CM_ "AUTOGENERATED FILE, DO NOT EDIT";

CM_ "ibooster_chassis.dbc starts here";

VERSION ""

NS_ :

BS_:

BU_:

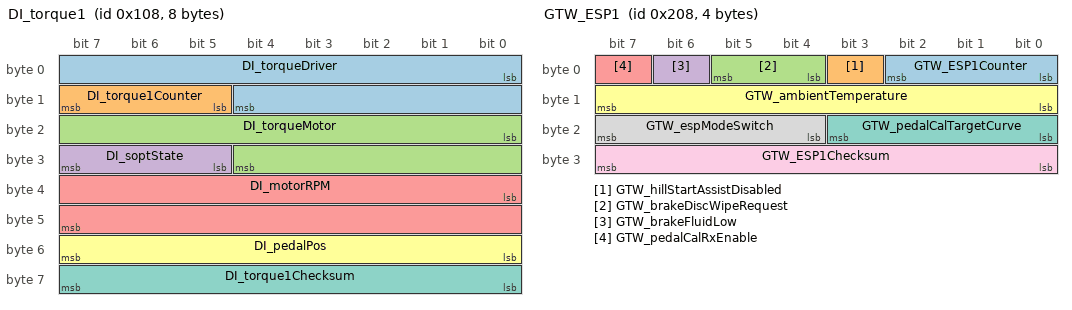
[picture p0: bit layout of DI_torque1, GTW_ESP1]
BO_ 264 DI_torque1: 8 GTW
 SG_ DI_torqueDriver : 0|13@1- (0.25,0) [-750|750] "Nm" DAS,ESP
 SG_ DI_torque1Counter : 13|3@1+ (1,0) [0|0] "" IBST,SDM,ESP,EPAS,EPAS2,EPAS3S,RCM,TAS2
 SG_ DI_torqueMotor : 16|13@1- (0.25,0) [-750|750] "Nm" APP,APS,ESP,TAS2
 SG_ DI_soptState : 29|3@1+ (1,0) [0|0] "" DBG
 SG_ DI_motorRPM : 32|16@1- (1,0) [-17000|17000] "RPM" IBST,SDM,RCM,ESP,EPAS,EPAS2,EPAS3S,EPB,EPBM,TAS2
 SG_ DI_pedalPos : 48|8@1+ (0.4,0) [0|100] "%" DAS,SDM,ESP,RCM,TAS2
 SG_ DI_torque1Checksum : 56|8@1+ (1,0) [0|0] "" IBST,SDM,ESP,EPAS,EPAS2,EPAS3S,RCM,TAS2

BO_ 516 EPB_status: 8 EPB
 SG_ EPB_state : 0|3@1+ (1,0) [0|0] "" IBST,DAS,ESP,PARK,GTW,EPBM,GTWU,RCM
 SG_ EPB_stateRequest : 3|3@1+ (1,0) [0|0] "" ESP,GTW
 SG_ EPB_brakeLight : 8|2@1+ (1,0) [0|0] "" GTW,BDY,BCCEN
 SG_ EPB_substateL : 10|3@1+ (1,0) [0|0] "" PARK,GTW,EPBM
 SG_ EPB_substateR : 13|3@1+ (1,0) [0|0] "" PARK,GTW,EPBM
 SG_ EPB_brakeHwTypeMismatch : 16|1@1+ (1,0) [0|1] "" GTW
 SG_ EPB_freeRollingModeStatus : 17|3@1+ (1,0) [0|0] "" GTW
 SG_ EPB_brakeApplied : 22|2@1+ (1,0) [0|0] "" GTW
 SG_ EPB_statePending : 24|3@1+ (1,0) [0|0] "" GTW
 SG_ EPB_calibrationStateLeft : 27|3@1+ (1,0) [0|0] "" GTW
 SG_ EPB_towModeEnabled : 32|1@1+ (1,0) [0|0] "" GTW,EPBM,GTWU
 SG_ EPB_requestUserConfirmation : 33|1@1+ (1,0) [0|0] "" GTW
 SG_ EPB_ignoreCan : 34|2@1+ (1,0) [0|3] "" GTW,EPBM,GTWU
 SG_ EPB_selfParkEnabled : 36|1@1+ (1,0) [0|3] "" GTW
 SG_ EPB_selfParkState : 37|3@1+ (1,0) [0|7] "" GTW
 SG_ EPB_mcuButtonAvailable : 40|1@1+ (1,0) [0|1] "" GTW
 SG_ EPB_telltale : 41|3@1+ (1,0) [0|0] "" GTW
 SG_ EPB_syncState : 44|3@1+ (1,0) [0|7] "" GTW
 SG_ EPB_calibrationStateRight : 47|3@1+ (1,0) [0|0] "" GTW
 SG_ EPB_statusCounter : 52|4@1+ (1,0) [0|15] "" IBST,ESP,GTW,RCM
 SG_ EPB_statusChecksum : 56|8@1+ (1,0) [0|255] "" IBST,ESP,GTW,RCM

BO_ 520 GTW_ESP1: 4 GTW
 SG_ GTW_ESP1Counter : 0|3@1+ (1,0) [0|1] "" IBST,ESP,TAS
 SG_ GTW_hillStartAssistDisabled : 3|1@1+ (1,0) [0|0] "" ESP
 SG_ GTW_brakeDiscWipeRequest : 4|2@1+ (1,0) [0|0] "" ESP
 SG_ GTW_brakeFluidLow : 6|1@1+ (1,0) [0|0] "" ESP
 SG_ GTW_pedalCalRxEnable : 7|1@1+ (1,0) [0|1] "" IBST
 SG_ GTW_ambientTemperature : 8|8@1+ (0.5,-40) [-40|60] "dgr. Celsius" BDY,BCCEN,ESP,TAS
 SG_ GTW_pedalCalTargetCurve : 16|4@1+ (1,0) [0|15] "" IBST
 SG_ GTW_espModeSwitch : 20|4@1+ (1,0) [0|15] "" ESP
 SG_ GTW_ESP1Checksum : 24|8@1+ (1,0) [0|0] "" IBST,ESP,TAS

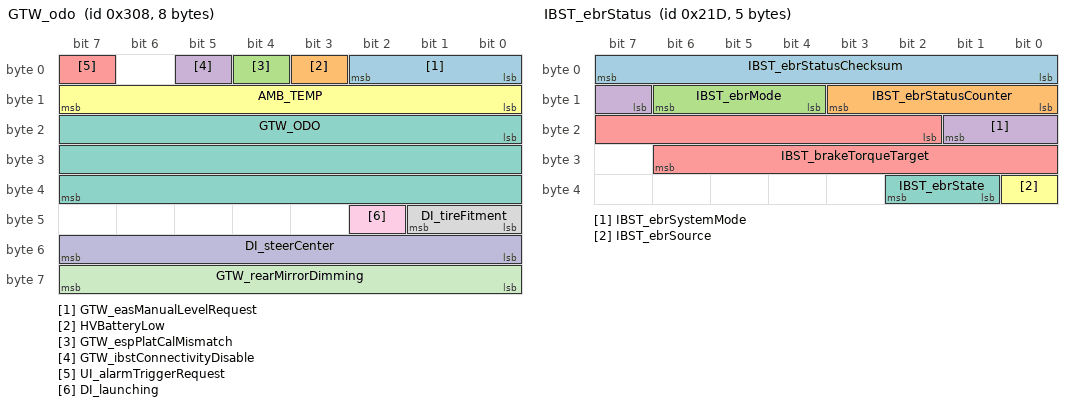
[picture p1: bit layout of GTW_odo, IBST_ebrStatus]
BO_ 776 GTW_odo: 8 GTW
 SG_ GTW_easManualLevelRequest : 0|3@1+ (1,0) [0|7] "" EAS
 SG_ HVBatteryLow : 3|1@1+ (1,0) [0|1] "" EAS,TAS
 SG_ GTW_espPlatCalMismatch : 4|1@1+ (1,0) [0|1] "" ESP
 SG_ GTW_ibstConnectivityDisable : 5|1@1+ (1,0) [0|1] "" IBST
 SG_ UI_alarmTriggerRequest : 7|1@0+ (1,0) [0|0] "" APP
 SG_ AMB_TEMP : 8|8@1+ (0.5,-40) [-40|87.5] "C" TPMS,PARK,EAS,EPB,EPBM,TAS,DAS,EPAS,EPAS2
 SG_ GTW_ODO : 16|24@1+ (0.1,0) [0|1677721.5] "km" ESP,RCM,EAS,RADAR,PARK,DAS
 SG_ DI_tireFitment : 40|2@1+ (1,0) [0|3] "" PARK,TAS2
 SG_ DI_launching : 42|1@1+ (1,0) [0|0] "" TAS2
 SG_ DI_steerCenter : 48|8@1- (0.2,0) [-25.6|25.4] "deg" TAS2
 SG_ GTW_rearMirrorDimming : 56|8@1+ (1,0) [0|255] "" APP

BO_ 840 GTW_status: 8 GTW
 SG_ GTW_driveRailReq : 0|1@0+ (1,0) [0|1] "" IBST,IC,EPB,EPBM,DAS,TAS
 SG_ GTW_brakePressed : 1|1@0+ (1,0) [0|0] "" EPB,EPBM
 SG_ GTW_driverPresent : 2|1@0+ (1,0) [0|0] "" DAS
 SG_ GTW_notEnough12VForDrive : 3|1@0+ (1,0) [0|0] "" EPB,EPBM
 SG_ GTW_icPowerOff : 4|1@0+ (1,0) [0|0] "" IC
 SG_ GTW_driverIsLeaving : 5|1@0+ (1,0) [0|0] "" EPB,EPBM
 SG_ GTW_accGoingDown : 6|1@0+ (1,0) [0|0] "" EPB,EPBM
 SG_ GTW_driveGoingDown : 7|1@0+ (1,0) [0|0] "" EPB,EPBM
 SG_ GTW_accRailReq : 8|1@0+ (1,0) [0|1] "" IBST,DAS,TAS,EPB,EPBM
 SG_ GTW_hvacRailReq : 9|1@0+ (1,0) [0|1] "" DAS
 SG_ GTW_preconditionCabinRequest : 10|1@0+ (1,0) [0|1] "" DAS
 SG_ GTW_hvacGoingDown : 11|1@1+ (1,0) [0|0] "" DAS
 SG_ GTW_ptBusAwake : 12|1@0+ (1,0) [0|0] "" EPB,EPBM
 SG_ GTW_mcuOff : 13|1@0+ (1,0) [0|0] "" APP
 SG_ GTW_hvacRailIsOn : 14|1@0+ (1,0) [0|0] "" APS
 SG_ GTW_gameModeAvailable : 15|1@0+ (1,0) [0|4] "" Vector__XXX
 SG_ GTW_vehiclePowerState : 16|1@0+ (1,0) [0|1] "" TAS
 SG_ GTW_driverIsLeavingAnySpeed : 17|1@0+ (1,0) [0|1] "" BCCEN
 SG_ DOOR_STATE_RearTrunk : 18|2@1+ (1,0) [0|3] "" EAS,TAS
 SG_ GTW_statusCounter : 51|4@0+ (1,0) [0|0] "" IC,TAS
 SG_ GTW_statusChecksum : 63|8@0+ (1,0) [0|0] "" IC,TAS

BO_ 1469 IBST_alertLog: 8 IBST
 SG_ IBST_alertID M : 0|15@1+ (1,0) [0|0] "" GTW
 SG_ IBST_alertType : 15|1@1+ (1,0) [0|0] "" GTW
 SG_ IBST_bmsInitTestFail m16384 : 16|1@1+ (1,0) [0|0] "" GTW
 SG_ IBST_bmcSingleTransTest m16385 : 16|1@1+ (1,0) [0|0] "" GTW
 SG_ IBST_tle5012SsccrcFail m16386 : 16|1@1+ (1,0) [0|0] "" GTW
 SG_ IBST_tle5012Config m16387 : 16|1@1+ (1,0) [0|0] "" GTW
 SG_ IBST_deadlMonTaskx1Ovr m16388 : 16|1@1+ (1,0) [0|0] "" GTW
 SG_ IBST_ecuWdFltCntTstFls m16389 : 16|1@1+ (1,0) [0|0] "" GTW
 SG_ IBST_ecuWdScheduleTout m16390 : 16|1@1+ (1,0) [0|0] "" GTW
 SG_ IBST_ecuWdStarttestFls m16391 : 16|1@1+ (1,0) [0|0] "" GTW
 SG_ IBST_ecuWdStatusContErr m16392 : 16|1@1+ (1,0) [0|0] "" GTW
 SG_ IBST_netOvrvolt m16393 : 16|1@1+ (1,0) [0|0] "" GTW
 SG_ IBST_micSpiTout m16394 : 16|1@1+ (1,0) [0|0] "" GTW
 SG_ IBST_micSpiTransferErr m16395 : 16|1@1+ (1,0) [0|0] "" GTW
 SG_ IBST_netUndvolt m16396 : 16|1@1+ (1,0) [0|0] "" GTW
 SG_ IBST_xpassToutErr m16397 : 16|1@1+ (1,0) [0|0] "" GTW
 SG_ IBST_rpsOffsEeReadEmpty m16398 : 16|1@1+ (1,0) [0|0] "" GTW
 SG_ IBST_rtpEnaHigh m16399 : 16|1@1+ (1,0) [0|0] "" GTW
 SG_ IBST_xpassEchoCountErr m16400 : 16|1@1+ (1,0) [0|0] "" GTW
 SG_ IBST_preDriveChckFail m16401 : 16|1@1+ (1,0) [0|0] "" GTW
 SG_ IBST_ucSafetyFlt m16402 : 16|1@1+ (1,0) [0|0] "" GTW
 SG_ IBST_unsupportedHw m16403 : 16|1@1+ (1,0) [0|0] "" GTW
 SG_ IBST_voltPreRegModeFld m16404 : 16|1@1+ (1,0) [0|0] "" GTW
 SG_ IBST_ubbSupplyLine m16405 : 16|1@1+ (1,0) [0|0] "" GTW
 SG_ IBST_stmAswSysTout m16406 : 16|1@1+ (1,0) [0|0] "" GTW
 SG_ IBST_stackOvrUndFlow m16407 : 16|1@1+ (1,0) [0|0] "" GTW
 SG_ IBST_smmOneReqsInit m16408 : 16|1@1+ (1,0) [0|0] "" GTW
 SG_ IBST_ptsSupply m16409 : 16|1@1+ (1,0) [0|0] "" GTW
 SG_ IBST_ptsSupplyUndvolt m16410 : 16|1@1+ (1,0) [0|0] "" GTW
 SG_ IBST_tempB6Plaus m16411 : 16|1@1+ (1,0) [0|0] "" GTW
 SG_ IBST_ecuWdErrCntContErr m16412 : 16|1@1+ (1,0) [0|0] "" GTW
 SG_ IBST_bmcShortedGateTest m16413 : 16|1@1+ (1,0) [0|0] "" GTW
 SG_ IBST_controllerDevTooBig m16414 : 16|1@1+ (1,0) [0|0] "" GTW
 SG_ IBST_ibDtrFail m16415 : 16|1@1+ (1,0) [0|0] "" GTW
 SG_ IBST_oc6InitTestFail m16416 : 16|1@1+ (1,0) [0|0] "" GTW
 SG_ IBST_oc6Monitor m16417 : 16|1@1+ (1,0) [0|0] "" GTW
 SG_ IBST_motorOscillationDet m16418 : 16|1@1+ (1,0) [0|0] "" GTW
 SG_ IBST_rpsOffsEeReadFail m16419 : 16|1@1+ (1,0) [0|0] "" GTW
 SG_ IBST_sysErrHook m16420 : 16|1@1+ (1,0) [0|0] "" GTW
 SG_ IBST_calIdlePosNotPlaus m16421 : 16|1@1+ (1,0) [0|0] "" GTW
 SG_ IBST_boostSupUndrvolt m16422 : 16|1@1+ (1,0) [0|0] "" GTW
 SG_ IBST_calRoutineAbort m16423 : 16|1@1+ (1,0) [0|0] "" GTW
 SG_ IBST_bmcGateUndervoltPro m16424 : 16|1@1+ (1,0) [0|0] "" GTW
 SG_ IBST_hswInitPhseUndrvolt m16425 : 16|1@1+ (1,0) [0|0] "" GTW
 SG_ IBST_ltmWarnLevelReached m16426 : 16|1@1+ (1,0) [0|0] "" GTW
 SG_ IBST_rpsVctrLengthRelErr m16427 : 16|1@1+ (1,0) [0|0] "" GTW
 SG_ IBST_b6TempDegradeLevel1 m16428 : 16|1@1+ (1,0) [0|0] "" GTW
 SG_ IBST_B6TempDegradeLevel2 m16429 : 16|1@1+ (1,0) [0|0] "" GTW
 SG_ IBST_spiAnglOrRawNotUp m16430 : 16|1@1+ (1,0) [0|0] "" GTW
 SG_ IBST_dcomIboosterNotInit m16431 : 16|1@1+ (1,0) [0|0] "" GTW
 SG_ IBST_unintendMotorReturn m16432 : 16|1@1+ (1,0) [0|0] "" GTW
 SG_ IBST_cdmOvrvoltLevel1 m16433 : 16|1@1+ (1,0) [0|0] "" GTW
 SG_ IBST_cdmUndrvoltLevel2 m16434 : 16|1@1+ (1,0) [0|0] "" GTW
 SG_ IBST_cdmUndrvoltLevel1 m16435 : 16|1@1+ (1,0) [0|0] "" GTW
 SG_ IBST_motTrvlRelReadFail m16436 : 16|1@1+ (1,0) [0|0] "" GTW
 SG_ IBST_tle5012UnexpReset m16437 : 16|1@1+ (1,0) [0|0] "" GTW
 SG_ IBST_bmsGateUndrvolt m16438 : 16|1@1+ (1,0) [0|0] "" GTW
 SG_ IBST_kl15HwPlausSw m16439 : 16|1@1+ (1,0) [0|0] "" GTW
 SG_ IBST_ibNotShutDownRight m16440 : 16|1@1+ (1,0) [0|0] "" GTW
 SG_ IBST_cdmHardUndrvolt m16441 : 16|1@1+ (1,0) [0|0] "" GTW
 SG_ IBST_cdmHardOvrvolt m16442 : 16|1@1+ (1,0) [0|0] "" GTW
 SG_ IBST_maxTrvlAdjstUpdFail m16443 : 16|1@1+ (1,0) [0|0] "" GTW
 SG_ IBST_ltmLimitReached m16444 : 16|1@1+ (1,0) [0|0] "" GTW
 SG_ IBST_dcomEcuDefect m16445 : 16|1@1+ (1,0) [0|0] "" GTW
 SG_ IBST_inputStroke1RngHigh m16446 : 16|1@1+ (1,0) [0|0] "" GTW
 SG_ IBST_inputStroke1RngLow m16447 : 16|1@1+ (1,0) [0|0] "" GTW
 SG_ IBST_inputStroke2RngHigh m16448 : 16|1@1+ (1,0) [0|0] "" GTW
 SG_ IBST_inputStroke2RngLow m16449 : 16|1@1+ (1,0) [0|0] "" GTW
 SG_ IBST_ibSupVoltDivDrift m16450 : 16|1@1+ (1,0) [0|0] "" GTW
 SG_ IBST_sOutRodToPressVal m16451 : 16|1@1+ (1,0) [0|0] "" GTW
 SG_ IBST_tle5012LifeCnt m16452 : 16|1@1+ (1,0) [0|0] "" GTW
 SG_ IBST_cdmExtendedUndrvolt m16453 : 16|1@1+ (1,0) [0|0] "" GTW
 SG_ IBST_cdmExtendedOvrvolt m16454 : 16|1@1+ (1,0) [0|0] "" GTW
 SG_ IBST_tempB6Ch1LineHigh m16455 : 16|1@1+ (1,0) [0|0] "" GTW
 SG_ IBST_tempB6Ch1LineLow m16456 : 16|1@1+ (1,0) [0|0] "" GTW
 SG_ IBST_tempB6Ch2LineHigh m16457 : 16|1@1+ (1,0) [0|0] "" GTW
 SG_ IBST_tempB6Ch2LineLow m16458 : 16|1@1+ (1,0) [0|0] "" GTW
 SG_ IBST_hevSwitchOffDcom m16459 : 16|1@1+ (1,0) [0|0] "" GTW
 SG_ IBST_tle5012VoltFail m16460 : 16|1@1+ (1,0) [0|0] "" GTW
 SG_ IBST_bcsFltCurrentHigh m16461 : 16|1@1+ (1,0) [0|0] "" GTW
 SG_ IBST_bcsFltCurrentLow m16462 : 16|1@1+ (1,0) [0|0] "" GTW
 SG_ IBST_ecuSupVoltDivDrift m16463 : 16|1@1+ (1,0) [0|0] "" GTW
 SG_ IBST_inputstroke1Grad m16464 : 16|1@1+ (1,0) [0|0] "" GTW
 SG_ IBST_pts1Err m16465 : 16|1@1+ (1,0) [0|0] "" GTW
 SG_ IBST_pts1LineGnd m16466 : 16|1@1+ (1,0) [0|0] "" GTW
 SG_ IBST_pts1LineHigh m16467 : 16|1@1+ (1,0) [0|0] "" GTW
 SG_ IBST_inputStroke2Grad m16468 : 16|1@1+ (1,0) [0|0] "" GTW
 SG_ IBST_pts2Err m16469 : 16|1@1+ (1,0) [0|0] "" GTW
 SG_ IBST_pts2LineGnd m16470 : 16|1@1+ (1,0) [0|0] "" GTW
 SG_ IBST_pts2LineHigh m16471 : 16|1@1+ (1,0) [0|0] "" GTW
 SG_ IBST_faildevInputStroke m16472 : 16|1@1+ (1,0) [0|0] "" GTW
 SG_ IBST_ptsOffsTooHigh m16473 : 16|1@1+ (1,0) [0|0] "" GTW
 SG_ IBST_pbistErr m16474 : 16|1@1+ (1,0) [0|0] "" GTW
 SG_ IBST_ramInitErr m16475 : 16|1@1+ (1,0) [0|0] "" GTW
 SG_ IBST_ramsinlgeFlt m16476 : 16|1@1+ (1,0) [0|0] "" GTW
 SG_ IBST_bertFlt m16477 : 16|1@1+ (1,0) [0|0] "" GTW
 SG_ IBST_CalDataNotPlaus m16478 : 16|1@1+ (1,0) [0|0] "" GTW
 SG_ IBST_canEHwError m16479 : 16|1@1+ (1,0) [0|0] "" GTW
 SG_ IBST_canETout m16480 : 16|1@1+ (1,0) [0|0] "" GTW
 SG_ IBST_cpuException m16481 : 16|1@1+ (1,0) [0|0] "" GTW
 SG_ IBST_ecuBandGap m16482 : 16|1@1+ (1,0) [0|0] "" GTW
 SG_ IBST_ecuBmsOnWhileWdTout m16483 : 16|1@1+ (1,0) [0|0] "" GTW
 SG_ IBST_ecuErrpinCntTstFls m16484 : 16|1@1+ (1,0) [0|0] "" GTW
 SG_ IBST_ecuHetException m16485 : 16|1@1+ (1,0) [0|0] "" GTW
 SG_ IBST_ecuHetTuAddErr m16486 : 16|1@1+ (1,0) [0|0] "" GTW
 SG_ IBST_ecuHetTuBusErr m16487 : 16|1@1+ (1,0) [0|0] "" GTW
 SG_ IBST_ecuHetTuBusyErr m16488 : 16|1@1+ (1,0) [0|0] "" GTW
 SG_ IBST_ecuHetTuException m16489 : 16|1@1+ (1,0) [0|0] "" GTW
 SG_ IBST_ecuTaskMissing m16490 : 16|1@1+ (1,0) [0|0] "" GTW
 SG_ IBST_hetRefError m16491 : 16|1@1+ (1,0) [0|0] "" GTW
 SG_ IBST_micInitSpiTstFld m16492 : 16|1@1+ (1,0) [0|0] "" GTW
 SG_ IBST_micInitSpiTransfErr m16493 : 16|1@1+ (1,0) [0|0] "" GTW
 SG_ IBST_micIntMonGenBitMon m16494 : 16|1@1+ (1,0) [0|0] "" GTW
 SG_ IBST_micIntVoltMonFld m16495 : 16|1@1+ (1,0) [0|0] "" GTW
 SG_ IBST_motPosTrvlReadEmpty m16496 : 16|1@1+ (1,0) [0|0] "" GTW
 SG_ IBST_motAngBoundReadEmpt m16497 : 16|1@1+ (1,0) [0|0] "" GTW
 SG_ IBST_motShaftShiftDetect m16498 : 16|1@1+ (1,0) [0|0] "" GTW
 SG_ IBST_osErrHook m16499 : 16|1@1+ (1,0) [0|0] "" GTW
 SG_ IBST_pdurEInitFail m16500 : 16|1@1+ (1,0) [0|0] "" GTW
 SG_ IBST_pdurEPduInstLost m16501 : 16|1@1+ (1,0) [0|0] "" GTW
 SG_ IBST_pts1OffsEeReadEmpty m16502 : 16|1@1+ (1,0) [0|0] "" GTW
 SG_ IBST_pts2OffsEeReadEmpty m16503 : 16|1@1+ (1,0) [0|0] "" GTW
 SG_ IBST_rpsOffsXEeReadFail m16504 : 16|1@1+ (1,0) [0|0] "" GTW
 SG_ IBST_rpsOffsYEeReadFail m16505 : 16|1@1+ (1,0) [0|0] "" GTW
 SG_ IBST_rpsSynchEeReadFail m16506 : 16|1@1+ (1,0) [0|0] "" GTW
 SG_ IBST_rpsAnglRecalcErr m16507 : 16|1@1+ (1,0) [0|0] "" GTW
 SG_ IBST_motTrvlRelWriteFail m16508 : 16|1@1+ (1,0) [0|0] "" GTW
 SG_ IBST_motTrvlRelReadEmpty m16509 : 16|1@1+ (1,0) [0|0] "" GTW
 SG_ IBST_ptsEeReadEmpty m16510 : 16|1@1+ (1,0) [0|0] "" GTW
 SG_ IBST_ecuAdcConversionErr m16511 : 16|1@1+ (1,0) [0|0] "" GTW
 SG_ IBST_ecuAdcSelftestErr m16512 : 16|1@1+ (1,0) [0|0] "" GTW
 SG_ IBST_ccmFlt m16513 : 16|1@1+ (1,0) [0|0] "" GTW
 SG_ IBST_ecuRomCheck m16514 : 16|1@1+ (1,0) [0|0] "" GTW
 SG_ IBST_esmNmiFlt m16515 : 16|1@1+ (1,0) [0|0] "" GTW
 SG_ IBST_esmSafetyFlt m16516 : 16|1@1+ (1,0) [0|0] "" GTW
 SG_ IBST_motPosTrvlReadFail m16517 : 16|1@1+ (1,0) [0|0] "" GTW
 SG_ IBST_motPosTrvlWriteFail m16518 : 16|1@1+ (1,0) [0|0] "" GTW
 SG_ IBST_motAnglBndReadErr m16519 : 16|1@1+ (1,0) [0|0] "" GTW
 SG_ IBST_motAnglBndWriteErr m16520 : 16|1@1+ (1,0) [0|0] "" GTW
 SG_ IBST_motAnglGradTooLarge m16521 : 16|1@1+ (1,0) [0|0] "" GTW
 SG_ IBST_pdmCustomerIdMis m16522 : 16|1@1+ (1,0) [0|0] "" GTW
 SG_ IBST_pdmDtFormatMis m16523 : 16|1@1+ (1,0) [0|0] "" GTW
 SG_ IBST_pdmOutOfMemory m16524 : 16|1@1+ (1,0) [0|0] "" GTW
 SG_ IBST_pdmFieldSizeMis m16525 : 16|1@1+ (1,0) [0|0] "" GTW
 SG_ IBST_pdmHwAcsErr m16526 : 16|1@1+ (1,0) [0|0] "" GTW
 SG_ IBST_pdmMaxWriteCycles m16526 : 17|1@1+ (1,0) [0|0] "" GTW
 SG_ IBST_pdmInternalHWErr m16527 : 16|1@1+ (1,0) [0|0] "" GTW
 SG_ IBST_ptsCalHysWritFail m16528 : 16|1@1+ (1,0) [0|0] "" GTW
 SG_ IBST_ptsCalValuesChkFail m16529 : 16|1@1+ (1,0) [0|0] "" GTW
 SG_ IBST_pts1CalEeReadFail m16530 : 16|1@1+ (1,0) [0|0] "" GTW
 SG_ IBST_pts1CalEeWriteFail m16531 : 16|1@1+ (1,0) [0|0] "" GTW
 SG_ IBST_rpsFailCompErr m16532 : 16|1@1+ (1,0) [0|0] "" GTW
 SG_ IBST_pts1OffsEeWriteFail m16533 : 16|1@1+ (1,0) [0|0] "" GTW
 SG_ IBST_pts2CalEeReadFail m16534 : 16|1@1+ (1,0) [0|0] "" GTW
 SG_ IBST_pts2CalEeWriteFail m16535 : 16|1@1+ (1,0) [0|0] "" GTW
 SG_ IBST_pts2OffsEeReadFail m16536 : 16|1@1+ (1,0) [0|0] "" GTW
 SG_ IBST_pts2OffsEeWriteFail m16537 : 16|1@1+ (1,0) [0|0] "" GTW
 SG_ IBST_rpsOffsXEeReadEmpty m16538 : 16|1@1+ (1,0) [0|0] "" GTW
 SG_ IBST_rpsOffsXEeWriteFail m16539 : 16|1@1+ (1,0) [0|0] "" GTW
 SG_ IBST_rpsOffsYEeReadEmpty m16540 : 16|1@1+ (1,0) [0|0] "" GTW
 SG_ IBST_rpsOffsYEeWriteFail m16541 : 16|1@1+ (1,0) [0|0] "" GTW
 SG_ IBST_rpsSynchEeReadEmpty m16542 : 16|1@1+ (1,0) [0|0] "" GTW
 SG_ IBST_rpsSynchEeWriteFail m16543 : 16|1@1+ (1,0) [0|0] "" GTW
 SG_ IBST_assertionFail m16544 : 16|1@1+ (1,0) [0|0] "" GTW
 SG_ IBST_comsclBrkPrsPduLen m16545 : 16|1@1+ (1,0) [0|0] "" GTW
 SG_ IBST_comsclBrkPrsPduTout m16546 : 16|1@1+ (1,0) [0|0] "" GTW
 SG_ IBST_comsclEspIb1CntErr m16547 : 16|1@1+ (1,0) [0|0] "" GTW
 SG_ IBST_comsclEspIb1CsErr m16548 : 16|1@1+ (1,0) [0|0] "" GTW
 SG_ IBST_comsclEspIb1DlcErr m16549 : 16|1@1+ (1,0) [0|0] "" GTW
 SG_ IBST_comsclEspIb1Tout m16550 : 16|1@1+ (1,0) [0|0] "" GTW
 SG_ IBST_comsclEspIb2CntErr m16551 : 16|1@1+ (1,0) [0|0] "" GTW
 SG_ IBST_comsclEspIb2CsErr m16552 : 16|1@1+ (1,0) [0|0] "" GTW
 SG_ IBST_comsclEspIb2DlcErr m16553 : 16|1@1+ (1,0) [0|0] "" GTW
 SG_ IBST_comsclEspIb2Tout m16554 : 16|1@1+ (1,0) [0|0] "" GTW
 SG_ IBST_comsclEspIb3CntErr m16555 : 16|1@1+ (1,0) [0|0] "" GTW
 SG_ IBST_comsclEspIb3CsErr m16556 : 16|1@1+ (1,0) [0|0] "" GTW
 SG_ IBST_comsclEspIb3DlcErr m16557 : 16|1@1+ (1,0) [0|0] "" GTW
 SG_ IBST_comsclEspIb3Tout m16558 : 16|1@1+ (1,0) [0|0] "" GTW
 SG_ IBST_comsclGtwEsp1CntErr m16559 : 16|1@1+ (1,0) [0|0] "" GTW
 SG_ IBST_comsclGtwEsp1CsErr m16560 : 16|1@1+ (1,0) [0|0] "" GTW
 SG_ IBST_comsclGtwEsp1Corrpt m16561 : 16|1@1+ (1,0) [0|0] "" GTW
 SG_ IBST_comsclGtwEsp1Tout m16562 : 16|1@1+ (1,0) [0|0] "" GTW
 SG_ IBST_dcomSmrtActuNotInit m16563 : 16|1@1+ (1,0) [0|0] "" GTW
 SG_ IBST_rpsLengthAbsolHigh m16564 : 16|1@1+ (1,0) [0|0] "" GTW
 SG_ IBST_rpsLengthAbsolLow m16565 : 16|1@1+ (1,0) [0|0] "" GTW
 SG_ IBST_shutDownEeReadFail m16566 : 16|1@1+ (1,0) [0|0] "" GTW
 SG_ IBST_shutDownEeWriteFail m16567 : 16|1@1+ (1,0) [0|0] "" GTW
 SG_ IBST_maxTrvlAdjstReadErr m16568 : 16|1@1+ (1,0) [0|0] "" GTW
 SG_ IBST_psOffsMcEeReadFail m16569 : 16|1@1+ (1,0) [0|0] "" GTW
 SG_ IBST_psOffsMcEeWriteFail m16570 : 16|1@1+ (1,0) [0|0] "" GTW
 SG_ IBST_ltmSelfProtDeact m16571 : 16|1@1+ (1,0) [0|0] "" GTW
 SG_ IBST_pts1OffsEeReadFail m16572 : 16|1@1+ (1,0) [0|0] "" GTW
 SG_ IBST_diffStrokeRange m16573 : 16|1@1+ (1,0) [0|0] "" GTW
 SG_ IBST_notProgVin m16574 : 16|1@1+ (1,0) [0|0] "" GTW
 SG_ IBST_plausVin m16575 : 16|1@1+ (1,0) [0|0] "" GTW
 SG_ IBST_dlCorCSumVin m16576 : 16|1@1+ (1,0) [0|0] "" GTW
 SG_ IBST_ToutVin m16577 : 16|1@1+ (1,0) [0|0] "" GTW
 SG_ IBST_ecuEnableB6Fail m16578 : 16|1@1+ (1,0) [0|0] "" GTW
 SG_ IBST_ecuIbEnContErr m16579 : 16|1@1+ (1,0) [0|0] "" GTW
 SG_ IBST_sclEspIb1pEstMax m16580 : 16|1@1+ (1,0) [0|0] "" GTW
 SG_ IBST_sclEspIb1VehSpd m16581 : 16|1@1+ (1,0) [0|0] "" GTW
 SG_ IBST_sclEspIb2pLimExt m16582 : 16|1@1+ (1,0) [0|0] "" GTW
 SG_ IBST_sclEspIb2qTarExt m16583 : 16|1@1+ (1,0) [0|0] "" GTW
 SG_ IBST_sclEspIb3pFBlend m16584 : 16|1@1+ (1,0) [0|0] "" GTW
 SG_ IBST_sclEspIb3pMc1 m16585 : 16|1@1+ (1,0) [0|0] "" GTW
 SG_ IBST_sclEspIb3pTarDriver m16586 : 16|1@1+ (1,0) [0|0] "" GTW
 SG_ IBST_netBusOffNet0 m16587 : 16|1@1+ (1,0) [0|0] "" GTW
 SG_ IBST_netErrPassivNet0 m16588 : 16|1@1+ (1,0) [0|0] "" GTW
 SG_ IBST_netBusOffNet1 m16589 : 16|1@1+ (1,0) [0|0] "" GTW
 SG_ IBST_netErrPassivNet1 m16590 : 16|1@1+ (1,0) [0|0] "" GTW
 SG_ IBST_maxStrokeReached m16591 : 16|1@1+ (1,0) [0|0] "" GTW
 SG_ IBST_sysSwClockMismatch m16592 : 16|1@1+ (1,0) [0|0] "" GTW
 SG_ IBST_comsclGtwOdoCorrpt m16593 : 16|1@1+ (1,0) [0|0] "" GTW
 SG_ IBST_comsclGtwStatCorrpt m16594 : 16|1@1+ (1,0) [0|0] "" GTW
 SG_ IBST_comsclEpbStatCorrpt m16595 : 16|1@1+ (1,0) [0|0] "" GTW
 SG_ IBST_comsclGtwOdoTout m16596 : 16|1@1+ (1,0) [0|0] "" GTW
 SG_ IBST_comsclGtwStatTout m16597 : 16|1@1+ (1,0) [0|0] "" GTW
 SG_ IBST_comsclEpbStatTout m16598 : 16|1@1+ (1,0) [0|0] "" GTW
 SG_ IBST_comSclEpbStatCsErr m16599 : 16|1@1+ (1,0) [0|0] "" GTW
 SG_ IBST_comSclEpbStatCntFlt m16600 : 16|1@1+ (1,0) [0|0] "" GTW
 SG_ IBST_comSclDiTrq1Tout m16601 : 16|1@1+ (1,0) [0|0] "" GTW
 SG_ IBST_comSclDiTrq1Corrpt m16602 : 16|1@1+ (1,0) [0|0] "" GTW
 SG_ IBST_comSclDiTrq1CsErr m16603 : 16|1@1+ (1,0) [0|0] "" GTW
 SG_ IBST_comSclDiTrq1CntFlt m16604 : 16|1@1+ (1,0) [0|0] "" GTW

BO_ 1645 IBST_bootID: 8 IBST
 SG_ IBST_bootIdData : 0|64@1+ (1,0) [0|0] "" Vector__XXX

BO_ 861 IBST_dtcMatrix: 8 IBST
 SG_ IBST_dtcIndex M : 0|8@1+ (1,0) [0|255] "" GTW
 SG_ IBST_d000_bmsInitTestFail m0 : 8|2@1+ (1,0) [0|0] "" GTW
 SG_ IBST_d001_bmcSingleTransTest m0 : 10|2@1+ (1,0) [0|0] "" GTW
 SG_ IBST_d002_tle5012SsccrcFail m0 : 12|2@1+ (1,0) [0|0] "" GTW
 SG_ IBST_d003_tle5012Config m0 : 14|2@1+ (1,0) [0|0] "" GTW
 SG_ IBST_d004_deadlMonTaskx1Ovr m0 : 16|2@1+ (1,0) [0|0] "" GTW
 SG_ IBST_d005_ecuWdFltCntTstFls m0 : 18|2@1+ (1,0) [0|0] "" GTW
 SG_ IBST_d006_ecuWdScheduleTout m0 : 20|2@1+ (1,0) [0|0] "" GTW
 SG_ IBST_d007_ecuWdStarttestFls m0 : 22|2@1+ (1,0) [0|0] "" GTW
 SG_ IBST_d008_ecuWdStatusContErr m0 : 24|2@1+ (1,0) [0|0] "" GTW
 SG_ IBST_d009_netOvrvolt m0 : 26|2@1+ (1,0) [0|0] "" GTW
 SG_ IBST_d010_micSpiTout m0 : 28|2@1+ (1,0) [0|0] "" GTW
 SG_ IBST_d011_micSpiTransferErr m0 : 30|2@1+ (1,0) [0|0] "" GTW
 SG_ IBST_d012_netUndvolt m0 : 32|2@1+ (1,0) [0|0] "" GTW
 SG_ IBST_d013_xpassToutErr m0 : 34|2@1+ (1,0) [0|0] "" GTW
 SG_ IBST_d014_rpsOffsEeReadEmpty m0 : 36|2@1+ (1,0) [0|0] "" GTW
 SG_ IBST_d015_rtpEnaHigh m0 : 38|2@1+ (1,0) [0|0] "" GTW
 SG_ IBST_d016_xpassEchoCountErr m0 : 40|2@1+ (1,0) [0|0] "" GTW
 SG_ IBST_d017_preDriveChckFail m0 : 42|2@1+ (1,0) [0|0] "" GTW
 SG_ IBST_d018_ucSafetyFlt m0 : 44|2@1+ (1,0) [0|0] "" GTW
 SG_ IBST_d019_unsupportedHw m0 : 46|2@1+ (1,0) [0|0] "" GTW
 SG_ IBST_d020_voltPreRegModeFld m0 : 48|2@1+ (1,0) [0|0] "" GTW
 SG_ IBST_d021_ubbSupplyLine m0 : 50|2@1+ (1,0) [0|0] "" GTW
 SG_ IBST_d022_stmAswSysTout m0 : 52|2@1+ (1,0) [0|0] "" GTW
 SG_ IBST_d023_stackOvrUndFlow m0 : 54|2@1+ (1,0) [0|0] "" GTW
 SG_ IBST_d024_smmOneReqsInit m0 : 56|2@1+ (1,0) [0|0] "" GTW
 SG_ IBST_d025_ptsSupply m0 : 58|2@1+ (1,0) [0|0] "" GTW
 SG_ IBST_d026_ptsSupplyUndvolt m0 : 60|2@1+ (1,0) [0|0] "" GTW
 SG_ IBST_d027_tempB6Plaus m0 : 62|2@1+ (1,0) [0|0] "" GTW
 SG_ IBST_d028_ecuWdErrCntContErr m1 : 8|2@1+ (1,0) [0|0] "" GTW
 SG_ IBST_d029_bmcShortedGateTest m1 : 10|2@1+ (1,0) [0|0] "" GTW
 SG_ IBST_d030_controllerDevTooBig m1 : 12|2@1+ (1,0) [0|0] "" GTW
 SG_ IBST_d031_ibDtrFail m1 : 14|2@1+ (1,0) [0|0] "" GTW
 SG_ IBST_d032_oc6InitTestFail m1 : 16|2@1+ (1,0) [0|0] "" GTW
 SG_ IBST_d033_oc6Monitor m1 : 18|2@1+ (1,0) [0|0] "" GTW
 SG_ IBST_d034_motorOscillationDet m1 : 20|2@1+ (1,0) [0|0] "" GTW
 SG_ IBST_d035_rpsOffsEeReadFail m1 : 22|2@1+ (1,0) [0|0] "" GTW
 SG_ IBST_d036_sysErrHook m1 : 24|2@1+ (1,0) [0|0] "" GTW
 SG_ IBST_d037_calIdlePosNotPlaus m1 : 26|2@1+ (1,0) [0|0] "" GTW
 SG_ IBST_d038_boostSupUndrvolt m1 : 28|2@1+ (1,0) [0|0] "" GTW
 SG_ IBST_d039_calRoutineAbort m1 : 30|2@1+ (1,0) [0|0] "" GTW
 SG_ IBST_d040_bmcGateUndervoltPro m1 : 32|2@1+ (1,0) [0|0] "" GTW
 SG_ IBST_d041_hswInitPhseUndrvolt m1 : 34|2@1+ (1,0) [0|0] "" GTW
 SG_ IBST_d042_ltmWarnLevelReached m1 : 36|2@1+ (1,0) [0|0] "" GTW
 SG_ IBST_d043_rpsVctrLengthRelErr m1 : 38|2@1+ (1,0) [0|0] "" GTW
 SG_ IBST_d044_b6TempDegradeLevel1 m1 : 40|2@1+ (1,0) [0|0] "" GTW
 SG_ IBST_d045_B6TempDegradeLevel2 m1 : 42|2@1+ (1,0) [0|0] "" GTW
 SG_ IBST_d046_spiAnglOrRawNotUp m1 : 44|2@1+ (1,0) [0|0] "" GTW
 SG_ IBST_d047_dcomIboosterNotInit m1 : 46|2@1+ (1,0) [0|0] "" GTW
 SG_ IBST_d048_unintendMotorReturn m1 : 48|2@1+ (1,0) [0|0] "" GTW
 SG_ IBST_d049_cdmOvrvoltLevel1 m1 : 50|2@1+ (1,0) [0|0] "" GTW
 SG_ IBST_d050_cdmUndrvoltLevel2 m1 : 52|2@1+ (1,0) [0|0] "" GTW
 SG_ IBST_d051_cdmUndrvoltLevel1 m1 : 54|2@1+ (1,0) [0|0] "" GTW
 SG_ IBST_d052_motTrvlRelReadFail m1 : 56|2@1+ (1,0) [0|0] "" GTW
 SG_ IBST_d053_tle5012UnexpReset m1 : 58|2@1+ (1,0) [0|0] "" GTW
 SG_ IBST_d054_bmsGateUndrvolt m1 : 60|2@1+ (1,0) [0|0] "" GTW
 SG_ IBST_d055_kl15HwPlausSw m1 : 62|2@1+ (1,0) [0|0] "" GTW
 SG_ IBST_d056_ibNotShutDownRight m2 : 8|2@1+ (1,0) [0|0] "" GTW
 SG_ IBST_d057_cdmHardUndrvolt m2 : 10|2@1+ (1,0) [0|0] "" GTW
 SG_ IBST_d058_cdmHardOvrvolt m2 : 12|2@1+ (1,0) [0|0] "" GTW
 SG_ IBST_d059_maxTrvlAdjstUpdFail m2 : 14|2@1+ (1,0) [0|0] "" GTW
 SG_ IBST_d060_ltmLimitReached m2 : 16|2@1+ (1,0) [0|0] "" GTW
 SG_ IBST_d061_dcomEcuDefect m2 : 18|2@1+ (1,0) [0|0] "" GTW
 SG_ IBST_d062_inputStroke1RngHigh m2 : 20|2@1+ (1,0) [0|0] "" GTW
 SG_ IBST_d063_inputStroke1RngLow m2 : 22|2@1+ (1,0) [0|0] "" GTW
 SG_ IBST_d064_inputStroke2RngHigh m2 : 24|2@1+ (1,0) [0|0] "" GTW
 SG_ IBST_d065_inputStroke2RngLow m2 : 26|2@1+ (1,0) [0|0] "" GTW
 SG_ IBST_d066_ibSupVoltDivDrift m2 : 28|2@1+ (1,0) [0|0] "" GTW
 SG_ IBST_d067_sOutRodToPressVal m2 : 30|2@1+ (1,0) [0|0] "" GTW
 SG_ IBST_d068_tle5012LifeCnt m2 : 32|2@1+ (1,0) [0|0] "" GTW
 SG_ IBST_d069_cdmExtendedUndrvolt m2 : 34|2@1+ (1,0) [0|0] "" GTW
 SG_ IBST_d070_cdmExtendedOvrvolt m2 : 36|2@1+ (1,0) [0|0] "" GTW
 SG_ IBST_d071_tempB6Ch1LineHigh m2 : 38|2@1+ (1,0) [0|0] "" GTW
 SG_ IBST_d072_tempB6Ch1LineLow m2 : 40|2@1+ (1,0) [0|0] "" GTW
 SG_ IBST_d073_tempB6Ch2LineHigh m2 : 42|2@1+ (1,0) [0|0] "" GTW
 SG_ IBST_d074_tempB6Ch2LineLow m2 : 44|2@1+ (1,0) [0|0] "" GTW
 SG_ IBST_d075_hevSwitchOffDcom m2 : 46|2@1+ (1,0) [0|0] "" GTW
 SG_ IBST_d076_tle5012VoltFail m2 : 48|2@1+ (1,0) [0|0] "" GTW
 SG_ IBST_d077_bcsFltCurrentHigh m2 : 50|2@1+ (1,0) [0|0] "" GTW
 SG_ IBST_d078_bcsFltCurrentLow m2 : 52|2@1+ (1,0) [0|0] "" GTW
 SG_ IBST_d079_ecuSupVoltDivDrift m2 : 54|2@1+ (1,0) [0|0] "" GTW
 SG_ IBST_d080_inputstroke1Grad m2 : 56|2@1+ (1,0) [0|0] "" GTW
 SG_ IBST_d081_pts1Err m2 : 58|2@1+ (1,0) [0|0] "" GTW
 SG_ IBST_d082_pts1LineGnd m2 : 60|2@1+ (1,0) [0|0] "" GTW
 SG_ IBST_d083_pts1LineHigh m2 : 62|2@1+ (1,0) [0|0] "" GTW
 SG_ IBST_d084_inputStroke2Grad m3 : 8|2@1+ (1,0) [0|0] "" GTW
 SG_ IBST_d085_pts2Err m3 : 10|2@1+ (1,0) [0|0] "" GTW
 SG_ IBST_d086_pts2LineGnd m3 : 12|2@1+ (1,0) [0|0] "" GTW
 SG_ IBST_d087_pts2LineHigh m3 : 14|2@1+ (1,0) [0|0] "" GTW
 SG_ IBST_d088_faildevInputStroke m3 : 16|2@1+ (1,0) [0|0] "" GTW
 SG_ IBST_d089_ptsOffsTooHigh m3 : 18|2@1+ (1,0) [0|0] "" GTW
 SG_ IBST_d090_pbistErr m3 : 20|2@1+ (1,0) [0|0] "" GTW
 SG_ IBST_d091_ramInitErr m3 : 22|2@1+ (1,0) [0|0] "" GTW
 SG_ IBST_d092_ramsinlgeFlt m3 : 24|2@1+ (1,0) [0|0] "" GTW
 SG_ IBST_d093_bertFlt m3 : 26|2@1+ (1,0) [0|0] "" GTW
 SG_ IBST_d094_CalDataNotPlaus m3 : 28|2@1+ (1,0) [0|0] "" GTW
 SG_ IBST_d095_canEHwError m3 : 30|2@1+ (1,0) [0|0] "" GTW
 SG_ IBST_d096_canETout m3 : 32|2@1+ (1,0) [0|0] "" GTW
 SG_ IBST_d097_cpuException m3 : 34|2@1+ (1,0) [0|0] "" GTW
 SG_ IBST_d098_ecuBandGap m3 : 36|2@1+ (1,0) [0|0] "" GTW
 SG_ IBST_d099_ecuBmsOnWhileWdTout m3 : 38|2@1+ (1,0) [0|0] "" GTW
 SG_ IBST_d100_ecuErrpinCntTstFls m3 : 40|2@1+ (1,0) [0|0] "" GTW
 SG_ IBST_d101_ecuHetException m3 : 42|2@1+ (1,0) [0|0] "" GTW
 SG_ IBST_d102_ecuHetTuAddErr m3 : 44|2@1+ (1,0) [0|0] "" GTW
 SG_ IBST_d103_ecuHetTuBusErr m3 : 46|2@1+ (1,0) [0|0] "" GTW
 SG_ IBST_d104_ecuHetTuBusyErr m3 : 48|2@1+ (1,0) [0|0] "" GTW
 SG_ IBST_d105_ecuHetTuException m3 : 50|2@1+ (1,0) [0|0] "" GTW
 SG_ IBST_d106_ecuTaskMissing m3 : 52|2@1+ (1,0) [0|0] "" GTW
 SG_ IBST_d107_hetRefError m3 : 54|2@1+ (1,0) [0|0] "" GTW
 SG_ IBST_d108_micInitSpiTstFld m3 : 56|2@1+ (1,0) [0|0] "" GTW
 SG_ IBST_d109_micInitSpiTransfErr m3 : 58|2@1+ (1,0) [0|0] "" GTW
 SG_ IBST_d110_micIntMonGenBitMon m3 : 60|2@1+ (1,0) [0|0] "" GTW
 SG_ IBST_d111_micIntVoltMonFld m3 : 62|2@1+ (1,0) [0|0] "" GTW
 SG_ IBST_d112_motPosTrvlReadEmpty m4 : 8|2@1+ (1,0) [0|0] "" GTW
 SG_ IBST_d113_motAngBoundReadEmpt m4 : 10|2@1+ (1,0) [0|0] "" GTW
 SG_ IBST_d114_motShaftShiftDetect m4 : 12|2@1+ (1,0) [0|0] "" GTW
 SG_ IBST_d115_osErrHook m4 : 14|2@1+ (1,0) [0|0] "" GTW
 SG_ IBST_d116_pdurEInitFail m4 : 16|2@1+ (1,0) [0|0] "" GTW
 SG_ IBST_d117_pdurEPduInstLost m4 : 18|2@1+ (1,0) [0|0] "" GTW
 SG_ IBST_d118_pts1OffsEeReadEmpty m4 : 20|2@1+ (1,0) [0|0] "" GTW
 SG_ IBST_d119_pts2OffsEeReadEmpty m4 : 22|2@1+ (1,0) [0|0] "" GTW
 SG_ IBST_d120_rpsOffsXEeReadFail m4 : 24|2@1+ (1,0) [0|0] "" GTW
 SG_ IBST_d121_rpsOffsYEeReadFail m4 : 26|2@1+ (1,0) [0|0] "" GTW
 SG_ IBST_d122_rpsSynchEeReadFail m4 : 28|2@1+ (1,0) [0|0] "" GTW
 SG_ IBST_d123_rpsAnglRecalcErr m4 : 30|2@1+ (1,0) [0|0] "" GTW
 SG_ IBST_d124_motTrvlRelWriteFail m4 : 32|2@1+ (1,0) [0|0] "" GTW
 SG_ IBST_d125_motTrvlRelReadEmpty m4 : 34|2@1+ (1,0) [0|0] "" GTW
 SG_ IBST_d126_ptsEeReadEmpty m4 : 36|2@1+ (1,0) [0|0] "" GTW
 SG_ IBST_d127_ecuAdcConversionErr m4 : 38|2@1+ (1,0) [0|0] "" GTW
 SG_ IBST_d128_ecuAdcSelftestErr m4 : 40|2@1+ (1,0) [0|0] "" GTW
 SG_ IBST_d129_ccmFlt m4 : 42|2@1+ (1,0) [0|0] "" GTW
 SG_ IBST_d130_ecuRomCheck m4 : 44|2@1+ (1,0) [0|0] "" GTW
 SG_ IBST_d131_esmNmiFlt m4 : 46|2@1+ (1,0) [0|0] "" GTW
 SG_ IBST_d132_esmSafetyFlt m4 : 48|2@1+ (1,0) [0|0] "" GTW
 SG_ IBST_d133_motPosTrvlReadFail m4 : 50|2@1+ (1,0) [0|0] "" GTW
 SG_ IBST_d134_motPosTrvlWriteFail m4 : 52|2@1+ (1,0) [0|0] "" GTW
 SG_ IBST_d135_motAnglBndReadErr m4 : 54|2@1+ (1,0) [0|0] "" GTW
 SG_ IBST_d136_motAnglBndWriteErr m4 : 56|2@1+ (1,0) [0|0] "" GTW
 SG_ IBST_d137_motAnglGradTooLarge m4 : 58|2@1+ (1,0) [0|0] "" GTW
 SG_ IBST_d138_pdmCustomerIdMis m4 : 60|2@1+ (1,0) [0|0] "" GTW
 SG_ IBST_d139_pdmDtFormatMis m4 : 62|2@1+ (1,0) [0|0] "" GTW
 SG_ IBST_d140_pdmOutOfMemory m5 : 8|2@1+ (1,0) [0|0] "" GTW
 SG_ IBST_d141_pdmFieldSizeMis m5 : 10|2@1+ (1,0) [0|0] "" GTW
 SG_ IBST_d142_pdmHwAcsErr m5 : 12|2@1+ (1,0) [0|0] "" GTW
 SG_ IBST_d143_pdmInternalHWErr m5 : 14|2@1+ (1,0) [0|0] "" GTW
 SG_ IBST_d144_ptsCalHysWritFail m5 : 16|2@1+ (1,0) [0|0] "" GTW
 SG_ IBST_d145_ptsCalValuesChkFail m5 : 18|2@1+ (1,0) [0|0] "" GTW
 SG_ IBST_d146_pts1CalEeReadFail m5 : 20|2@1+ (1,0) [0|0] "" GTW
 SG_ IBST_d147_pts1CalEeWriteFail m5 : 22|2@1+ (1,0) [0|0] "" GTW
 SG_ IBST_d148_rpsFailCompErr m5 : 24|2@1+ (1,0) [0|0] "" GTW
 SG_ IBST_d149_pts1OffsEeWriteFail m5 : 26|2@1+ (1,0) [0|0] "" GTW
 SG_ IBST_d150_pts2CalEeReadFail m5 : 28|2@1+ (1,0) [0|0] "" GTW
 SG_ IBST_d151_pts2CalEeWriteFail m5 : 30|2@1+ (1,0) [0|0] "" GTW
 SG_ IBST_d152_pts2OffsEeReadFail m5 : 32|2@1+ (1,0) [0|0] "" GTW
 SG_ IBST_d153_pts2OffsEeWriteFail m5 : 34|2@1+ (1,0) [0|0] "" GTW
 SG_ IBST_d154_rpsOffsXEeReadEmpty m5 : 36|2@1+ (1,0) [0|0] "" GTW
 SG_ IBST_d155_rpsOffsXEeWriteFail m5 : 38|2@1+ (1,0) [0|0] "" GTW
 SG_ IBST_d156_rpsOffsYEeReadEmpty m5 : 40|2@1+ (1,0) [0|0] "" GTW
 SG_ IBST_d157_rpsOffsYEeWriteFail m5 : 42|2@1+ (1,0) [0|0] "" GTW
 SG_ IBST_d158_rpsSynchEeReadEmpty m5 : 44|2@1+ (1,0) [0|0] "" GTW
 SG_ IBST_d159_rpsSynchEeWriteFail m5 : 46|2@1+ (1,0) [0|0] "" GTW
 SG_ IBST_d160_assertionFail m5 : 48|2@1+ (1,0) [0|0] "" GTW
 SG_ IBST_d161_comsclBrkPrsPduLen m5 : 50|2@1+ (1,0) [0|0] "" GTW
 SG_ IBST_d162_comsclBrkPrsPduTout m5 : 52|2@1+ (1,0) [0|0] "" GTW
 SG_ IBST_d163_comsclEspIb1CntErr m5 : 54|2@1+ (1,0) [0|0] "" GTW
 SG_ IBST_d164_comsclEspIb1CsErr m5 : 56|2@1+ (1,0) [0|0] "" GTW
 SG_ IBST_d165_comsclEspIb1DlcErr m5 : 58|2@1+ (1,0) [0|0] "" GTW
 SG_ IBST_d166_comsclEspIb1Tout m5 : 60|2@1+ (1,0) [0|0] "" GTW
 SG_ IBST_d167_comsclEspIb2CntErr m5 : 62|2@1+ (1,0) [0|0] "" GTW
 SG_ IBST_d168_comsclEspIb2CsErr m6 : 8|2@1+ (1,0) [0|0] "" GTW
 SG_ IBST_d169_comsclEspIb2DlcErr m6 : 10|2@1+ (1,0) [0|0] "" GTW
 SG_ IBST_d170_comsclEspIb2Tout m6 : 12|2@1+ (1,0) [0|0] "" GTW
 SG_ IBST_d171_comsclEspIb3CntErr m6 : 14|2@1+ (1,0) [0|0] "" GTW
 SG_ IBST_d172_comsclEspIb3CsErr m6 : 16|2@1+ (1,0) [0|0] "" GTW
 SG_ IBST_d173_comsclEspIb3DlcErr m6 : 18|2@1+ (1,0) [0|0] "" GTW
 SG_ IBST_d174_comsclEspIb3Tout m6 : 20|2@1+ (1,0) [0|0] "" GTW
 SG_ IBST_d175_comsclGtwEsp1CntErr m6 : 22|2@1+ (1,0) [0|0] "" GTW
 SG_ IBST_d176_comsclGtwEsp1CsErr m6 : 24|2@1+ (1,0) [0|0] "" GTW
 SG_ IBST_d177_comsclGtwEsp1Corrpt m6 : 26|2@1+ (1,0) [0|0] "" GTW
 SG_ IBST_d178_comsclGtwEsp1Tout m6 : 28|2@1+ (1,0) [0|0] "" GTW
 SG_ IBST_d179_dcomSmrtActuNotInit m6 : 30|2@1+ (1,0) [0|0] "" GTW
 SG_ IBST_d180_rpsLengthAbsolHigh m6 : 32|2@1+ (1,0) [0|0] "" GTW
 SG_ IBST_d181_rpsLengthAbsolLow m6 : 34|2@1+ (1,0) [0|0] "" GTW
 SG_ IBST_d182_shutDownEeReadFail m6 : 36|2@1+ (1,0) [0|0] "" GTW
 SG_ IBST_d183_shutDownEeWriteFail m6 : 38|2@1+ (1,0) [0|0] "" GTW
 SG_ IBST_d184_maxTrvlAdjstReadErr m6 : 40|2@1+ (1,0) [0|0] "" GTW
 SG_ IBST_d185_psOffsMcEeReadFail m6 : 42|2@1+ (1,0) [0|0] "" GTW
 SG_ IBST_d186_psOffsMcEeWriteFail m6 : 44|2@1+ (1,0) [0|0] "" GTW
 SG_ IBST_d187_ltmSelfProtDeact m6 : 46|2@1+ (1,0) [0|0] "" GTW
 SG_ IBST_d188_pts1OffsEeReadFail m6 : 48|2@1+ (1,0) [0|0] "" GTW
 SG_ IBST_d189_diffStrokeRange m6 : 50|2@1+ (1,0) [0|0] "" GTW
 SG_ IBST_d190_notProgVin m6 : 52|2@1+ (1,0) [0|0] "" GTW
 SG_ IBST_d191_plausVin m6 : 54|2@1+ (1,0) [0|0] "" GTW
 SG_ IBST_d192_dlCorCSumVin m6 : 56|2@1+ (1,0) [0|0] "" GTW
 SG_ IBST_d193_ToutVin m6 : 58|2@1+ (1,0) [0|0] "" GTW
 SG_ IBST_d194_ecuEnableB6Fail m6 : 60|2@1+ (1,0) [0|0] "" GTW
 SG_ IBST_d195_ecuIbEnContErr m6 : 62|2@1+ (1,0) [0|0] "" GTW
 SG_ IBST_d196_sclEspIb1pEstMax m7 : 8|2@1+ (1,0) [0|0] "" GTW
 SG_ IBST_d197_sclEspIb1VehSpd m7 : 10|2@1+ (1,0) [0|0] "" GTW
 SG_ IBST_d198_sclEspIb2pLimExt m7 : 12|2@1+ (1,0) [0|0] "" GTW
 SG_ IBST_d199_sclEspIb2qTarExt m7 : 14|2@1+ (1,0) [0|0] "" GTW
 SG_ IBST_d200_sclEspIb3pFBlend m7 : 16|2@1+ (1,0) [0|0] "" GTW
 SG_ IBST_d201_sclEspIb3pMc1 m7 : 18|2@1+ (1,0) [0|0] "" GTW
 SG_ IBST_d202_sclEspIb3pTarDriver m7 : 20|2@1+ (1,0) [0|0] "" GTW
 SG_ IBST_d203_netBusOffNet0 m7 : 22|2@1+ (1,0) [0|0] "" GTW
 SG_ IBST_d204_netErrPassivNet0 m7 : 24|2@1+ (1,0) [0|0] "" GTW
 SG_ IBST_d205_netBusOffNet1 m7 : 26|2@1+ (1,0) [0|0] "" GTW
 SG_ IBST_d206_netErrPassivNet1 m7 : 28|2@1+ (1,0) [0|0] "" GTW
 SG_ IBST_d207_maxStrokeReached m7 : 30|2@1+ (1,0) [0|0] "" GTW
 SG_ IBST_d208_sysSwClockMismatch m7 : 32|2@1+ (1,0) [0|0] "" GTW
 SG_ IBST_d209_comsclGtwOdoCorrpt m7 : 34|2@1+ (1,0) [0|0] "" GTW
 SG_ IBST_d210_comsclGtwStatCorrpt m7 : 36|2@1+ (1,0) [0|0] "" GTW
 SG_ IBST_d211_comsclEpbStatCorrpt m7 : 38|2@1+ (1,0) [0|0] "" GTW
 SG_ IBST_d212_comsclGtwOdoTout m7 : 40|2@1+ (1,0) [0|0] "" GTW
 SG_ IBST_d213_comsclGtwStatTout m7 : 42|2@1+ (1,0) [0|0] "" GTW
 SG_ IBST_d214_comsclEpbStatTout m7 : 44|2@1+ (1,0) [0|0] "" GTW
 SG_ IBST_d215_comSclEpbStatCsErr m7 : 46|2@1+ (1,0) [0|0] "" GTW
 SG_ IBST_d216_comSclEpbStatCntFlt m7 : 48|2@1+ (1,0) [0|0] "" GTW
 SG_ IBST_d217_comSclDiTrq1Tout m7 : 50|2@1+ (1,0) [0|0] "" GTW
 SG_ IBST_d218_comSclDiTrq1Corrpt m7 : 52|2@1+ (1,0) [0|0] "" GTW
 SG_ IBST_d219_comSclDiTrq1CsErr m7 : 54|2@1+ (1,0) [0|0] "" GTW
 SG_ IBST_d220_comSclDiTrq1CntFlt m7 : 56|2@1+ (1,0) [0|0] "" GTW

BO_ 541 IBST_ebrStatus: 5 IBST
 SG_ IBST_ebrStatusChecksum : 0|8@1+ (1,0) [0|255] "" GTW
 SG_ IBST_ebrStatusCounter : 8|4@1+ (1,0) [0|15] "" GTW
 SG_ IBST_ebrMode : 12|3@1+ (1,0) [0|7] "" GTW
 SG_ IBST_ebrSystemMode : 15|3@1+ (1,0) [0|7] "" GTW
 SG_ IBST_brakeTorqueTarget : 18|13@1+ (2,0) [0|16382] "Nm" GTW
 SG_ IBST_ebrSource : 32|1@1+ (1,0) [0|2] "" GTW
 SG_ IBST_ebrState : 33|2@1+ (1,0) [0|3] "" GTW

BO_ 813 IBST_info: 8 IBST
 SG_ IBST_infoIndex M : 0|8@1+ (1,0) [0|255] "" GTW,GTWU
 SG_ IBST_buildType m10 : 8|8@1+ (1,0) [0|255] "" GTW
 SG_ IBST_componentId m10 : 48|16@1+ (1,0) [0|65535] "" GTW
 SG_ IBST_pcbaId m11 : 16|8@1+ (1,0) [0|0] "" GTW,GTWU
 SG_ IBST_assemblyId m11 : 24|8@1+ (1,0) [0|0] "" GTW,GTWU
 SG_ IBST_usageId m11 : 32|16@1+ (1,0) [0|0] "" GTW,GTWU
 SG_ IBST_applicationCrc m13 : 32|32@1+ (1,0) [0|0] "" GTW,GTWU
 SG_ IBST_udsProtocolVersion m20 : 8|8@1+ (1,0) [0|0] "" GTW,GTWU
 SG_ IBST_bootloaderCrc m20 : 32|32@1+ (1,0) [0|0] "" GTW
 SG_ IBST_variantCrc m22 : 32|32@1+ (1,0) [0|0] "" GTW,GTWU

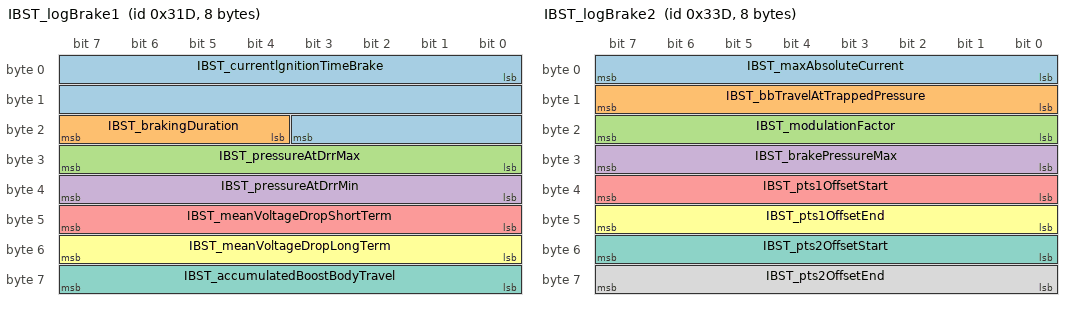
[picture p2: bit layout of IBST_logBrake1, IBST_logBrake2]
BO_ 797 IBST_logBrake1: 8 IBST
 SG_ IBST_currentlgnitionTimeBrake : 0|20@1+ (0.1,0) [0|86400] "sec" Vector__XXX
 SG_ IBST_brakingDuration : 20|4@1+ (1,0) [0|15] "" Vector__XXX
 SG_ IBST_pressureAtDrrMax : 24|8@1+ (1,0) [0|250] "bar" Vector__XXX
 SG_ IBST_pressureAtDrrMin : 32|8@1+ (1,0) [0|250] "bar" Vector__XXX
 SG_ IBST_meanVoltageDropShortTerm : 40|8@1+ (0.01,0) [0|1.5] "V" Vector__XXX
 SG_ IBST_meanVoltageDropLongTerm : 48|8@1+ (0.01,0) [0|1.5] "V" Vector__XXX
 SG_ IBST_accumulatedBoostBodyTravel : 56|8@1+ (10,0) [0|2550] "mm" Vector__XXX

BO_ 829 IBST_logBrake2: 8 IBST
 SG_ IBST_maxAbsoluteCurrent : 0|8@1+ (1,0) [0|255] "A" Vector__XXX
 SG_ IBST_bbTravelAtTrappedPressure : 8|8@1+ (0.1,0) [0|20] "mm" Vector__XXX
 SG_ IBST_modulationFactor : 16|8@1+ (0.1,0) [0|25.5] "1" Vector__XXX
 SG_ IBST_brakePressureMax : 24|8@1+ (1,0) [0|250] "bar" Vector__XXX
 SG_ IBST_pts1OffsetStart : 32|8@1+ (0.01,-0.5) [-0.5|1] "mm" Vector__XXX
 SG_ IBST_pts1OffsetEnd : 40|8@1+ (0.01,-0.5) [-0.5|1] "mm" Vector__XXX
 SG_ IBST_pts2OffsetStart : 48|8@1+ (0.01,-0.5) [-0.5|1] "mm" Vector__XXX
 SG_ IBST_pts2OffsetEnd : 56|8@1+ (0.01,-0.5) [-0.5|1] "mm" Vector__XXX

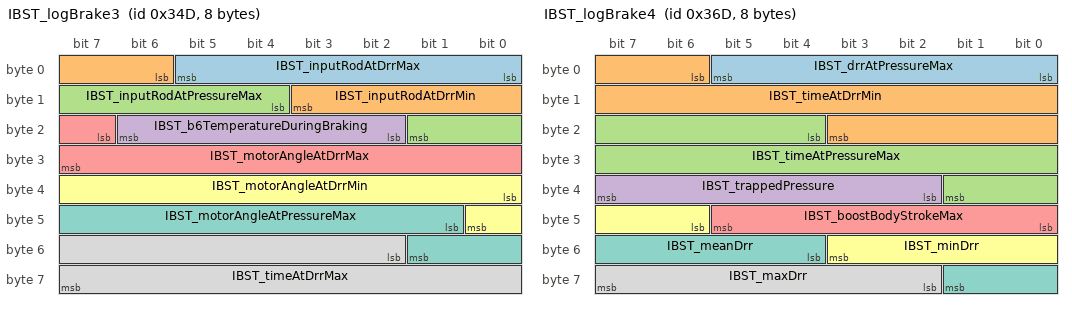
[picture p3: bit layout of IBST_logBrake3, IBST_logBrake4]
BO_ 845 IBST_logBrake3: 8 IBST
 SG_ IBST_inputRodAtDrrMax : 0|6@1+ (1,0) [0|50] "mm" Vector__XXX
 SG_ IBST_inputRodAtDrrMin : 6|6@1+ (1,0) [0|50] "mm" Vector__XXX
 SG_ IBST_inputRodAtPressureMax : 12|6@1+ (1,0) [0|50] "mm" Vector__XXX
 SG_ IBST_b6TemperatureDuringBraking : 18|5@1+ (10,-40) [-40|150] "C" Vector__XXX
 SG_ IBST_motorAngleAtDrrMax : 23|9@1+ (0.25,0) [0|127] "rad" Vector__XXX
 SG_ IBST_motorAngleAtDrrMin : 32|9@1+ (0.25,0) [0|127] "rad" Vector__XXX
 SG_ IBST_motorAngleAtPressureMax : 41|9@1+ (0.25,0) [0|127] "rad" Vector__XXX
 SG_ IBST_timeAtDrrMax : 50|14@1+ (0.2,0) [0|1800] "sec" Vector__XXX

BO_ 877 IBST_logBrake4: 8 IBST
 SG_ IBST_drrAtPressureMax : 0|6@1+ (0.1,-3) [-3|3] "mm" Vector__XXX
 SG_ IBST_timeAtDrrMin : 6|14@1+ (0.2,0) [0|1800] "sec" Vector__XXX
 SG_ IBST_timeAtPressureMax : 20|14@1+ (0.2,0) [0|1800] "sec" Vector__XXX
 SG_ IBST_trappedPressure : 34|6@1+ (0.5,0) [0|20] "bar" Vector__XXX
 SG_ IBST_boostBodyStrokeMax : 40|6@1+ (1,0) [0|50] "mm" Vector__XXX
 SG_ IBST_minDrr : 46|6@1+ (0.1,-3) [-3|3] "mm" Vector__XXX
 SG_ IBST_meanDrr : 52|6@1+ (0.1,-3) [-3|3] "mm" Vector__XXX
 SG_ IBST_maxDrr : 58|6@1+ (0.1,-3) [-3|3] "mm" Vector__XXX

BO_ 893 IBST_logBrake5: 8 IBST
 SG_ IBST_classifiedPhaseCurrent1 : 0|16@1+ (1,0) [0|65535] "" Vector__XXX
 SG_ IBST_classifiedPhaseCurrent2 : 16|13@1+ (1,0) [0|8191] "" Vector__XXX
 SG_ IBST_classifiedPhaseCurrent3 : 29|13@1+ (1,0) [0|8191] "" Vector__XXX
 SG_ IBST_minVoltage : 42|6@1+ (0.5,0) [0|20] "V" Vector__XXX
 SG_ IBST_maxVoltage : 48|6@1+ (0.5,0) [0|20] "V" Vector__XXX
 SG_ IBST_motorSpeedZeroCrossings : 54|10@1+ (1,0) [0|1000] "" Vector__XXX

(* BO_ 909 IBST_logBrake6: 8 IBST
 SG_ IBST_classifiedPhaseCurrent4 : 0|9@1+ (1,0) [0|511] "" Vector__XXX
 SG_ IBST_classifiedPhaseCurrent5 : 9|7@1+ (1,0) [0|127] "" Vector__XXX
 SG_ IBST_classifiedPhaseCurrent6 : 16|5@1+ (1,0) [0|31] "" Vector__XXX
 SG_ IBST_classifiedPhaseCurrent7 : 21|3@1+ (1,0) [0|7] "" Vector__XXX
 SG_ IBST_maxPressureGradientEndPress : 24|5@1+ (10,0) [0|200] "bar" Vector__XXX
 SG_ IBST_maxPressureGradient : 29|7@1+ (20,0) [0|2000] "bar/s" Vector__XXX
 SG_ IBST_meanVoltage : 36|6@1+ (0.5,0) [0|20] "V" Vector__XXX
 SG_ IBST_maxMotorSpeed : 42|5@1+ (20,0) [0|600] "rad/s" Vector__XXX
 SG_ IBST_maxInputRodTravel : 47|6@1+ (1,0) [0|50] "mm" Vector__XXX
 SG_ IBST_boostBodyTravelAtPMax : 53|9@1+ (0.1,0) [0|50] "mm" Vector__XXX *)

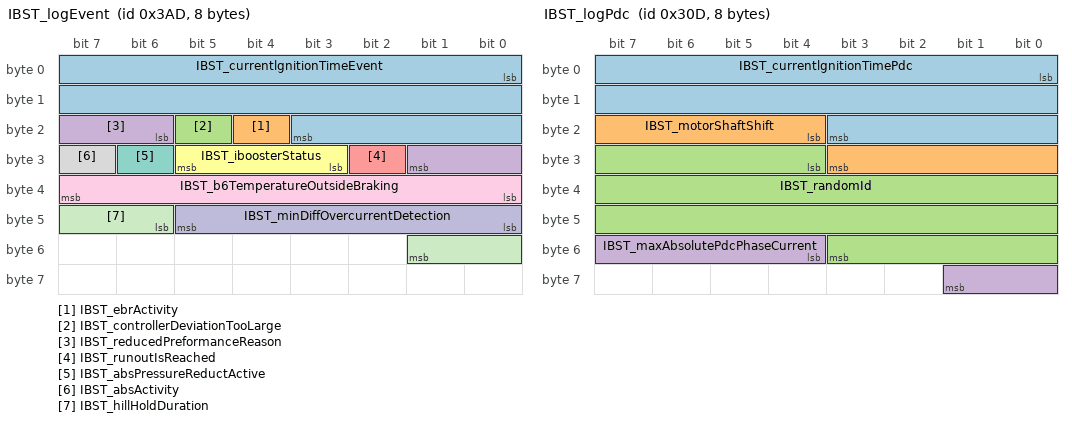
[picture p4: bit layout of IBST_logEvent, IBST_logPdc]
BO_ 941 IBST_logEvent: 8 IBST
 SG_ IBST_currentlgnitionTimeEvent : 0|20@1+ (0.1,0) [0|86400] "sec" Vector__XXX
 SG_ IBST_ebrActivity : 20|1@1+ (1,0) [0|1] "" Vector__XXX
 SG_ IBST_controllerDeviationTooLarge : 21|1@1+ (1,0) [0|1] "" Vector__XXX
 SG_ IBST_reducedPreformanceReason : 22|4@1+ (1,0) [0|15] "" Vector__XXX
 SG_ IBST_runoutIsReached : 26|1@1+ (1,0) [0|1] "" Vector__XXX
 SG_ IBST_iboosterStatus : 27|3@1+ (1,0) [0|7] "" Vector__XXX
 SG_ IBST_absPressureReductActive : 30|1@1+ (1,0) [0|1] "" Vector__XXX
 SG_ IBST_absActivity : 31|1@1+ (1,0) [0|1] "" Vector__XXX
 SG_ IBST_b6TemperatureOutsideBraking : 32|8@1+ (10,-40) [-40|150] "C" Vector__XXX
 SG_ IBST_minDiffOvercurrentDetection : 40|6@1+ (0.00390625,0) [0|0.203125] "V" Vector__XXX
 SG_ IBST_hillHoldDuration : 46|4@1+ (0.2,0) [0|2] "sec" Vector__XXX

BO_ 781 IBST_logPdc: 8 IBST
 SG_ IBST_currentlgnitionTimePdc : 0|20@1+ (0.1,0) [0|86400] "sec" Vector__XXX
 SG_ IBST_motorShaftShift : 20|8@1+ (10,-60) [-60|2490] "deg" Vector__XXX
 SG_ IBST_randomId : 28|24@1+ (1,0) [0|16777215] "" Vector__XXX
 SG_ IBST_maxAbsolutePdcPhaseCurrent : 52|6@1+ (1,0) [0|50] "A" Vector__XXX

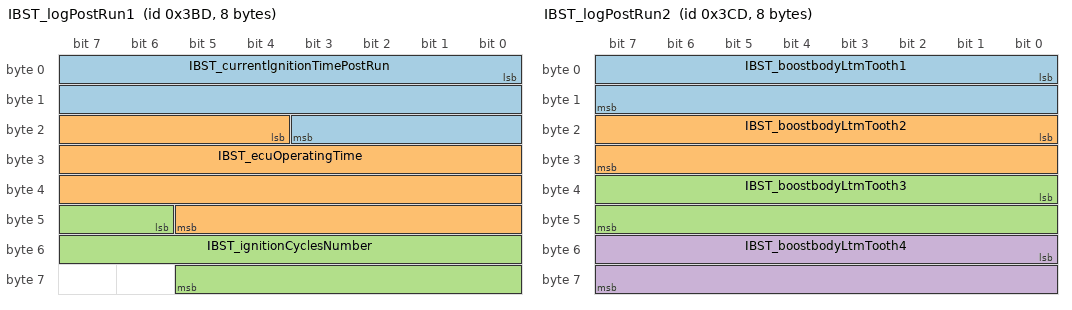
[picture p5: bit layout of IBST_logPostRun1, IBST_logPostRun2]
BO_ 957 IBST_logPostRun1: 8 IBST
 SG_ IBST_currentlgnitionTimePostRun : 0|20@1+ (0.1,0) [0|86400] "sec" Vector__XXX
 SG_ IBST_ecuOperatingTime : 20|26@1+ (1,0) [0|67108863] "sec" Vector__XXX
 SG_ IBST_ignitionCyclesNumber : 46|16@1+ (1,0) [0|65535] "" Vector__XXX

BO_ 973 IBST_logPostRun2: 8 IBST
 SG_ IBST_boostbodyLtmTooth1 : 0|16@1+ (0.0039,0) [0|255] "1" Vector__XXX
 SG_ IBST_boostbodyLtmTooth2 : 16|16@1+ (0.0039,0) [0|255] "1" Vector__XXX
 SG_ IBST_boostbodyLtmTooth3 : 32|16@1+ (0.0039,0) [0|255] "1" Vector__XXX
 SG_ IBST_boostbodyLtmTooth4 : 48|16@1+ (0.0039,0) [0|255] "1" Vector__XXX

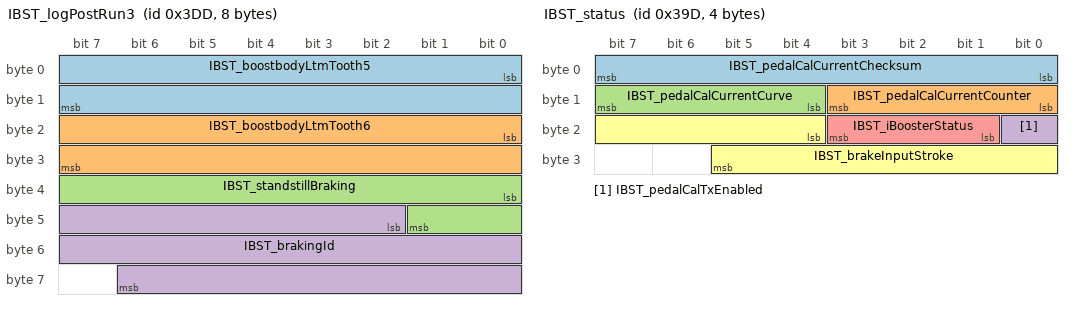
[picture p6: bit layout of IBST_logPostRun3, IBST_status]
BO_ 989 IBST_logPostRun3: 8 IBST
 SG_ IBST_boostbodyLtmTooth5 : 0|16@1+ (0.0039,0) [0|255] "1" Vector__XXX
 SG_ IBST_boostbodyLtmTooth6 : 16|16@1+ (0.0039,0) [0|255] "1" Vector__XXX
 SG_ IBST_standstillBraking : 32|10@1+ (1,0) [0|1000] "" Vector__XXX
 SG_ IBST_brakingId : 42|21@1+ (1,0) [0|2000000] "" Vector__XXX

BO_ 925 IBST_status: 4 IBST
 SG_ IBST_pedalCalCurrentChecksum : 0|8@1+ (1,0) [0|255] "" GTW
 SG_ IBST_pedalCalCurrentCounter : 8|4@1+ (1,0) [0|15] "" GTW
 SG_ IBST_pedalCalCurrentCurve : 12|4@1+ (1,0) [0|15] "1" GTW
 SG_ IBST_pedalCalTxEnabled : 16|1@1+ (1,0) [0|1] "1" GTW
 SG_ IBST_iBoosterStatus : 17|3@1+ (1,0) [0|0] "" GTW
 SG_ IBST_brakeInputStroke : 20|10@1+ (0.05,-0.5) [-0.5|50.55] "mm" GTW

BO_ 1629 IBST_udsResponse: 8 IBST
 SG_ IBST_udsResponseData : 7|64@0+ (1,0) [0|0] "" GTW,GTWU

BO_ 1613 UDS_ibstRequest: 8 GTW
 SG_ UDS_ibstRequestData : 7|64@0+ (1,0) [0|0] "" IBST

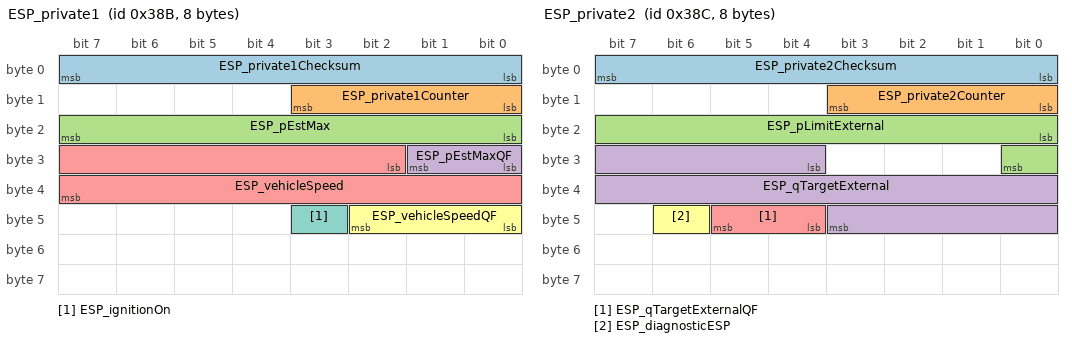
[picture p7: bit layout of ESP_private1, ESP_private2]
BO_ 907 ESP_private1: 8 ESP
 SG_ ESP_private1Checksum : 0|8@1+ (1,0) [0|255] "" IBST,EPAS
 SG_ ESP_private1Counter : 8|4@1+ (1,0) [0|15] "" IBST,EPAS
 SG_ ESP_pEstMax : 16|8@1+ (1,0) [0|250] "bar" IBST
 SG_ ESP_pEstMaxQF : 24|2@1+ (1,0) [0|2] "" IBST
 SG_ ESP_vehicleSpeed : 26|14@1+ (0.05625,0) [0|921.54375] "km/h" IBST,EPAS
 SG_ ESP_vehicleSpeedQF : 40|3@1+ (1,0) [0|6] "" IBST,EPAS
 SG_ ESP_ignitionOn : 43|1@1+ (1,0) [0|1] "" IBST

BO_ 908 ESP_private2: 8 ESP
 SG_ ESP_private2Checksum : 0|8@1+ (1,0) [0|255] "" IBST
 SG_ ESP_private2Counter : 8|4@1+ (1,0) [0|15] "" IBST
 SG_ ESP_pLimitExternal : 16|9@1+ (0.5,0) [0|250] "bar" IBST
 SG_ ESP_qTargetExternal : 28|16@1+ (0.0078125,-252) [-252|252] "ml/s" IBST
 SG_ ESP_qTargetExternalQF : 44|2@1+ (1,0) [0|3] "1" IBST
 SG_ ESP_diagnosticESP : 46|1@1+ (1,0) [0|1] "" IBST

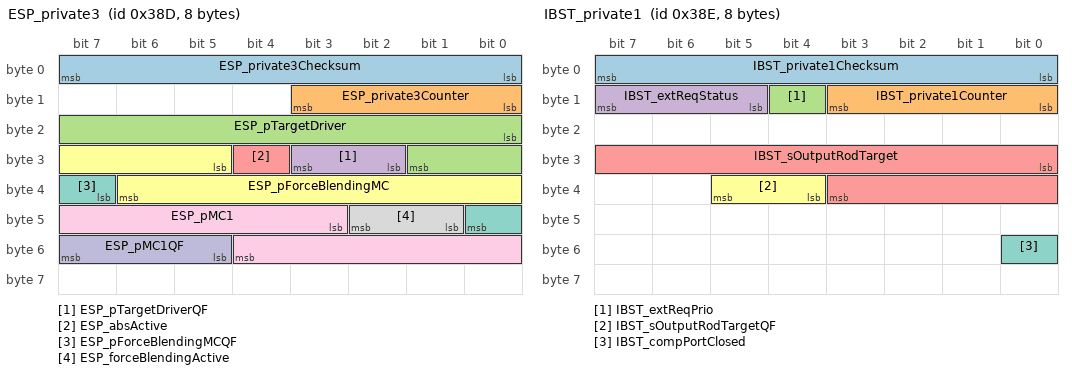
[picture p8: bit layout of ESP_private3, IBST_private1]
BO_ 909 ESP_private3: 8 ESP
 SG_ ESP_private3Checksum : 0|8@1+ (1,0) [0|255] "" IBST
 SG_ ESP_private3Counter : 8|4@1+ (1,0) [0|15] "" IBST
 SG_ ESP_pTargetDriver : 16|10@1+ (0.25,0) [0|250] "bar" IBST
 SG_ ESP_pTargetDriverQF : 26|2@1+ (1,0) [0|3] "" IBST
 SG_ ESP_absActive : 28|1@1+ (1,0) [0|1] "1" IBST
 SG_ ESP_pForceBlendingMC : 29|10@1+ (0.25,0) [0|250] "" IBST
 SG_ ESP_pForceBlendingMCQF : 39|2@1+ (1,0) [0|3] "" IBST
 SG_ ESP_forceBlendingActive : 41|2@1+ (1,0) [0|2] "" IBST
 SG_ ESP_pMC1 : 43|10@1+ (0.3,-30) [-30|276.6] "bar" IBST
 SG_ ESP_pMC1QF : 53|3@1+ (1,0) [0|4] "1" IBST

BO_ 910 IBST_private1: 8 IBST
 SG_ IBST_private1Checksum : 0|8@1+ (1,0) [0|255] "" ESP
 SG_ IBST_private1Counter : 8|4@1+ (1,0) [0|15] "" ESP
 SG_ IBST_extReqPrio : 12|1@1+ (1,0) [0|1] "" ESP
 SG_ IBST_extReqStatus : 13|3@1+ (1,0) [0|4] "" ESP
 SG_ IBST_sOutputRodTarget : 24|12@1+ (0.015625,-5) [-5|47] "mm" ESP
 SG_ IBST_sOutputRodTargetQF : 36|2@1+ (1,0) [0|3] "" ESP
 SG_ IBST_compPortClosed : 48|1@1+ (1,0) [0|1] "" ESP

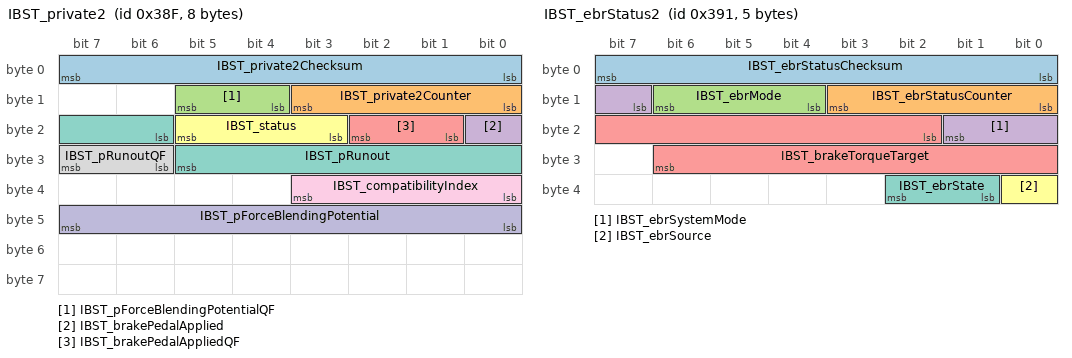
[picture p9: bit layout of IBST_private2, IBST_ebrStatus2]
BO_ 911 IBST_private2: 8 IBST
 SG_ IBST_private2Checksum : 0|8@1+ (1,0) [0|255] "" ESP
 SG_ IBST_private2Counter : 8|4@1+ (1,0) [0|15] "" ESP
 SG_ IBST_pForceBlendingPotentialQF : 12|2@1+ (1,0) [0|2] "" ESP
 SG_ IBST_brakePedalApplied : 16|1@1+ (1,0) [0|1] "1" ESP
 SG_ IBST_brakePedalAppliedQF : 17|2@1+ (1,0) [0|3] "" ESP
 SG_ IBST_status : 19|3@1+ (1,0) [0|7] "1" ESP
 SG_ IBST_pRunout : 22|8@1+ (1,0) [0|250] "bar" ESP
 SG_ IBST_pRunoutQF : 30|2@1+ (1,0) [0|3] "" ESP
 SG_ IBST_compatibilityIndex : 32|4@1+ (1,0) [0|15] "" ESP
 SG_ IBST_pForceBlendingPotential : 40|8@1+ (0.5,0) [0|125] "bar" ESP

BO_ 913 IBST_ebrStatus2: 5 IBST
 SG_ IBST_ebrStatusChecksum : 0|8@1+ (1,0) [0|255] "" Vector__XXX
 SG_ IBST_ebrStatusCounter : 8|4@1+ (1,0) [0|15] "" Vector__XXX
 SG_ IBST_ebrMode : 12|3@1+ (1,0) [0|7] "" Vector__XXX
 SG_ IBST_ebrSystemMode : 15|3@1+ (1,0) [0|7] "" Vector__XXX
 SG_ IBST_brakeTorqueTarget : 18|13@1+ (2,0) [0|16382] "Nm" Vector__XXX
 SG_ IBST_ebrSource : 32|1@1+ (1,0) [0|2] "" Vector__XXX
 SG_ IBST_ebrState : 33|2@1+ (1,0) [0|3] "" Vector__XXX

CM_ SG_ 264 DI_torqueDriver "Driver requested torque command. SNA is 0xF000";
CM_ SG_ 264 DI_torque1Counter "Message counter for DI_torque1 message: increments in each message.";
CM_ SG_ 264 DI_torqueMotor "Applied motor torque command. SNA is 0xF000";
CM_ SG_ 264 DI_motorRPM "Drive Inverter measured motor shaft speed. SNA is 0x8000";
CM_ SG_ 264 DI_pedalPos "Drive Inverter measured pedal position.";
CM_ SG_ 264 DI_torque1Checksum "Message checksum for DI_torque1 message: sum of all bytes in message + 0x07";
CM_ SG_ 516 EPB_state "EPB state machine mode - EPB_STATE_PARK or EPB_STATE_HANDBRAKE means parking brake is applied";
CM_ SG_ 516 EPB_stateRequest "EPB requested state machine mode";
CM_ SG_ 516 EPB_brakeLight "Illuminates brake light when dynamic brake is engaged";
CM_ SG_ 516 EPB_substateL "EPB substate left motor";
CM_ SG_ 516 EPB_substateR "EPB substate right motor";
CM_ SG_ 516 EPB_statePending "EPB pending state machine mode";
CM_ SG_ 516 EPB_telltale "Illuminates telltale on the instrument cluster";
CM_ SG_ 520 GTW_ESP1Counter "Message counter for esp message, increments in each message.";
CM_ SG_ 520 GTW_hillStartAssistDisabled "Signal to disable the hill start assist feature. Was implemented as an enable signal prior to BL6.";
CM_ SG_ 520 GTW_brakeDiscWipeRequest "Request to trigger the brake disc wipe function in the ESP.";
CM_ SG_ 520 GTW_brakeFluidLow "Low brake fluid warning. Bosch qualification time on this is 20 seconds.";
CM_ SG_ 520 GTW_pedalCalRxEnable "Indication whether switching of pedal calibration target curves is allowed.";
CM_ SG_ 520 GTW_ambientTemperature "Ambient temperature (unfiltered value)";
CM_ SG_ 520 GTW_pedalCalTargetCurve "Indicates the desired iBooster pedal feel curve.";
CM_ SG_ 520 GTW_espModeSwitch "Periodic signal that is implemented like a momentary switch to indicate the user selected ESP mode.";
CM_ SG_ 520 GTW_ESP1Checksum "Message checksum for GTW_ESP1 message: sum of all bytes in message + originating CAN ID (0x2 + 0x08 = 0x0A)";
CM_ SG_ 776 GTW_easManualLevelRequest "UI (MCU) customer level request; Jack mode is used to disable leveling.";
CM_ SG_ 776 HVBatteryLow "Indication to Conti that we don't want them to use energy by leveling in postrun.";
CM_ SG_ 776 GTW_espPlatCalMismatch "Indication to the ESP that the calibration version does not match.";
CM_ SG_ 776 GTW_ibstConnectivityDisable "Signal to disable the iBooster from transmitting the connectivity messages for logging.";
CM_ SG_ 776 AMB_TEMP "Ambience temperature";
CM_ SG_ 776 GTW_ODO "Odometer";
CM_ SG_ 840 GTW_icPowerOff "Indicates that the gateway may soon pull power away from the instrument cluster.  This allows the IC to do a controlled shutdown.";
CM_ SG_ 840 GTW_hvacRailIsOn "GTW reporting HVAC rail is ON when set 1.";
CM_ SG_ 861 IBST_d000_bmsInitTestFail "Bosch DTC value: 0x00001C00";
CM_ SG_ 861 IBST_d001_bmcSingleTransTest "Bosch DTC value: 0x00002100";
CM_ SG_ 861 IBST_d002_tle5012SsccrcFail "Bosch DTC value: 0x00002500";
CM_ SG_ 861 IBST_d003_tle5012Config "Bosch DTC value: 0x00003500";
CM_ SG_ 861 IBST_d004_deadlMonTaskx1Ovr "Bosch DTC value: 0x00004F00";
CM_ SG_ 861 IBST_d005_ecuWdFltCntTstFls "Bosch DTC value: 0x00006200";
CM_ SG_ 861 IBST_d006_ecuWdScheduleTout "Bosch DTC value: 0x00006700";
CM_ SG_ 861 IBST_d007_ecuWdStarttestFls "Bosch DTC value: 0x00006800";
CM_ SG_ 861 IBST_d008_ecuWdStatusContErr "Bosch DTC value: 0x00006A00";
CM_ SG_ 861 IBST_d009_netOvrvolt "Bosch DTC value: 0x00006C00";
CM_ SG_ 861 IBST_d010_micSpiTout "Bosch DTC value: 0x00007200";
CM_ SG_ 861 IBST_d011_micSpiTransferErr "Bosch DTC value: 0x00007D00";
CM_ SG_ 861 IBST_d012_netUndvolt "Bosch DTC value: 0x00008500";
CM_ SG_ 861 IBST_d013_xpassToutErr "Bosch DTC value: 0x00009000";
CM_ SG_ 861 IBST_d014_rpsOffsEeReadEmpty "Bosch DTC value: 0x00009400";
CM_ SG_ 861 IBST_d015_rtpEnaHigh "Bosch DTC value: 0x00009500";
CM_ SG_ 861 IBST_d016_xpassEchoCountErr "Bosch DTC value: 0x00009900";
CM_ SG_ 861 IBST_d017_preDriveChckFail "Bosch DTC value: 0x00009E00";
CM_ SG_ 861 IBST_d018_ucSafetyFlt "Bosch DTC value: 0x0000A500";
CM_ SG_ 861 IBST_d019_unsupportedHw "Bosch DTC value: 0x0000A700";
CM_ SG_ 861 IBST_d020_voltPreRegModeFld "Bosch DTC value: 0x0000AA00";
CM_ SG_ 861 IBST_d021_ubbSupplyLine "Bosch DTC value: 0x0000AB00";
CM_ SG_ 861 IBST_d022_stmAswSysTout "Bosch DTC value: 0x0000B900";
CM_ SG_ 861 IBST_d023_stackOvrUndFlow "Bosch DTC value: 0x0000BB00";
CM_ SG_ 861 IBST_d024_smmOneReqsInit "Bosch DTC value: 0x0000C100";
CM_ SG_ 861 IBST_d025_ptsSupply "Bosch DTC value: 0x0000CC00";
CM_ SG_ 861 IBST_d026_ptsSupplyUndvolt "Bosch DTC value: 0x0000CD00";
CM_ SG_ 861 IBST_d027_tempB6Plaus "Bosch DTC value: 0x0000D600";
CM_ SG_ 861 IBST_d028_ecuWdErrCntContErr "Bosch DTC value: 0x0000DD00";
CM_ SG_ 861 IBST_d029_bmcShortedGateTest "Bosch DTC value: 0x0000E100";
CM_ SG_ 861 IBST_d030_controllerDevTooBig "Bosch DTC value: 0x0000E200";
CM_ SG_ 861 IBST_d031_ibDtrFail "Bosch DTC value: 0x0000E300";
CM_ SG_ 861 IBST_d032_oc6InitTestFail "Bosch DTC value: 0x0000E800";
CM_ SG_ 861 IBST_d033_oc6Monitor "Bosch DTC value: 0x0000E900";
CM_ SG_ 861 IBST_d034_motorOscillationDet "Bosch DTC value: 0x0000EA00";
CM_ SG_ 861 IBST_d035_rpsOffsEeReadFail "Bosch DTC value: 0x00010000";
CM_ SG_ 861 IBST_d036_sysErrHook "Bosch DTC value: 0x00025F00";
CM_ SG_ 861 IBST_d037_calIdlePosNotPlaus "Bosch DTC value: 0x00026100";
CM_ SG_ 861 IBST_d038_boostSupUndrvolt "Bosch DTC value: 0x00026300";
CM_ SG_ 861 IBST_d039_calRoutineAbort "Bosch DTC value: 0x00026800";
CM_ SG_ 861 IBST_d040_bmcGateUndervoltPro "Bosch DTC value: 0x00026900";
CM_ SG_ 861 IBST_d041_hswInitPhseUndrvolt "Bosch DTC value: 0x00026C00";
CM_ SG_ 861 IBST_d042_ltmWarnLevelReached "Bosch DTC value: 0x00026D00";
CM_ SG_ 861 IBST_d043_rpsVctrLengthRelErr "Bosch DTC value: 0x00027200";
CM_ SG_ 861 IBST_d044_b6TempDegradeLevel1 "Bosch DTC value: 0x00028100";
CM_ SG_ 861 IBST_d045_B6TempDegradeLevel2 "Bosch DTC value: 0x00028200";
CM_ SG_ 861 IBST_d046_spiAnglOrRawNotUp "Bosch DTC value: 0x00028400";
CM_ SG_ 861 IBST_d047_dcomIboosterNotInit "Bosch DTC value: 0x00029F00";
CM_ SG_ 861 IBST_d048_unintendMotorReturn "Bosch DTC value: 0x0002A000";
CM_ SG_ 861 IBST_d049_cdmOvrvoltLevel1 "Bosch DTC value: 0x0002A400";
CM_ SG_ 861 IBST_d050_cdmUndrvoltLevel2 "Bosch DTC value: 0x0002A500";
CM_ SG_ 861 IBST_d051_cdmUndrvoltLevel1 "Bosch DTC value: 0x0002A600";
CM_ SG_ 861 IBST_d052_motTrvlRelReadFail "Bosch DTC value: 0x0002B200";
CM_ SG_ 861 IBST_d053_tle5012UnexpReset "Bosch DTC value: 0x0002F600";
CM_ SG_ 861 IBST_d054_bmsGateUndrvolt "Bosch DTC value: 0x0002F700";
CM_ SG_ 861 IBST_d055_kl15HwPlausSw "Bosch DTC value: 0x0002FE00";
CM_ SG_ 861 IBST_d056_ibNotShutDownRight "Bosch DTC value: 0x0002FF00";
CM_ SG_ 861 IBST_d057_cdmHardUndrvolt "Bosch DTC value: 0x00030A00";
CM_ SG_ 861 IBST_d058_cdmHardOvrvolt "Bosch DTC value: 0x00030B00";
CM_ SG_ 861 IBST_d059_maxTrvlAdjstUpdFail "Bosch DTC value: 0x00032C00";
CM_ SG_ 861 IBST_d060_ltmLimitReached "Bosch DTC value: 0x00032D00";
CM_ SG_ 861 IBST_d061_dcomEcuDefect "Bosch DTC value: 0x00032F00";
CM_ SG_ 861 IBST_d062_inputStroke1RngHigh "Bosch DTC value: 0x00034800";
CM_ SG_ 861 IBST_d063_inputStroke1RngLow "Bosch DTC value: 0x00034900";
CM_ SG_ 861 IBST_d064_inputStroke2RngHigh "Bosch DTC value: 0x00034A00";
CM_ SG_ 861 IBST_d065_inputStroke2RngLow "Bosch DTC value: 0x00034B00";
CM_ SG_ 861 IBST_d066_ibSupVoltDivDrift "Bosch DTC value: 0x00036600";
CM_ SG_ 861 IBST_d067_sOutRodToPressVal "Bosch DTC value: 0x00036700";
CM_ SG_ 861 IBST_d068_tle5012LifeCnt "Bosch DTC value: 0x00036800";
CM_ SG_ 861 IBST_d069_cdmExtendedUndrvolt "Bosch DTC value: 0x00037200";
CM_ SG_ 861 IBST_d070_cdmExtendedOvrvolt "Bosch DTC value: 0x00037300";
CM_ SG_ 861 IBST_d071_tempB6Ch1LineHigh "Bosch DTC value: 0x00037700";
CM_ SG_ 861 IBST_d072_tempB6Ch1LineLow "Bosch DTC value: 0x00037800";
CM_ SG_ 861 IBST_d073_tempB6Ch2LineHigh "Bosch DTC value: 0x00037900";
CM_ SG_ 861 IBST_d074_tempB6Ch2LineLow "Bosch DTC value: 0x00037A00";
CM_ SG_ 861 IBST_d075_hevSwitchOffDcom "Bosch DTC value: 0x00037B00";
CM_ SG_ 861 IBST_d076_tle5012VoltFail "Bosch DTC value: 0x00039A00";
CM_ SG_ 861 IBST_d077_bcsFltCurrentHigh "Bosch DTC value: 0x00039B00";
CM_ SG_ 861 IBST_d078_bcsFltCurrentLow "Bosch DTC value: 0x00039C00";
CM_ SG_ 861 IBST_d079_ecuSupVoltDivDrift "Bosch DTC value: 0x00056000";
CM_ SG_ 861 IBST_d080_inputstroke1Grad "Bosch DTC value: 0x00057B00";
CM_ SG_ 861 IBST_d081_pts1Err "Bosch DTC value: 0x00057B01";
CM_ SG_ 861 IBST_d082_pts1LineGnd "Bosch DTC value: 0x00057C00";
CM_ SG_ 861 IBST_d083_pts1LineHigh "Bosch DTC value: 0x00057D00";
CM_ SG_ 861 IBST_d084_inputStroke2Grad "Bosch DTC value: 0x0005DC00";
CM_ SG_ 861 IBST_d085_pts2Err "Bosch DTC value: 0x0005DC01";
CM_ SG_ 861 IBST_d086_pts2LineGnd "Bosch DTC value: 0x0005DD00";
CM_ SG_ 861 IBST_d087_pts2LineHigh "Bosch DTC value: 0x0005DE00";
CM_ SG_ 861 IBST_d088_faildevInputStroke "Bosch DTC value: 0x0005E000";
CM_ SG_ 861 IBST_d089_ptsOffsTooHigh "Bosch DTC value: 0x0005E001";
CM_ SG_ 861 IBST_d090_pbistErr "Bosch DTC value: 0x00060400";
CM_ SG_ 861 IBST_d091_ramInitErr "Bosch DTC value: 0x00060401";
CM_ SG_ 861 IBST_d092_ramsinlgeFlt "Bosch DTC value: 0x00060402";
CM_ SG_ 861 IBST_d093_bertFlt "Bosch DTC value: 0x00060700";
CM_ SG_ 861 IBST_d094_CalDataNotPlaus "Bosch DTC value: 0x00060701";
CM_ SG_ 861 IBST_d095_canEHwError "Bosch DTC value: 0x00060702";
CM_ SG_ 861 IBST_d096_canETout "Bosch DTC value: 0x00060703";
CM_ SG_ 861 IBST_d097_cpuException "Bosch DTC value: 0x00060704";
CM_ SG_ 861 IBST_d098_ecuBandGap "Bosch DTC value: 0x00060706";
CM_ SG_ 861 IBST_d099_ecuBmsOnWhileWdTout "Bosch DTC value: 0x00060707";
CM_ SG_ 861 IBST_d100_ecuErrpinCntTstFls "Bosch DTC value: 0x00060708";
CM_ SG_ 861 IBST_d101_ecuHetException "Bosch DTC value: 0x00060709";
CM_ SG_ 861 IBST_d102_ecuHetTuAddErr "Bosch DTC value: 0x0006070A";
CM_ SG_ 861 IBST_d103_ecuHetTuBusErr "Bosch DTC value: 0x0006070B";
CM_ SG_ 861 IBST_d104_ecuHetTuBusyErr "Bosch DTC value: 0x0006070C";
CM_ SG_ 861 IBST_d105_ecuHetTuException "Bosch DTC value: 0x0006070D";
CM_ SG_ 861 IBST_d106_ecuTaskMissing "Bosch DTC value: 0x0006070E";
CM_ SG_ 861 IBST_d107_hetRefError "Bosch DTC value: 0x0006070F";
CM_ SG_ 861 IBST_d108_micInitSpiTstFld "Bosch DTC value: 0x00060710";
CM_ SG_ 861 IBST_d109_micInitSpiTransfErr "Bosch DTC value: 0x00060711";
CM_ SG_ 861 IBST_d110_micIntMonGenBitMon "Bosch DTC value: 0x00060712";
CM_ SG_ 861 IBST_d111_micIntVoltMonFld "Bosch DTC value: 0x00060713";
CM_ SG_ 861 IBST_d112_motPosTrvlReadEmpty "Bosch DTC value: 0x00060714";
CM_ SG_ 861 IBST_d113_motAngBoundReadEmpt "Bosch DTC value: 0x00060715";
CM_ SG_ 861 IBST_d114_motShaftShiftDetect "Bosch DTC value: 0x00060716";
CM_ SG_ 861 IBST_d115_osErrHook "Bosch DTC value: 0x00060717";
CM_ SG_ 861 IBST_d116_pdurEInitFail "Bosch DTC value: 0x00060718";
CM_ SG_ 861 IBST_d117_pdurEPduInstLost "Bosch DTC value: 0x00060719";
CM_ SG_ 861 IBST_d118_pts1OffsEeReadEmpty "Bosch DTC value: 0x0006071A";
CM_ SG_ 861 IBST_d119_pts2OffsEeReadEmpty "Bosch DTC value: 0x0006071B";
CM_ SG_ 861 IBST_d120_rpsOffsXEeReadFail "Bosch DTC value: 0x0006071C";
CM_ SG_ 861 IBST_d121_rpsOffsYEeReadFail "Bosch DTC value: 0x0006071D";
CM_ SG_ 861 IBST_d122_rpsSynchEeReadFail "Bosch DTC value: 0x0006071E";
CM_ SG_ 861 IBST_d123_rpsAnglRecalcErr "Bosch DTC value: 0x0006071F";
CM_ SG_ 861 IBST_d124_motTrvlRelWriteFail "Bosch DTC value: 0x00060720";
CM_ SG_ 861 IBST_d125_motTrvlRelReadEmpty "Bosch DTC value: 0x00060721";
CM_ SG_ 861 IBST_d126_ptsEeReadEmpty "Bosch DTC value: 0x00060723";
CM_ SG_ 861 IBST_d127_ecuAdcConversionErr "Bosch DTC value: 0x00060B00";
CM_ SG_ 861 IBST_d128_ecuAdcSelftestErr "Bosch DTC value: 0x00060B01";
CM_ SG_ 861 IBST_d129_ccmFlt "Bosch DTC value: 0x00060C00";
CM_ SG_ 861 IBST_d130_ecuRomCheck "Bosch DTC value: 0x00060C01";
CM_ SG_ 861 IBST_d131_esmNmiFlt "Bosch DTC value: 0x00060C02";
CM_ SG_ 861 IBST_d132_esmSafetyFlt "Bosch DTC value: 0x00060C03";
CM_ SG_ 861 IBST_d133_motPosTrvlReadFail "Bosch DTC value: 0x00062F00";
CM_ SG_ 861 IBST_d134_motPosTrvlWriteFail "Bosch DTC value: 0x00062F01";
CM_ SG_ 861 IBST_d135_motAnglBndReadErr "Bosch DTC value: 0x00062F02";
CM_ SG_ 861 IBST_d136_motAnglBndWriteErr "Bosch DTC value: 0x00062F03";
CM_ SG_ 861 IBST_d137_motAnglGradTooLarge "Bosch DTC value: 0x00062F04";
CM_ SG_ 861 IBST_d138_pdmCustomerIdMis "Bosch DTC value: 0x00062F05";
CM_ SG_ 861 IBST_d139_pdmDtFormatMis "Bosch DTC value: 0x00062F06";
CM_ SG_ 861 IBST_d140_pdmOutOfMemory "Bosch DTC value: 0x00062F07";
CM_ SG_ 861 IBST_d141_pdmFieldSizeMis "Bosch DTC value: 0x00062F08";
CM_ SG_ 861 IBST_d142_pdmHwAcsErr "Bosch DTC value: 0x00062F09";
CM_ SG_ 861 IBST_d143_pdmInternalHWErr "Bosch DTC value: 0x00062F0A";
CM_ SG_ 861 IBST_d144_ptsCalHysWritFail "Bosch DTC value: 0x00062F0D";
CM_ SG_ 861 IBST_d145_ptsCalValuesChkFail "Bosch DTC value: 0x00062F0E";
CM_ SG_ 861 IBST_d146_pts1CalEeReadFail "Bosch DTC value: 0x00062F0F";
CM_ SG_ 861 IBST_d147_pts1CalEeWriteFail "Bosch DTC value: 0x00062F10";
CM_ SG_ 861 IBST_d148_rpsFailCompErr "Bosch DTC value: 0x00062F11";
CM_ SG_ 861 IBST_d149_pts1OffsEeWriteFail "Bosch DTC value: 0x00062F12";
CM_ SG_ 861 IBST_d150_pts2CalEeReadFail "Bosch DTC value: 0x00062F13";
CM_ SG_ 861 IBST_d151_pts2CalEeWriteFail "Bosch DTC value: 0x00062F14";
CM_ SG_ 861 IBST_d152_pts2OffsEeReadFail "Bosch DTC value: 0x00062F15";
CM_ SG_ 861 IBST_d153_pts2OffsEeWriteFail "Bosch DTC value: 0x00062F16";
CM_ SG_ 861 IBST_d154_rpsOffsXEeReadEmpty "Bosch DTC value: 0x00062F1D";
CM_ SG_ 861 IBST_d155_rpsOffsXEeWriteFail "Bosch DTC value: 0x00062F1E";
CM_ SG_ 861 IBST_d156_rpsOffsYEeReadEmpty "Bosch DTC value: 0x00062F1F";
CM_ SG_ 861 IBST_d157_rpsOffsYEeWriteFail "Bosch DTC value: 0x00062F20";
CM_ SG_ 861 IBST_d158_rpsSynchEeReadEmpty "Bosch DTC value: 0x00062F21";
CM_ SG_ 861 IBST_d159_rpsSynchEeWriteFail "Bosch DTC value: 0x00062F22";
CM_ SG_ 861 IBST_d160_assertionFail "Bosch DTC value: 0x00390000";
CM_ SG_ 861 IBST_d161_comsclBrkPrsPduLen "Bosch DTC value: 0x00390200";
CM_ SG_ 861 IBST_d162_comsclBrkPrsPduTout "Bosch DTC value: 0x00390300";
CM_ SG_ 861 IBST_d163_comsclEspIb1CntErr "Bosch DTC value: 0x00390400";
CM_ SG_ 861 IBST_d164_comsclEspIb1CsErr "Bosch DTC value: 0x00390500";
CM_ SG_ 861 IBST_d165_comsclEspIb1DlcErr "Bosch DTC value: 0x00390600";
CM_ SG_ 861 IBST_d166_comsclEspIb1Tout "Bosch DTC value: 0x00390700";
CM_ SG_ 861 IBST_d167_comsclEspIb2CntErr "Bosch DTC value: 0x00390800";
CM_ SG_ 861 IBST_d168_comsclEspIb2CsErr "Bosch DTC value: 0x00390900";
CM_ SG_ 861 IBST_d169_comsclEspIb2DlcErr "Bosch DTC value: 0x00390A00";
CM_ SG_ 861 IBST_d170_comsclEspIb2Tout "Bosch DTC value: 0x00390B00";
CM_ SG_ 861 IBST_d171_comsclEspIb3CntErr "Bosch DTC value: 0x00390C00";
CM_ SG_ 861 IBST_d172_comsclEspIb3CsErr "Bosch DTC value: 0x00390D00";
CM_ SG_ 861 IBST_d173_comsclEspIb3DlcErr "Bosch DTC value: 0x00390E00";
CM_ SG_ 861 IBST_d174_comsclEspIb3Tout "Bosch DTC value: 0x00390F00";
CM_ SG_ 861 IBST_d175_comsclGtwEsp1CntErr "Bosch DTC value: 0x00391000";
CM_ SG_ 861 IBST_d176_comsclGtwEsp1CsErr "Bosch DTC value: 0x00391100";
CM_ SG_ 861 IBST_d177_comsclGtwEsp1Corrpt "Bosch DTC value: 0x00391200";
CM_ SG_ 861 IBST_d178_comsclGtwEsp1Tout "Bosch DTC value: 0x00391300";
CM_ SG_ 861 IBST_d179_dcomSmrtActuNotInit "Bosch DTC value: 0x00391400";
CM_ SG_ 861 IBST_d180_rpsLengthAbsolHigh "Bosch DTC value: 0x00391500";
CM_ SG_ 861 IBST_d181_rpsLengthAbsolLow "Bosch DTC value: 0x00391600";
CM_ SG_ 861 IBST_d182_shutDownEeReadFail "Bosch DTC value: 0x00392600";
CM_ SG_ 861 IBST_d183_shutDownEeWriteFail "Bosch DTC value: 0x00392700";
CM_ SG_ 861 IBST_d184_maxTrvlAdjstReadErr "Bosch DTC value: 0x00392C00";
CM_ SG_ 861 IBST_d185_psOffsMcEeReadFail "Bosch DTC value: 0x00392F00";
CM_ SG_ 861 IBST_d186_psOffsMcEeWriteFail "Bosch DTC value: 0x00393000";
CM_ SG_ 861 IBST_d187_ltmSelfProtDeact "Bosch DTC value: 0x00399400";
CM_ SG_ 861 IBST_d188_pts1OffsEeReadFail "Bosch DTC value: 0x00399500";
CM_ SG_ 861 IBST_d189_diffStrokeRange "Bosch DTC value: 0x00520000";
CM_ SG_ 861 IBST_d190_notProgVin "Bosch DTC value: 0x00522051";
CM_ SG_ 861 IBST_d191_plausVin "Bosch DTC value: 0x00522062";
CM_ SG_ 861 IBST_d192_dlCorCSumVin "Bosch DTC value: 0x00522081";
CM_ SG_ 861 IBST_d193_ToutVin "Bosch DTC value: 0x00522087";
CM_ SG_ 861 IBST_d194_ecuEnableB6Fail "Bosch DTC value: 0x00A02D00";
CM_ SG_ 861 IBST_d195_ecuIbEnContErr "Bosch DTC value: 0x00A02D01";
CM_ SG_ 861 IBST_d196_sclEspIb1pEstMax "Bosch DTC value: 0x00C41600";
CM_ SG_ 861 IBST_d197_sclEspIb1VehSpd "Bosch DTC value: 0x00C41601";
CM_ SG_ 861 IBST_d198_sclEspIb2pLimExt "Bosch DTC value: 0x00C41602";
CM_ SG_ 861 IBST_d199_sclEspIb2qTarExt "Bosch DTC value: 0x00C41603";
CM_ SG_ 861 IBST_d200_sclEspIb3pFBlend "Bosch DTC value: 0x00C41604";
CM_ SG_ 861 IBST_d201_sclEspIb3pMc1 "Bosch DTC value: 0x00C41605";
CM_ SG_ 861 IBST_d202_sclEspIb3pTarDriver "Bosch DTC value: 0x00C41606";
CM_ SG_ 861 IBST_d203_netBusOffNet0 "Bosch DTC value: 0x00D0B800";
CM_ SG_ 861 IBST_d204_netErrPassivNet0 "Bosch DTC value: 0x00D0B801";
CM_ SG_ 861 IBST_d205_netBusOffNet1 "Bosch DTC value: 0x00D0B802";
CM_ SG_ 861 IBST_d206_netErrPassivNet1 "Bosch DTC value: 0x00D0B803";
CM_ SG_ 861 IBST_d207_maxStrokeReached "Bosch DTC value: 0x00522069";
CM_ SG_ 861 IBST_d208_sysSwClockMismatch "Bosch DTC value: 0x00060C04";
CM_ SG_ 861 IBST_d209_comsclGtwOdoCorrpt "Bosch DTC value: 0x00391201";
CM_ SG_ 861 IBST_d210_comsclGtwStatCorrpt "Bosch DTC value: 0x00391202";
CM_ SG_ 861 IBST_d211_comsclEpbStatCorrpt "Bosch DTC value: 0x00391203";
CM_ SG_ 861 IBST_d212_comsclGtwOdoTout "Bosch DTC value: 0x00391301";
CM_ SG_ 861 IBST_d213_comsclGtwStatTout "Bosch DTC value: 0x00391302";
CM_ SG_ 861 IBST_d214_comsclEpbStatTout "Bosch DTC value: 0x00391303";
CM_ SG_ 861 IBST_d215_comSclEpbStatCsErr "Bosch DTC value: 0x00391103";
CM_ SG_ 861 IBST_d216_comSclEpbStatCntFlt "Bosch DTC value: 0x00391003";
CM_ SG_ 861 IBST_d217_comSclDiTrq1Tout "Bosch DTC value: 0x00391304";
CM_ SG_ 861 IBST_d218_comSclDiTrq1Corrpt "Bosch DTC value: 0x00391204";
CM_ SG_ 861 IBST_d219_comSclDiTrq1CsErr "Bosch DTC value: 0x00391104";
CM_ SG_ 861 IBST_d220_comSclDiTrq1CntFlt "Bosch DTC value: 0x00391004";
CM_ SG_ 541 IBST_ebrStatusChecksum "Message checksum for IBST_extBrkReq message: sum of all bytes in message (Unused fields are set to 0) + originating CAN ID (0x2 + 0x1D = 0x1F).";
CM_ SG_ 541 IBST_ebrStatusCounter "Message counter: increments in each message.";
CM_ SG_ 541 IBST_ebrMode "State of IBST only to perform autonomous braking.";
CM_ SG_ 541 IBST_ebrSystemMode "State of system (ESP and IBST) to perform autonomous braking.";
CM_ SG_ 541 IBST_brakeTorqueTarget "Brake torque that the ESP targets in response to an external request.";
CM_ SG_ 541 IBST_ebrSource "Current source of external brake torque";
CM_ SG_ 541 IBST_ebrState "Current EBR activity";
CM_ SG_ 925 IBST_pedalCalCurrentCurve "Current Curve Number of Pedal Force Adjust (Curve 0 - 5)";
CM_ SG_ 925 IBST_iBoosterStatus "Indication of the iBooster functional status.";
CM_ SG_ 925 IBST_brakeInputStroke "iBooster brake input rod travel.";

BA_ "GatewayMessageSendType" BO_ 264 2;
BA_ "GenMsgCycleTime" BO_ 264 10;
BA_ "GenMsgCycleTime" BO_ 516 100;
BA_ "GenMsgSendType" BO_ 516 0;
BA_ "GenMsgCycleTime" BO_ 520 100;
BA_ "GenMsgSaltingFunction" BO_ 520 1;
BA_ "GenMsgCycleTime" BO_ 776 100;
BA_ "GenMsgCycleTimeFast" BO_ 776 100;
BA_ "GenMsgDelayTime" BO_ 776 20;
BA_ "GenMsgSendType" BO_ 776 0;
BA_ "GenMsgTimeOut" BO_ 776 500;
BA_ "GenMsgCycleTime" BO_ 840 100;
BA_ "GenMsgSaltingFunction" BO_ 840 1;
BA_ "AlertLogSubSystemId" BO_ 1469 198;
BA_ "GatewayHandlerEnum" BO_ 1469 2;
BA_ "GenMsgSendType" BO_ 1469 8;
BA_ "GenMsgCycleTime" BO_ 1645 500;
BA_ "GenMsgCycleTime" BO_ 861 1000;
BA_ "GenMsgCycleTime" BO_ 541 20;
BA_ "GenMsgSendType" BO_ 541 0;
BA_ "GenMsgCycleTime" BO_ 813 10000;
BA_ "GatewayHandlerEnum" BO_ 797 3;
BA_ "GenMsgSendType" BO_ 797 7;
BA_ "GenMsgCycleTime" BO_ 925 100;

CM_ SG_ 264 DI_torqueDriver "Driver requested torque command. SNA is 0xF000";
CM_ SG_ 264 DI_torque1Counter "Message counter for DI_torque1 message: increments in each message.";
CM_ SG_ 264 DI_torqueMotor "Applied motor torque command. SNA is 0xF000";
CM_ SG_ 264 DI_motorRPM "Drive Inverter measured motor shaft speed. SNA is 0x8000";
CM_ SG_ 264 DI_pedalPos "Drive Inverter measured pedal position.";
CM_ SG_ 264 DI_torque1Checksum "Message checksum for DI_torque1 message: sum of all bytes in message + 0x07";
CM_ SG_ 516 EPB_state "EPB state machine mode - EPB_STATE_PARK or EPB_STATE_HANDBRAKE means parking brake is applied";
CM_ SG_ 516 EPB_stateRequest "EPB requested state machine mode";
CM_ SG_ 516 EPB_brakeLight "Illuminates brake light when dynamic brake is engaged";
CM_ SG_ 516 EPB_substateL "EPB substate left motor";
CM_ SG_ 516 EPB_substateR "EPB substate right motor";
CM_ SG_ 516 EPB_statePending "EPB pending state machine mode";
CM_ SG_ 516 EPB_telltale "Illuminates telltale on the instrument cluster";
CM_ SG_ 520 GTW_ESP1Counter "Message counter for esp message, increments in each message.";
CM_ SG_ 520 GTW_hillStartAssistDisabled "Signal to disable the hill start assist feature. Was implemented as an enable signal prior to BL6.";
CM_ SG_ 520 GTW_brakeDiscWipeRequest "Request to trigger the brake disc wipe function in the ESP.";
CM_ SG_ 520 GTW_brakeFluidLow "Low brake fluid warning. Bosch qualification time on this is 20 seconds.";
CM_ SG_ 520 GTW_pedalCalRxEnable "Indication whether switching of pedal calibration target curves is allowed.";
CM_ SG_ 520 GTW_ambientTemperature "Ambient temperature (unfiltered value)";
CM_ SG_ 520 GTW_pedalCalTargetCurve "Indicates the desired iBooster pedal feel curve.";
CM_ SG_ 520 GTW_espModeSwitch "Periodic signal that is implemented like a momentary switch to indicate the user selected ESP mode.";
CM_ SG_ 520 GTW_ESP1Checksum "Message checksum for GTW_ESP1 message: sum of all bytes in message + originating CAN ID (0x2 + 0x08 = 0x0A)";
CM_ SG_ 776 GTW_easManualLevelRequest "UI (MCU) customer level request; Jack mode is used to disable leveling.";
CM_ SG_ 776 HVBatteryLow "Indication to Conti that we don't want them to use energy by leveling in postrun.";
CM_ SG_ 776 GTW_espPlatCalMismatch "Indication to the ESP that the calibration version does not match.";
CM_ SG_ 776 GTW_ibstConnectivityDisable "Signal to disable the iBooster from transmitting the connectivity messages for logging.";
CM_ SG_ 776 AMB_TEMP "Ambience temperature";
CM_ SG_ 776 GTW_ODO "Odometer";
CM_ SG_ 840 GTW_icPowerOff "Indicates that the gateway may soon pull power away from the instrument cluster.  This allows the IC to do a controlled shutdown.";
CM_ SG_ 840 GTW_hvacRailIsOn "GTW reporting HVAC rail is ON when set 1.";
CM_ SG_ 861 IBST_d000_bmsInitTestFail "Bosch DTC value: 0x00001C00";
CM_ SG_ 861 IBST_d001_bmcSingleTransTest "Bosch DTC value: 0x00002100";
CM_ SG_ 861 IBST_d002_tle5012SsccrcFail "Bosch DTC value: 0x00002500";
CM_ SG_ 861 IBST_d003_tle5012Config "Bosch DTC value: 0x00003500";
CM_ SG_ 861 IBST_d004_deadlMonTaskx1Ovr "Bosch DTC value: 0x00004F00";
CM_ SG_ 861 IBST_d005_ecuWdFltCntTstFls "Bosch DTC value: 0x00006200";
CM_ SG_ 861 IBST_d006_ecuWdScheduleTout "Bosch DTC value: 0x00006700";
CM_ SG_ 861 IBST_d007_ecuWdStarttestFls "Bosch DTC value: 0x00006800";
CM_ SG_ 861 IBST_d008_ecuWdStatusContErr "Bosch DTC value: 0x00006A00";
CM_ SG_ 861 IBST_d009_netOvrvolt "Bosch DTC value: 0x00006C00";
CM_ SG_ 861 IBST_d010_micSpiTout "Bosch DTC value: 0x00007200";
CM_ SG_ 861 IBST_d011_micSpiTransferErr "Bosch DTC value: 0x00007D00";
CM_ SG_ 861 IBST_d012_netUndvolt "Bosch DTC value: 0x00008500";
CM_ SG_ 861 IBST_d013_xpassToutErr "Bosch DTC value: 0x00009000";
CM_ SG_ 861 IBST_d014_rpsOffsEeReadEmpty "Bosch DTC value: 0x00009400";
CM_ SG_ 861 IBST_d015_rtpEnaHigh "Bosch DTC value: 0x00009500";
CM_ SG_ 861 IBST_d016_xpassEchoCountErr "Bosch DTC value: 0x00009900";
CM_ SG_ 861 IBST_d017_preDriveChckFail "Bosch DTC value: 0x00009E00";
CM_ SG_ 861 IBST_d018_ucSafetyFlt "Bosch DTC value: 0x0000A500";
CM_ SG_ 861 IBST_d019_unsupportedHw "Bosch DTC value: 0x0000A700";
CM_ SG_ 861 IBST_d020_voltPreRegModeFld "Bosch DTC value: 0x0000AA00";
CM_ SG_ 861 IBST_d021_ubbSupplyLine "Bosch DTC value: 0x0000AB00";
CM_ SG_ 861 IBST_d022_stmAswSysTout "Bosch DTC value: 0x0000B900";
CM_ SG_ 861 IBST_d023_stackOvrUndFlow "Bosch DTC value: 0x0000BB00";
CM_ SG_ 861 IBST_d024_smmOneReqsInit "Bosch DTC value: 0x0000C100";
CM_ SG_ 861 IBST_d025_ptsSupply "Bosch DTC value: 0x0000CC00";
CM_ SG_ 861 IBST_d026_ptsSupplyUndvolt "Bosch DTC value: 0x0000CD00";
CM_ SG_ 861 IBST_d027_tempB6Plaus "Bosch DTC value: 0x0000D600";
CM_ SG_ 861 IBST_d028_ecuWdErrCntContErr "Bosch DTC value: 0x0000DD00";
CM_ SG_ 861 IBST_d029_bmcShortedGateTest "Bosch DTC value: 0x0000E100";
CM_ SG_ 861 IBST_d030_controllerDevTooBig "Bosch DTC value: 0x0000E200";
CM_ SG_ 861 IBST_d031_ibDtrFail "Bosch DTC value: 0x0000E300";
CM_ SG_ 861 IBST_d032_oc6InitTestFail "Bosch DTC value: 0x0000E800";
CM_ SG_ 861 IBST_d033_oc6Monitor "Bosch DTC value: 0x0000E900";
CM_ SG_ 861 IBST_d034_motorOscillationDet "Bosch DTC value: 0x0000EA00";
CM_ SG_ 861 IBST_d035_rpsOffsEeReadFail "Bosch DTC value: 0x00010000";
CM_ SG_ 861 IBST_d036_sysErrHook "Bosch DTC value: 0x00025F00";
CM_ SG_ 861 IBST_d037_calIdlePosNotPlaus "Bosch DTC value: 0x00026100";
CM_ SG_ 861 IBST_d038_boostSupUndrvolt "Bosch DTC value: 0x00026300";
CM_ SG_ 861 IBST_d039_calRoutineAbort "Bosch DTC value: 0x00026800";
CM_ SG_ 861 IBST_d040_bmcGateUndervoltPro "Bosch DTC value: 0x00026900";
CM_ SG_ 861 IBST_d041_hswInitPhseUndrvolt "Bosch DTC value: 0x00026C00";
CM_ SG_ 861 IBST_d042_ltmWarnLevelReached "Bosch DTC value: 0x00026D00";
CM_ SG_ 861 IBST_d043_rpsVctrLengthRelErr "Bosch DTC value: 0x00027200";
CM_ SG_ 861 IBST_d044_b6TempDegradeLevel1 "Bosch DTC value: 0x00028100";
CM_ SG_ 861 IBST_d045_B6TempDegradeLevel2 "Bosch DTC value: 0x00028200";
CM_ SG_ 861 IBST_d046_spiAnglOrRawNotUp "Bosch DTC value: 0x00028400";
CM_ SG_ 861 IBST_d047_dcomIboosterNotInit "Bosch DTC value: 0x00029F00";
CM_ SG_ 861 IBST_d048_unintendMotorReturn "Bosch DTC value: 0x0002A000";
CM_ SG_ 861 IBST_d049_cdmOvrvoltLevel1 "Bosch DTC value: 0x0002A400";
CM_ SG_ 861 IBST_d050_cdmUndrvoltLevel2 "Bosch DTC value: 0x0002A500";
CM_ SG_ 861 IBST_d051_cdmUndrvoltLevel1 "Bosch DTC value: 0x0002A600";
CM_ SG_ 861 IBST_d052_motTrvlRelReadFail "Bosch DTC value: 0x0002B200";
CM_ SG_ 861 IBST_d053_tle5012UnexpReset "Bosch DTC value: 0x0002F600";
CM_ SG_ 861 IBST_d054_bmsGateUndrvolt "Bosch DTC value: 0x0002F700";
CM_ SG_ 861 IBST_d055_kl15HwPlausSw "Bosch DTC value: 0x0002FE00";
CM_ SG_ 861 IBST_d056_ibNotShutDownRight "Bosch DTC value: 0x0002FF00";
CM_ SG_ 861 IBST_d057_cdmHardUndrvolt "Bosch DTC value: 0x00030A00";
CM_ SG_ 861 IBST_d058_cdmHardOvrvolt "Bosch DTC value: 0x00030B00";
CM_ SG_ 861 IBST_d059_maxTrvlAdjstUpdFail "Bosch DTC value: 0x00032C00";
CM_ SG_ 861 IBST_d060_ltmLimitReached "Bosch DTC value: 0x00032D00";
CM_ SG_ 861 IBST_d061_dcomEcuDefect "Bosch DTC value: 0x00032F00";
CM_ SG_ 861 IBST_d062_inputStroke1RngHigh "Bosch DTC value: 0x00034800";
CM_ SG_ 861 IBST_d063_inputStroke1RngLow "Bosch DTC value: 0x00034900";
CM_ SG_ 861 IBST_d064_inputStroke2RngHigh "Bosch DTC value: 0x00034A00";
CM_ SG_ 861 IBST_d065_inputStroke2RngLow "Bosch DTC value: 0x00034B00";
CM_ SG_ 861 IBST_d066_ibSupVoltDivDrift "Bosch DTC value: 0x00036600";
CM_ SG_ 861 IBST_d067_sOutRodToPressVal "Bosch DTC value: 0x00036700";
CM_ SG_ 861 IBST_d068_tle5012LifeCnt "Bosch DTC value: 0x00036800";
CM_ SG_ 861 IBST_d069_cdmExtendedUndrvolt "Bosch DTC value: 0x00037200";
CM_ SG_ 861 IBST_d070_cdmExtendedOvrvolt "Bosch DTC value: 0x00037300";
CM_ SG_ 861 IBST_d071_tempB6Ch1LineHigh "Bosch DTC value: 0x00037700";
CM_ SG_ 861 IBST_d072_tempB6Ch1LineLow "Bosch DTC value: 0x00037800";
CM_ SG_ 861 IBST_d073_tempB6Ch2LineHigh "Bosch DTC value: 0x00037900";
CM_ SG_ 861 IBST_d074_tempB6Ch2LineLow "Bosch DTC value: 0x00037A00";
CM_ SG_ 861 IBST_d075_hevSwitchOffDcom "Bosch DTC value: 0x00037B00";
CM_ SG_ 861 IBST_d076_tle5012VoltFail "Bosch DTC value: 0x00039A00";
CM_ SG_ 861 IBST_d077_bcsFltCurrentHigh "Bosch DTC value: 0x00039B00";
CM_ SG_ 861 IBST_d078_bcsFltCurrentLow "Bosch DTC value: 0x00039C00";
CM_ SG_ 861 IBST_d079_ecuSupVoltDivDrift "Bosch DTC value: 0x00056000";
CM_ SG_ 861 IBST_d080_inputstroke1Grad "Bosch DTC value: 0x00057B00";
CM_ SG_ 861 IBST_d081_pts1Err "Bosch DTC value: 0x00057B01";
CM_ SG_ 861 IBST_d082_pts1LineGnd "Bosch DTC value: 0x00057C00";
CM_ SG_ 861 IBST_d083_pts1LineHigh "Bosch DTC value: 0x00057D00";
CM_ SG_ 861 IBST_d084_inputStroke2Grad "Bosch DTC value: 0x0005DC00";
CM_ SG_ 861 IBST_d085_pts2Err "Bosch DTC value: 0x0005DC01";
CM_ SG_ 861 IBST_d086_pts2LineGnd "Bosch DTC value: 0x0005DD00";
CM_ SG_ 861 IBST_d087_pts2LineHigh "Bosch DTC value: 0x0005DE00";
CM_ SG_ 861 IBST_d088_faildevInputStroke "Bosch DTC value: 0x0005E000";
CM_ SG_ 861 IBST_d089_ptsOffsTooHigh "Bosch DTC value: 0x0005E001";
CM_ SG_ 861 IBST_d090_pbistErr "Bosch DTC value: 0x00060400";
CM_ SG_ 861 IBST_d091_ramInitErr "Bosch DTC value: 0x00060401";
CM_ SG_ 861 IBST_d092_ramsinlgeFlt "Bosch DTC value: 0x00060402";
CM_ SG_ 861 IBST_d093_bertFlt "Bosch DTC value: 0x00060700";
CM_ SG_ 861 IBST_d094_CalDataNotPlaus "Bosch DTC value: 0x00060701";
CM_ SG_ 861 IBST_d095_canEHwError "Bosch DTC value: 0x00060702";
CM_ SG_ 861 IBST_d096_canETout "Bosch DTC value: 0x00060703";
CM_ SG_ 861 IBST_d097_cpuException "Bosch DTC value: 0x00060704";
CM_ SG_ 861 IBST_d098_ecuBandGap "Bosch DTC value: 0x00060706";
CM_ SG_ 861 IBST_d099_ecuBmsOnWhileWdTout "Bosch DTC value: 0x00060707";
CM_ SG_ 861 IBST_d100_ecuErrpinCntTstFls "Bosch DTC value: 0x00060708";
CM_ SG_ 861 IBST_d101_ecuHetException "Bosch DTC value: 0x00060709";
CM_ SG_ 861 IBST_d102_ecuHetTuAddErr "Bosch DTC value: 0x0006070A";
CM_ SG_ 861 IBST_d103_ecuHetTuBusErr "Bosch DTC value: 0x0006070B";
CM_ SG_ 861 IBST_d104_ecuHetTuBusyErr "Bosch DTC value: 0x0006070C";
CM_ SG_ 861 IBST_d105_ecuHetTuException "Bosch DTC value: 0x0006070D";
CM_ SG_ 861 IBST_d106_ecuTaskMissing "Bosch DTC value: 0x0006070E";
CM_ SG_ 861 IBST_d107_hetRefError "Bosch DTC value: 0x0006070F";
CM_ SG_ 861 IBST_d108_micInitSpiTstFld "Bosch DTC value: 0x00060710";
CM_ SG_ 861 IBST_d109_micInitSpiTransfErr "Bosch DTC value: 0x00060711";
CM_ SG_ 861 IBST_d110_micIntMonGenBitMon "Bosch DTC value: 0x00060712";
CM_ SG_ 861 IBST_d111_micIntVoltMonFld "Bosch DTC value: 0x00060713";
CM_ SG_ 861 IBST_d112_motPosTrvlReadEmpty "Bosch DTC value: 0x00060714";
CM_ SG_ 861 IBST_d113_motAngBoundReadEmpt "Bosch DTC value: 0x00060715";
CM_ SG_ 861 IBST_d114_motShaftShiftDetect "Bosch DTC value: 0x00060716";
CM_ SG_ 861 IBST_d115_osErrHook "Bosch DTC value: 0x00060717";
CM_ SG_ 861 IBST_d116_pdurEInitFail "Bosch DTC value: 0x00060718";
CM_ SG_ 861 IBST_d117_pdurEPduInstLost "Bosch DTC value: 0x00060719";
CM_ SG_ 861 IBST_d118_pts1OffsEeReadEmpty "Bosch DTC value: 0x0006071A";
CM_ SG_ 861 IBST_d119_pts2OffsEeReadEmpty "Bosch DTC value: 0x0006071B";
CM_ SG_ 861 IBST_d120_rpsOffsXEeReadFail "Bosch DTC value: 0x0006071C";
CM_ SG_ 861 IBST_d121_rpsOffsYEeReadFail "Bosch DTC value: 0x0006071D";
CM_ SG_ 861 IBST_d122_rpsSynchEeReadFail "Bosch DTC value: 0x0006071E";
CM_ SG_ 861 IBST_d123_rpsAnglRecalcErr "Bosch DTC value: 0x0006071F";
CM_ SG_ 861 IBST_d124_motTrvlRelWriteFail "Bosch DTC value: 0x00060720";
CM_ SG_ 861 IBST_d125_motTrvlRelReadEmpty "Bosch DTC value: 0x00060721";
CM_ SG_ 861 IBST_d126_ptsEeReadEmpty "Bosch DTC value: 0x00060723";
CM_ SG_ 861 IBST_d127_ecuAdcConversionErr "Bosch DTC value: 0x00060B00";
CM_ SG_ 861 IBST_d128_ecuAdcSelftestErr "Bosch DTC value: 0x00060B01";
CM_ SG_ 861 IBST_d129_ccmFlt "Bosch DTC value: 0x00060C00";
CM_ SG_ 861 IBST_d130_ecuRomCheck "Bosch DTC value: 0x00060C01";
CM_ SG_ 861 IBST_d131_esmNmiFlt "Bosch DTC value: 0x00060C02";
CM_ SG_ 861 IBST_d132_esmSafetyFlt "Bosch DTC value: 0x00060C03";
CM_ SG_ 861 IBST_d133_motPosTrvlReadFail "Bosch DTC value: 0x00062F00";
CM_ SG_ 861 IBST_d134_motPosTrvlWriteFail "Bosch DTC value: 0x00062F01";
CM_ SG_ 861 IBST_d135_motAnglBndReadErr "Bosch DTC value: 0x00062F02";
CM_ SG_ 861 IBST_d136_motAnglBndWriteErr "Bosch DTC value: 0x00062F03";
CM_ SG_ 861 IBST_d137_motAnglGradTooLarge "Bosch DTC value: 0x00062F04";
CM_ SG_ 861 IBST_d138_pdmCustomerIdMis "Bosch DTC value: 0x00062F05";
CM_ SG_ 861 IBST_d139_pdmDtFormatMis "Bosch DTC value: 0x00062F06";
CM_ SG_ 861 IBST_d140_pdmOutOfMemory "Bosch DTC value: 0x00062F07";
CM_ SG_ 861 IBST_d141_pdmFieldSizeMis "Bosch DTC value: 0x00062F08";
CM_ SG_ 861 IBST_d142_pdmHwAcsErr "Bosch DTC value: 0x00062F09";
CM_ SG_ 861 IBST_d143_pdmInternalHWErr "Bosch DTC value: 0x00062F0A";
CM_ SG_ 861 IBST_d144_ptsCalHysWritFail "Bosch DTC value: 0x00062F0D";
CM_ SG_ 861 IBST_d145_ptsCalValuesChkFail "Bosch DTC value: 0x00062F0E";
CM_ SG_ 861 IBST_d146_pts1CalEeReadFail "Bosch DTC value: 0x00062F0F";
CM_ SG_ 861 IBST_d147_pts1CalEeWriteFail "Bosch DTC value: 0x00062F10";
CM_ SG_ 861 IBST_d148_rpsFailCompErr "Bosch DTC value: 0x00062F11";
CM_ SG_ 861 IBST_d149_pts1OffsEeWriteFail "Bosch DTC value: 0x00062F12";
CM_ SG_ 861 IBST_d150_pts2CalEeReadFail "Bosch DTC value: 0x00062F13";
CM_ SG_ 861 IBST_d151_pts2CalEeWriteFail "Bosch DTC value: 0x00062F14";
CM_ SG_ 861 IBST_d152_pts2OffsEeReadFail "Bosch DTC value: 0x00062F15";
CM_ SG_ 861 IBST_d153_pts2OffsEeWriteFail "Bosch DTC value: 0x00062F16";
CM_ SG_ 861 IBST_d154_rpsOffsXEeReadEmpty "Bosch DTC value: 0x00062F1D";
CM_ SG_ 861 IBST_d155_rpsOffsXEeWriteFail "Bosch DTC value: 0x00062F1E";
CM_ SG_ 861 IBST_d156_rpsOffsYEeReadEmpty "Bosch DTC value: 0x00062F1F";
CM_ SG_ 861 IBST_d157_rpsOffsYEeWriteFail "Bosch DTC value: 0x00062F20";
CM_ SG_ 861 IBST_d158_rpsSynchEeReadEmpty "Bosch DTC value: 0x00062F21";
CM_ SG_ 861 IBST_d159_rpsSynchEeWriteFail "Bosch DTC value: 0x00062F22";
CM_ SG_ 861 IBST_d160_assertionFail "Bosch DTC value: 0x00390000";
CM_ SG_ 861 IBST_d161_comsclBrkPrsPduLen "Bosch DTC value: 0x00390200";
CM_ SG_ 861 IBST_d162_comsclBrkPrsPduTout "Bosch DTC value: 0x00390300";
CM_ SG_ 861 IBST_d163_comsclEspIb1CntErr "Bosch DTC value: 0x00390400";
CM_ SG_ 861 IBST_d164_comsclEspIb1CsErr "Bosch DTC value: 0x00390500";
CM_ SG_ 861 IBST_d165_comsclEspIb1DlcErr "Bosch DTC value: 0x00390600";
CM_ SG_ 861 IBST_d166_comsclEspIb1Tout "Bosch DTC value: 0x00390700";
CM_ SG_ 861 IBST_d167_comsclEspIb2CntErr "Bosch DTC value: 0x00390800";
CM_ SG_ 861 IBST_d168_comsclEspIb2CsErr "Bosch DTC value: 0x00390900";
CM_ SG_ 861 IBST_d169_comsclEspIb2DlcErr "Bosch DTC value: 0x00390A00";
CM_ SG_ 861 IBST_d170_comsclEspIb2Tout "Bosch DTC value: 0x00390B00";
CM_ SG_ 861 IBST_d171_comsclEspIb3CntErr "Bosch DTC value: 0x00390C00";
CM_ SG_ 861 IBST_d172_comsclEspIb3CsErr "Bosch DTC value: 0x00390D00";
CM_ SG_ 861 IBST_d173_comsclEspIb3DlcErr "Bosch DTC value: 0x00390E00";
CM_ SG_ 861 IBST_d174_comsclEspIb3Tout "Bosch DTC value: 0x00390F00";
CM_ SG_ 861 IBST_d175_comsclGtwEsp1CntErr "Bosch DTC value: 0x00391000";
CM_ SG_ 861 IBST_d176_comsclGtwEsp1CsErr "Bosch DTC value: 0x00391100";
CM_ SG_ 861 IBST_d177_comsclGtwEsp1Corrpt "Bosch DTC value: 0x00391200";
CM_ SG_ 861 IBST_d178_comsclGtwEsp1Tout "Bosch DTC value: 0x00391300";
CM_ SG_ 861 IBST_d179_dcomSmrtActuNotInit "Bosch DTC value: 0x00391400";
CM_ SG_ 861 IBST_d180_rpsLengthAbsolHigh "Bosch DTC value: 0x00391500";
CM_ SG_ 861 IBST_d181_rpsLengthAbsolLow "Bosch DTC value: 0x00391600";
CM_ SG_ 861 IBST_d182_shutDownEeReadFail "Bosch DTC value: 0x00392600";
CM_ SG_ 861 IBST_d183_shutDownEeWriteFail "Bosch DTC value: 0x00392700";
CM_ SG_ 861 IBST_d184_maxTrvlAdjstReadErr "Bosch DTC value: 0x00392C00";
CM_ SG_ 861 IBST_d185_psOffsMcEeReadFail "Bosch DTC value: 0x00392F00";
CM_ SG_ 861 IBST_d186_psOffsMcEeWriteFail "Bosch DTC value: 0x00393000";
CM_ SG_ 861 IBST_d187_ltmSelfProtDeact "Bosch DTC value: 0x00399400";
CM_ SG_ 861 IBST_d188_pts1OffsEeReadFail "Bosch DTC value: 0x00399500";
CM_ SG_ 861 IBST_d189_diffStrokeRange "Bosch DTC value: 0x00520000";
CM_ SG_ 861 IBST_d190_notProgVin "Bosch DTC value: 0x00522051";
CM_ SG_ 861 IBST_d191_plausVin "Bosch DTC value: 0x00522062";
CM_ SG_ 861 IBST_d192_dlCorCSumVin "Bosch DTC value: 0x00522081";
CM_ SG_ 861 IBST_d193_ToutVin "Bosch DTC value: 0x00522087";
CM_ SG_ 861 IBST_d194_ecuEnableB6Fail "Bosch DTC value: 0x00A02D00";
CM_ SG_ 861 IBST_d195_ecuIbEnContErr "Bosch DTC value: 0x00A02D01";
CM_ SG_ 861 IBST_d196_sclEspIb1pEstMax "Bosch DTC value: 0x00C41600";
CM_ SG_ 861 IBST_d197_sclEspIb1VehSpd "Bosch DTC value: 0x00C41601";
CM_ SG_ 861 IBST_d198_sclEspIb2pLimExt "Bosch DTC value: 0x00C41602";
CM_ SG_ 861 IBST_d199_sclEspIb2qTarExt "Bosch DTC value: 0x00C41603";
CM_ SG_ 861 IBST_d200_sclEspIb3pFBlend "Bosch DTC value: 0x00C41604";
CM_ SG_ 861 IBST_d201_sclEspIb3pMc1 "Bosch DTC value: 0x00C41605";
CM_ SG_ 861 IBST_d202_sclEspIb3pTarDriver "Bosch DTC value: 0x00C41606";
CM_ SG_ 861 IBST_d203_netBusOffNet0 "Bosch DTC value: 0x00D0B800";
CM_ SG_ 861 IBST_d204_netErrPassivNet0 "Bosch DTC value: 0x00D0B801";
CM_ SG_ 861 IBST_d205_netBusOffNet1 "Bosch DTC value: 0x00D0B802";
CM_ SG_ 861 IBST_d206_netErrPassivNet1 "Bosch DTC value: 0x00D0B803";
CM_ SG_ 861 IBST_d207_maxStrokeReached "Bosch DTC value: 0x00522069";
CM_ SG_ 861 IBST_d208_sysSwClockMismatch "Bosch DTC value: 0x00060C04";
CM_ SG_ 861 IBST_d209_comsclGtwOdoCorrpt "Bosch DTC value: 0x00391201";
CM_ SG_ 861 IBST_d210_comsclGtwStatCorrpt "Bosch DTC value: 0x00391202";
CM_ SG_ 861 IBST_d211_comsclEpbStatCorrpt "Bosch DTC value: 0x00391203";
CM_ SG_ 861 IBST_d212_comsclGtwOdoTout "Bosch DTC value: 0x00391301";
CM_ SG_ 861 IBST_d213_comsclGtwStatTout "Bosch DTC value: 0x00391302";
CM_ SG_ 861 IBST_d214_comsclEpbStatTout "Bosch DTC value: 0x00391303";
CM_ SG_ 861 IBST_d215_comSclEpbStatCsErr "Bosch DTC value: 0x00391103";
CM_ SG_ 861 IBST_d216_comSclEpbStatCntFlt "Bosch DTC value: 0x00391003";
CM_ SG_ 861 IBST_d217_comSclDiTrq1Tout "Bosch DTC value: 0x00391304";
CM_ SG_ 861 IBST_d218_comSclDiTrq1Corrpt "Bosch DTC value: 0x00391204";
CM_ SG_ 861 IBST_d219_comSclDiTrq1CsErr "Bosch DTC value: 0x00391104";
CM_ SG_ 861 IBST_d220_comSclDiTrq1CntFlt "Bosch DTC value: 0x00391004";
CM_ SG_ 541 IBST_ebrStatusChecksum "Message checksum for IBST_extBrkReq message: sum of all bytes in message (Unused fields are set to 0) + originating CAN ID (0x2 + 0x1D = 0x1F).";
CM_ SG_ 541 IBST_ebrStatusCounter "Message counter: increments in each message.";
CM_ SG_ 541 IBST_ebrMode "State of IBST only to perform autonomous braking.";
CM_ SG_ 541 IBST_ebrSystemMode "State of system (ESP and IBST) to perform autonomous braking.";
CM_ SG_ 541 IBST_brakeTorqueTarget "Brake torque that the ESP targets in response to an external request.";
CM_ SG_ 541 IBST_ebrSource "Current source of external brake torque";
CM_ SG_ 541 IBST_ebrState "Current EBR activity";
CM_ SG_ 925 IBST_pedalCalCurrentCurve "Current Curve Number of Pedal Force Adjust (Curve 0 - 5)";
CM_ SG_ 925 IBST_iBoosterStatus "Indication of the iBooster functional status.";
CM_ SG_ 925 IBST_brakeInputStroke "iBooster brake input rod travel.";

VAL_ 264 DI_torqueDriver -4096 "SNA" ;
VAL_ 264 DI_torqueMotor -4096 "SNA" ;
VAL_ 264 DI_soptState 7 "SOPT_SNA" 6 "SOPT_TEST_FAILED" 5 "SOPT_TEST_SKIPPED" 4 "SOPT_TEST_PASSED" 3 "SOPT_CURRENT_TEST" 2 "SOPT_ASC_TEST" 1 "SOPT_PSTG_BRING_UP" 0 "SOPT_INIT" ;
VAL_ 264 DI_motorRPM -32768 "SNA" ;
VAL_ 264 DI_pedalPos 255 "SNA" ;
VAL_ 516 EPB_state 7 "EPB_STATE_SNA" 6 "EPB_STATE_SELFPARK" 5 "EPB_STATE_SERVICE" 4 "EPB_STATE_START" 3 "EPB_STATE_HANDBRAKE" 2 "EPB_STATE_PARK" 1 "EPB_STATE_DYNAMIC" 0 "EPB_STATE_OPEN" ;
VAL_ 516 EPB_stateRequest 7 "EPB_STATE_SNA" 6 "EPB_STATE_SELFPARK" 5 "EPB_STATE_SERVICE" 4 "EPB_STATE_START" 3 "EPB_STATE_HANDBRAKE" 2 "EPB_STATE_PARK" 1 "EPB_STATE_DYNAMIC" 0 "EPB_STATE_OPEN" ;
VAL_ 516 EPB_substateL 4 "EPB_SUBSTATE_CLR_FAULT" 3 "EPB_SUBSTATE_FAULT" 2 "EPB_SUBSTATE_RELEASING" 1 "EPB_SUBSTATE_APPLYING" 0 "EPB_SUBSTATE_STATIONARY" ;
VAL_ 516 EPB_substateR 4 "EPB_SUBSTATE_CLR_FAULT" 3 "EPB_SUBSTATE_FAULT" 2 "EPB_SUBSTATE_RELEASING" 1 "EPB_SUBSTATE_APPLYING" 0 "EPB_SUBSTATE_STATIONARY" ;
VAL_ 516 EPB_freeRollingModeStatus 2 "EPB_FREE_ROLLING_MODE_ENABLED" 1 "EPB_FREE_ROLLING_MODE_AVAILABLE" 0 "EPB_FREE_ROLLING_MODE_UNAVAILABLE" ;
VAL_ 516 EPB_brakeApplied 3 "SNA" 1 "APPLIED" 0 "RELEASED" ;
VAL_ 516 EPB_statePending 7 "EPB_STATE_SNA" 6 "EPB_STATE_SELFPARK" 5 "EPB_STATE_SERVICE" 4 "EPB_STATE_START" 3 "EPB_STATE_HANDBRAKE" 2 "EPB_STATE_PARK" 1 "EPB_STATE_DYNAMIC" 0 "EPB_STATE_OPEN" ;
VAL_ 516 EPB_calibrationStateLeft 4 "CAL_BUSY" 3 "CAL_FAULT" 2 "CAL_WARN" 1 "CAL_NORMAL" 0 "CAL_UNAVAILABLE" ;
VAL_ 516 EPB_ignoreCan 3 "IGNORE_CAN_SNA" 2 "IGNORE_CAN_UPDATE" 1 "LISTEN_TO_CAN" 0 "IGNORE_CAN_BOOT" ;
VAL_ 516 EPB_selfParkState 5 "SELFPARK_FAULT" 4 "SELFPARK_COMPLETE" 3 "SELFPARK_ACTIVE" 2 "SELFPARK_ARMED" 1 "SELFPARK_IDLE" 0 "SELFPARK_INIT" ;
VAL_ 516 EPB_telltale 7 "EPB_TELLTALE_SNA" 3 "LAMP_RED_FLASH_AMBER_ON" 2 "LAMP_AMBER_ON" 1 "LAMP_RED_ON" 0 "LAMP_OFF" ;
VAL_ 516 EPB_syncState 3 "EPB_SYNCSTATE_READY" 2 "EPB_SYNCSTATE_SYNCING" 1 "EPB_SYNCSTATE_LOSTSYNC" 0 "EPB_SYNCSTATE_INIT" ;
VAL_ 516 EPB_calibrationStateRight 4 "CAL_BUSY" 3 "CAL_FAULT" 2 "CAL_WARN" 1 "CAL_NORMAL" 0 "CAL_UNAVAILABLE" ;
VAL_ 520 GTW_hillStartAssistDisabled 1 "HSA_DISABLED" 0 "HSA_ENABLED" ;
VAL_ 520 GTW_brakeDiscWipeRequest 3 "BDW_SNA" 2 "BDW_STRONG" 1 "BDW_LIGHT" 0 "BDW_NO_REQUEST" ;
VAL_ 520 GTW_pedalCalRxEnable 1 "ENABLED" 0 "DISABLED" ;
VAL_ 520 GTW_ambientTemperature 255 "SNA" ;
VAL_ 520 GTW_pedalCalTargetCurve 6 "SNA" 5 "PEDAL_CURVE_5" 4 "PEDAL_CURVE_4" 3 "PEDAL_CURVE_3" 2 "PEDAL_CURVE_2" 1 "PEDAL_CURVE_1" 0 "PEDAL_CURVE_0" ;
VAL_ 520 GTW_espModeSwitch 5 "SWITCH_03_PRESSED_ESP_DEV_2" 4 "SWITCH_02_PRESSED_ESP_DEV_1" 3 "SWITCH_01_PRESSED_TC_OFF" 2 "SNA" 1 "SWITCH_00_PRESSED_NORMAL" 0 "SWITCH_NOT_PRESSED" ;
VAL_ 776 GTW_easManualLevelRequest 7 "REQUEST_VERY_LOW_LEVEL" 6 "SWITCH_DEFECT" 5 "TOGGLE_JACK_MODE" 4 "REQUEST_VERY_HIGH_LEVEL" 3 "REQUEST_HIGH_LEVEL" 2 "REQUEST_NORMAL_LEVEL" 1 "REQUEST_LOW_LEVEL" 0 "REQUEST_NONE" ;
VAL_ 776 GTW_espPlatCalMismatch 1 "MISMATCHED_CAL" 0 "VALID_CAL" ;
VAL_ 776 GTW_ibstConnectivityDisable 1 "CONNECTIVITY_DISABLED" 0 "CONNECTIVITY_ENABLED" ;
VAL_ 776 AMB_TEMP 255 "SNA" ;
VAL_ 776 GTW_ODO 16777215 "SNA" 16777214 "Init" ;
VAL_ 776 DI_tireFitment 3 "FITMENT_SNA" 1 "FITMENT_STAGGERED" 0 "FITMENT_SQUARE" ;
VAL_ 776 DI_steerCenter -128 "SNA" ;
VAL_ 840 GTW_vehiclePowerState 1 "DRIVE" 0 "NOT_DRIVE" ;
VAL_ 840 DOOR_STATE_RearTrunk 3 "SNA" 2 "Init" 1 "open" 0 "closed" ;
VAL_ 1469 IBST_alertID 16604 "IBST_d220_comSclDiTrq1CntFlt" 16603 "IBST_d219_comSclDiTrq1CsErr" 16602 "IBST_d218_comSclDiTrq1Corrpt" 16601 "IBST_d217_comSclDiTrq1Tout" 16600 "IBST_d216_comSclEpbStatCntFlt" 16599 "IBST_d215_comSclEpbStatCsErr" 16598 "IBST_d214_comsclEpbStatTout" 16597 "IBST_d213_comsclGtwStatTout" 16596 "IBST_d212_comsclGtwOdoTout" 16595 "IBST_d211_comsclEpbStatCorrpt" 16594 "IBST_d210_comsclGtwStatCorrpt" 16593 "IBST_d209_comsclGtwOdoCorrpt" 16592 "IBST_d208_sysSwClockMismatch" 16591 "IBST_d207_maxStrokeReached" 16590 "IBST_d206_netErrPassivNet1" 16589 "IBST_d205_netBusOffNet1" 16588 "IBST_d204_netErrPassivNet0" 16587 "IBST_d203_netBusOffNet0" 16586 "IBST_d202_sclEspIb3pTarDriver" 16585 "IBST_d201_sclEspIb3pMc1" 16584 "IBST_d200_sclEspIb3pFBlend" 16583 "IBST_d199_sclEspIb2qTarExt" 16582 "IBST_d198_sclEspIb2pLimExt" 16581 "IBST_d197_sclEspIb1VehSpd" 16580 "IBST_d196_sclEspIb1pEstMax" 16579 "IBST_d195_ecuIbEnContErr" 16578 "IBST_d194_ecuEnableB6Fail" 16577 "IBST_d193_ToutVin" 16576 "IBST_d192_dlCorCSumVin" 16575 "IBST_d191_plausVin" 16574 "IBST_d190_notProgVin" 16573 "IBST_d189_diffStrokeRange" 16572 "IBST_d188_pts1OffsEeReadFail" 16571 "IBST_d187_ltmSelfProtDeact" 16570 "IBST_d186_psOffsMcEeWriteFail" 16569 "IBST_d185_psOffsMcEeReadFail" 16568 "IBST_d184_maxTrvlAdjstReadErr" 16567 "IBST_d183_shutDownEeWriteFail" 16566 "IBST_d182_shutDownEeReadFail" 16565 "IBST_d181_rpsLengthAbsolLow" 16564 "IBST_d180_rpsLengthAbsolHigh" 16563 "IBST_d179_dcomSmrtActuNotInit" 16562 "IBST_d178_comsclGtwEsp1Tout" 16561 "IBST_d177_comsclGtwEsp1Corrpt" 16560 "IBST_d176_comsclGtwEsp1CsErr" 16559 "IBST_d175_comsclGtwEsp1CntErr" 16558 "IBST_d174_comsclEspIb3Tout" 16557 "IBST_d173_comsclEspIb3DlcErr" 16556 "IBST_d172_comsclEspIb3CsErr" 16555 "IBST_d171_comsclEspIb3CntErr" 16554 "IBST_d170_comsclEspIb2Tout" 16553 "IBST_d169_comsclEspIb2DlcErr" 16552 "IBST_d168_comsclEspIb2CsErr" 16551 "IBST_d167_comsclEspIb2CntErr" 16550 "IBST_d166_comsclEspIb1Tout" 16549 "IBST_d165_comsclEspIb1DlcErr" 16548 "IBST_d164_comsclEspIb1CsErr" 16547 "IBST_d163_comsclEspIb1CntErr" 16546 "IBST_d162_comsclBrkPrsPduTout" 16545 "IBST_d161_comsclBrkPrsPduLen" 16544 "IBST_d160_assertionFail" 16543 "IBST_d159_rpsSynchEeWriteFail" 16542 "IBST_d158_rpsSynchEeReadEmpty" 16541 "IBST_d157_rpsOffsYEeWriteFail" 16540 "IBST_d156_rpsOffsYEeReadEmpty" 16539 "IBST_d155_rpsOffsXEeWriteFail" 16538 "IBST_d154_rpsOffsXEeReadEmpty" 16537 "IBST_d153_pts2OffsEeWriteFail" 16536 "IBST_d152_pts2OffsEeReadFail" 16535 "IBST_d151_pts2CalEeWriteFail" 16534 "IBST_d150_pts2CalEeReadFail" 16533 "IBST_d149_pts1OffsEeWriteFail" 16532 "IBST_d148_rpsFailCompErr" 16531 "IBST_d147_pts1CalEeWriteFail" 16530 "IBST_d146_pts1CalEeReadFail" 16529 "IBST_d145_ptsCalValuesChkFail" 16528 "IBST_d144_ptsCalHysWritFail" 16527 "IBST_d143_pdmInternalHWErr" 16526 "IBST_d142_pdmHwAcsErr" 16525 "IBST_d141_pdmFieldSizeMis" 16524 "IBST_d140_pdmOutOfMemory" 16523 "IBST_d139_pdmDtFormatMis" 16522 "IBST_d138_pdmCustomerIdMis" 16521 "IBST_d137_motAnglGradTooLarge" 16520 "IBST_d136_motAnglBndWriteErr" 16519 "IBST_d135_motAnglBndReadErr" 16518 "IBST_d134_motPosTrvlWriteFail" 16517 "IBST_d133_motPosTrvlReadFail" 16516 "IBST_d132_esmSafetyFlt" 16515 "IBST_d131_esmNmiFlt" 16514 "IBST_d130_ecuRomCheck" 16513 "IBST_d129_ccmFlt" 16512 "IBST_d128_ecuAdcSelftestErr" 16511 "IBST_d127_ecuAdcConversionErr" 16510 "IBST_d126_ptsEeReadEmpty" 16509 "IBST_d125_motTrvlRelReadEmpty" 16508 "IBST_d124_motTrvlRelWriteFail" 16507 "IBST_d123_rpsAnglRecalcErr" 16506 "IBST_d122_rpsSynchEeReadFail" 16505 "IBST_d121_rpsOffsYEeReadFail" 16504 "IBST_d120_rpsOffsXEeReadFail" 16503 "IBST_d119_pts2OffsEeReadEmpty" 16502 "IBST_d118_pts1OffsEeReadEmpty" 16501 "IBST_d117_pdurEPduInstLost" 16500 "IBST_d116_pdurEInitFail" 16499 "IBST_d115_osErrHook" 16498 "IBST_d114_motShaftShiftDetect" 16497 "IBST_d113_motAngBoundReadEmpt" 16496 "IBST_d112_motPosTrvlReadEmpty" 16495 "IBST_d111_micIntVoltMonFld" 16494 "IBST_d110_micIntMonGenBitMon" 16493 "IBST_d109_micInitSpiTransfErr" 16492 "IBST_d108_micInitSpiTstFld" 16491 "IBST_d107_hetRefError" 16490 "IBST_d106_ecuTaskMissing" 16489 "IBST_d105_ecuHetTuException" 16488 "IBST_d104_ecuHetTuBusyErr" 16487 "IBST_d103_ecuHetTuBusErr" 16486 "IBST_d102_ecuHetTuAddErr" 16485 "IBST_d101_ecuHetException" 16484 "IBST_d100_ecuErrpinCntTstFls" 16483 "IBST_d099_ecuBmsOnWhileWdTout" 16482 "IBST_d098_ecuBandGap" 16481 "IBST_d097_cpuException" 16480 "IBST_d096_canETout" 16479 "IBST_d095_canEHwError" 16478 "IBST_d094_CalDataNotPlaus" 16477 "IBST_d093_bertFlt" 16476 "IBST_d092_ramsinlgeFlt" 16475 "IBST_d091_ramInitErr" 16474 "IBST_d090_pbistErr" 16473 "IBST_d089_ptsOffsTooHigh" 16472 "IBST_d088_faildevInputStroke" 16471 "IBST_d087_pts2LineHigh" 16470 "IBST_d086_pts2LineGnd" 16469 "IBST_d085_pts2Err" 16468 "IBST_d084_inputStroke2Grad" 16467 "IBST_d083_pts1LineHigh" 16466 "IBST_d082_pts1LineGnd" 16465 "IBST_d081_pts1Err" 16464 "IBST_d080_inputstroke1Grad" 16463 "IBST_d079_ecuSupVoltDivDrift" 16462 "IBST_d078_bcsFltCurrentLow" 16461 "IBST_d077_bcsFltCurrentHigh" 16460 "IBST_d076_tle5012VoltFail" 16459 "IBST_d075_hevSwitchOffDcom" 16458 "IBST_d074_tempB6Ch2LineLow" 16457 "IBST_d073_tempB6Ch2LineHigh" 16456 "IBST_d072_tempB6Ch1LineLow" 16455 "IBST_d071_tempB6Ch1LineHigh" 16454 "IBST_d070_cdmExtendedOvrvolt" 16453 "IBST_d069_cdmExtendedUndrvolt" 16452 "IBST_d068_tle5012LifeCnt" 16451 "IBST_d067_sOutRodToPressVal" 16450 "IBST_d066_ibSupVoltDivDrift" 16449 "IBST_d065_inputStroke2RngLow" 16448 "IBST_d064_inputStroke2RngHigh" 16447 "IBST_d063_inputStroke1RngLow" 16446 "IBST_d062_inputStroke1RngHigh" 16445 "IBST_d061_dcomEcuDefect" 16444 "IBST_d060_ltmLimitReached" 16443 "IBST_d059_maxTrvlAdjstUpdFail" 16442 "IBST_d058_cdmHardOvrvolt" 16441 "IBST_d057_cdmHardUndrvolt" 16440 "IBST_d056_ibNotShutDownRight" 16439 "IBST_d055_kl15HwPlausSw" 16438 "IBST_d054_bmsGateUndrvolt" 16437 "IBST_d053_tle5012UnexpReset" 16436 "IBST_d052_motTrvlRelReadFail" 16435 "IBST_d051_cdmUndrvoltLevel1" 16434 "IBST_d050_cdmUndrvoltLevel2" 16433 "IBST_d049_cdmOvrvoltLevel1" 16432 "IBST_d048_unintendMotorReturn" 16431 "IBST_d047_dcomIboosterNotInit" 16430 "IBST_d046_spiAnglOrRawNotUp" 16429 "IBST_d045_B6TempDegradeLevel2" 16428 "IBST_d044_b6TempDegradeLevel1" 16427 "IBST_d043_rpsVctrLengthRelErr" 16426 "IBST_d042_ltmWarnLevelReached" 16425 "IBST_d041_hswInitPhseUndrvolt" 16424 "IBST_d040_bmcGateUndervoltPro" 16423 "IBST_d039_calRoutineAbort" 16422 "IBST_d038_boostSupUndrvolt" 16421 "IBST_d037_calIdlePosNotPlaus" 16420 "IBST_d036_sysErrHook" 16419 "IBST_d035_rpsOffsEeReadFail" 16418 "IBST_d034_motorOscillationDet" 16417 "IBST_d033_oc6Monitor" 16416 "IBST_d032_oc6InitTestFail" 16415 "IBST_d031_ibDtrFail" 16414 "IBST_d030_controllerDevTooBig" 16413 "IBST_d029_bmcShortedGateTest" 16412 "IBST_d028_ecuWdErrCntContErr" 16411 "IBST_d027_tempB6Plaus" 16410 "IBST_d026_ptsSupplyUndvolt" 16409 "IBST_d025_ptsSupply" 16408 "IBST_d024_smmOneReqsInit" 16407 "IBST_d023_stackOvrUndFlow" 16406 "IBST_d022_stmAswSysTout" 16405 "IBST_d021_ubbSupplyLine" 16404 "IBST_d020_voltPreRegModeFld" 16403 "IBST_d019_unsupportedHw" 16402 "IBST_d018_ucSafetyFlt" 16401 "IBST_d017_preDriveChckFail" 16400 "IBST_d016_xpassEchoCountErr" 16399 "IBST_d015_rtpEnaHigh" 16398 "IBST_d014_rpsOffsEeReadEmpty" 16397 "IBST_d013_xpassToutErr" 16396 "IBST_d012_netUndvolt" 16395 "IBST_d011_micSpiTransferErr" 16394 "IBST_d010_micSpiTout" 16393 "IBST_d009_netOvrvolt" 16392 "IBST_d008_ecuWdStatusContErr" 16391 "IBST_d007_ecuWdStarttestFls" 16390 "IBST_d006_ecuWdScheduleTout" 16389 "IBST_d005_ecuWdFltCntTstFls" 16388 "IBST_d004_deadlMonTaskx1Ovr" 16387 "IBST_d003_tle5012Config" 16386 "IBST_d002_tle5012SsccrcFail" 16385 "IBST_d001_bmcSingleTransTest" 16384 "IBST_d000_bmsInitTestFail" ;
VAL_ 861 IBST_d000_bmsInitTestFail 3 "UNABLE_TO_TEST_DTC" 2 "FAILED_DTC" 1 "PASSED_DTC" 0 "NOT_TESTED_DTC" ;
VAL_ 861 IBST_d001_bmcSingleTransTest 3 "UNABLE_TO_TEST_DTC" 2 "FAILED_DTC" 1 "PASSED_DTC" 0 "NOT_TESTED_DTC" ;
VAL_ 861 IBST_d002_tle5012SsccrcFail 3 "UNABLE_TO_TEST_DTC" 2 "FAILED_DTC" 1 "PASSED_DTC" 0 "NOT_TESTED_DTC" ;
VAL_ 861 IBST_d003_tle5012Config 3 "UNABLE_TO_TEST_DTC" 2 "FAILED_DTC" 1 "PASSED_DTC" 0 "NOT_TESTED_DTC" ;
VAL_ 861 IBST_d004_deadlMonTaskx1Ovr 3 "UNABLE_TO_TEST_DTC" 2 "FAILED_DTC" 1 "PASSED_DTC" 0 "NOT_TESTED_DTC" ;
VAL_ 861 IBST_d005_ecuWdFltCntTstFls 3 "UNABLE_TO_TEST_DTC" 2 "FAILED_DTC" 1 "PASSED_DTC" 0 "NOT_TESTED_DTC" ;
VAL_ 861 IBST_d006_ecuWdScheduleTout 3 "UNABLE_TO_TEST_DTC" 2 "FAILED_DTC" 1 "PASSED_DTC" 0 "NOT_TESTED_DTC" ;
VAL_ 861 IBST_d007_ecuWdStarttestFls 3 "UNABLE_TO_TEST_DTC" 2 "FAILED_DTC" 1 "PASSED_DTC" 0 "NOT_TESTED_DTC" ;
VAL_ 861 IBST_d008_ecuWdStatusContErr 3 "UNABLE_TO_TEST_DTC" 2 "FAILED_DTC" 1 "PASSED_DTC" 0 "NOT_TESTED_DTC" ;
VAL_ 861 IBST_d009_netOvrvolt 3 "UNABLE_TO_TEST_DTC" 2 "FAILED_DTC" 1 "PASSED_DTC" 0 "NOT_TESTED_DTC" ;
VAL_ 861 IBST_d010_micSpiTout 3 "UNABLE_TO_TEST_DTC" 2 "FAILED_DTC" 1 "PASSED_DTC" 0 "NOT_TESTED_DTC" ;
VAL_ 861 IBST_d011_micSpiTransferErr 3 "UNABLE_TO_TEST_DTC" 2 "FAILED_DTC" 1 "PASSED_DTC" 0 "NOT_TESTED_DTC" ;
VAL_ 861 IBST_d012_netUndvolt 3 "UNABLE_TO_TEST_DTC" 2 "FAILED_DTC" 1 "PASSED_DTC" 0 "NOT_TESTED_DTC" ;
VAL_ 861 IBST_d013_xpassToutErr 3 "UNABLE_TO_TEST_DTC" 2 "FAILED_DTC" 1 "PASSED_DTC" 0 "NOT_TESTED_DTC" ;
VAL_ 861 IBST_d014_rpsOffsEeReadEmpty 3 "UNABLE_TO_TEST_DTC" 2 "FAILED_DTC" 1 "PASSED_DTC" 0 "NOT_TESTED_DTC" ;
VAL_ 861 IBST_d015_rtpEnaHigh 3 "UNABLE_TO_TEST_DTC" 2 "FAILED_DTC" 1 "PASSED_DTC" 0 "NOT_TESTED_DTC" ;
VAL_ 861 IBST_d016_xpassEchoCountErr 3 "UNABLE_TO_TEST_DTC" 2 "FAILED_DTC" 1 "PASSED_DTC" 0 "NOT_TESTED_DTC" ;
VAL_ 861 IBST_d017_preDriveChckFail 3 "UNABLE_TO_TEST_DTC" 2 "FAILED_DTC" 1 "PASSED_DTC" 0 "NOT_TESTED_DTC" ;
VAL_ 861 IBST_d018_ucSafetyFlt 3 "UNABLE_TO_TEST_DTC" 2 "FAILED_DTC" 1 "PASSED_DTC" 0 "NOT_TESTED_DTC" ;
VAL_ 861 IBST_d019_unsupportedHw 3 "UNABLE_TO_TEST_DTC" 2 "FAILED_DTC" 1 "PASSED_DTC" 0 "NOT_TESTED_DTC" ;
VAL_ 861 IBST_d020_voltPreRegModeFld 3 "UNABLE_TO_TEST_DTC" 2 "FAILED_DTC" 1 "PASSED_DTC" 0 "NOT_TESTED_DTC" ;
VAL_ 861 IBST_d021_ubbSupplyLine 3 "UNABLE_TO_TEST_DTC" 2 "FAILED_DTC" 1 "PASSED_DTC" 0 "NOT_TESTED_DTC" ;
VAL_ 861 IBST_d022_stmAswSysTout 3 "UNABLE_TO_TEST_DTC" 2 "FAILED_DTC" 1 "PASSED_DTC" 0 "NOT_TESTED_DTC" ;
VAL_ 861 IBST_d023_stackOvrUndFlow 3 "UNABLE_TO_TEST_DTC" 2 "FAILED_DTC" 1 "PASSED_DTC" 0 "NOT_TESTED_DTC" ;
VAL_ 861 IBST_d024_smmOneReqsInit 3 "UNABLE_TO_TEST_DTC" 2 "FAILED_DTC" 1 "PASSED_DTC" 0 "NOT_TESTED_DTC" ;
VAL_ 861 IBST_d025_ptsSupply 3 "UNABLE_TO_TEST_DTC" 2 "FAILED_DTC" 1 "PASSED_DTC" 0 "NOT_TESTED_DTC" ;
VAL_ 861 IBST_d026_ptsSupplyUndvolt 3 "UNABLE_TO_TEST_DTC" 2 "FAILED_DTC" 1 "PASSED_DTC" 0 "NOT_TESTED_DTC" ;
VAL_ 861 IBST_d027_tempB6Plaus 3 "UNABLE_TO_TEST_DTC" 2 "FAILED_DTC" 1 "PASSED_DTC" 0 "NOT_TESTED_DTC" ;
VAL_ 861 IBST_d028_ecuWdErrCntContErr 3 "UNABLE_TO_TEST_DTC" 2 "FAILED_DTC" 1 "PASSED_DTC" 0 "NOT_TESTED_DTC" ;
VAL_ 861 IBST_d029_bmcShortedGateTest 3 "UNABLE_TO_TEST_DTC" 2 "FAILED_DTC" 1 "PASSED_DTC" 0 "NOT_TESTED_DTC" ;
VAL_ 861 IBST_d030_controllerDevTooBig 3 "UNABLE_TO_TEST_DTC" 2 "FAILED_DTC" 1 "PASSED_DTC" 0 "NOT_TESTED_DTC" ;
VAL_ 861 IBST_d031_ibDtrFail 3 "UNABLE_TO_TEST_DTC" 2 "FAILED_DTC" 1 "PASSED_DTC" 0 "NOT_TESTED_DTC" ;
VAL_ 861 IBST_d032_oc6InitTestFail 3 "UNABLE_TO_TEST_DTC" 2 "FAILED_DTC" 1 "PASSED_DTC" 0 "NOT_TESTED_DTC" ;
VAL_ 861 IBST_d033_oc6Monitor 3 "UNABLE_TO_TEST_DTC" 2 "FAILED_DTC" 1 "PASSED_DTC" 0 "NOT_TESTED_DTC" ;
VAL_ 861 IBST_d034_motorOscillationDet 3 "UNABLE_TO_TEST_DTC" 2 "FAILED_DTC" 1 "PASSED_DTC" 0 "NOT_TESTED_DTC" ;
VAL_ 861 IBST_d035_rpsOffsEeReadFail 3 "UNABLE_TO_TEST_DTC" 2 "FAILED_DTC" 1 "PASSED_DTC" 0 "NOT_TESTED_DTC" ;
VAL_ 861 IBST_d036_sysErrHook 3 "UNABLE_TO_TEST_DTC" 2 "FAILED_DTC" 1 "PASSED_DTC" 0 "NOT_TESTED_DTC" ;
VAL_ 861 IBST_d037_calIdlePosNotPlaus 3 "UNABLE_TO_TEST_DTC" 2 "FAILED_DTC" 1 "PASSED_DTC" 0 "NOT_TESTED_DTC" ;
VAL_ 861 IBST_d038_boostSupUndrvolt 3 "UNABLE_TO_TEST_DTC" 2 "FAILED_DTC" 1 "PASSED_DTC" 0 "NOT_TESTED_DTC" ;
VAL_ 861 IBST_d039_calRoutineAbort 3 "UNABLE_TO_TEST_DTC" 2 "FAILED_DTC" 1 "PASSED_DTC" 0 "NOT_TESTED_DTC" ;
VAL_ 861 IBST_d040_bmcGateUndervoltPro 3 "UNABLE_TO_TEST_DTC" 2 "FAILED_DTC" 1 "PASSED_DTC" 0 "NOT_TESTED_DTC" ;
VAL_ 861 IBST_d041_hswInitPhseUndrvolt 3 "UNABLE_TO_TEST_DTC" 2 "FAILED_DTC" 1 "PASSED_DTC" 0 "NOT_TESTED_DTC" ;
VAL_ 861 IBST_d042_ltmWarnLevelReached 3 "UNABLE_TO_TEST_DTC" 2 "FAILED_DTC" 1 "PASSED_DTC" 0 "NOT_TESTED_DTC" ;
VAL_ 861 IBST_d043_rpsVctrLengthRelErr 3 "UNABLE_TO_TEST_DTC" 2 "FAILED_DTC" 1 "PASSED_DTC" 0 "NOT_TESTED_DTC" ;
VAL_ 861 IBST_d044_b6TempDegradeLevel1 3 "UNABLE_TO_TEST_DTC" 2 "FAILED_DTC" 1 "PASSED_DTC" 0 "NOT_TESTED_DTC" ;
VAL_ 861 IBST_d045_B6TempDegradeLevel2 3 "UNABLE_TO_TEST_DTC" 2 "FAILED_DTC" 1 "PASSED_DTC" 0 "NOT_TESTED_DTC" ;
VAL_ 861 IBST_d046_spiAnglOrRawNotUp 3 "UNABLE_TO_TEST_DTC" 2 "FAILED_DTC" 1 "PASSED_DTC" 0 "NOT_TESTED_DTC" ;
VAL_ 861 IBST_d047_dcomIboosterNotInit 3 "UNABLE_TO_TEST_DTC" 2 "FAILED_DTC" 1 "PASSED_DTC" 0 "NOT_TESTED_DTC" ;
VAL_ 861 IBST_d048_unintendMotorReturn 3 "UNABLE_TO_TEST_DTC" 2 "FAILED_DTC" 1 "PASSED_DTC" 0 "NOT_TESTED_DTC" ;
VAL_ 861 IBST_d049_cdmOvrvoltLevel1 3 "UNABLE_TO_TEST_DTC" 2 "FAILED_DTC" 1 "PASSED_DTC" 0 "NOT_TESTED_DTC" ;
VAL_ 861 IBST_d050_cdmUndrvoltLevel2 3 "UNABLE_TO_TEST_DTC" 2 "FAILED_DTC" 1 "PASSED_DTC" 0 "NOT_TESTED_DTC" ;
VAL_ 861 IBST_d051_cdmUndrvoltLevel1 3 "UNABLE_TO_TEST_DTC" 2 "FAILED_DTC" 1 "PASSED_DTC" 0 "NOT_TESTED_DTC" ;
VAL_ 861 IBST_d052_motTrvlRelReadFail 3 "UNABLE_TO_TEST_DTC" 2 "FAILED_DTC" 1 "PASSED_DTC" 0 "NOT_TESTED_DTC" ;
VAL_ 861 IBST_d053_tle5012UnexpReset 3 "UNABLE_TO_TEST_DTC" 2 "FAILED_DTC" 1 "PASSED_DTC" 0 "NOT_TESTED_DTC" ;
VAL_ 861 IBST_d054_bmsGateUndrvolt 3 "UNABLE_TO_TEST_DTC" 2 "FAILED_DTC" 1 "PASSED_DTC" 0 "NOT_TESTED_DTC" ;
VAL_ 861 IBST_d055_kl15HwPlausSw 3 "UNABLE_TO_TEST_DTC" 2 "FAILED_DTC" 1 "PASSED_DTC" 0 "NOT_TESTED_DTC" ;
VAL_ 861 IBST_d056_ibNotShutDownRight 3 "UNABLE_TO_TEST_DTC" 2 "FAILED_DTC" 1 "PASSED_DTC" 0 "NOT_TESTED_DTC" ;
VAL_ 861 IBST_d057_cdmHardUndrvolt 3 "UNABLE_TO_TEST_DTC" 2 "FAILED_DTC" 1 "PASSED_DTC" 0 "NOT_TESTED_DTC" ;
VAL_ 861 IBST_d058_cdmHardOvrvolt 3 "UNABLE_TO_TEST_DTC" 2 "FAILED_DTC" 1 "PASSED_DTC" 0 "NOT_TESTED_DTC" ;
VAL_ 861 IBST_d059_maxTrvlAdjstUpdFail 3 "UNABLE_TO_TEST_DTC" 2 "FAILED_DTC" 1 "PASSED_DTC" 0 "NOT_TESTED_DTC" ;
VAL_ 861 IBST_d060_ltmLimitReached 3 "UNABLE_TO_TEST_DTC" 2 "FAILED_DTC" 1 "PASSED_DTC" 0 "NOT_TESTED_DTC" ;
VAL_ 861 IBST_d061_dcomEcuDefect 3 "UNABLE_TO_TEST_DTC" 2 "FAILED_DTC" 1 "PASSED_DTC" 0 "NOT_TESTED_DTC" ;
VAL_ 861 IBST_d062_inputStroke1RngHigh 3 "UNABLE_TO_TEST_DTC" 2 "FAILED_DTC" 1 "PASSED_DTC" 0 "NOT_TESTED_DTC" ;
VAL_ 861 IBST_d063_inputStroke1RngLow 3 "UNABLE_TO_TEST_DTC" 2 "FAILED_DTC" 1 "PASSED_DTC" 0 "NOT_TESTED_DTC" ;
VAL_ 861 IBST_d064_inputStroke2RngHigh 3 "UNABLE_TO_TEST_DTC" 2 "FAILED_DTC" 1 "PASSED_DTC" 0 "NOT_TESTED_DTC" ;
VAL_ 861 IBST_d065_inputStroke2RngLow 3 "UNABLE_TO_TEST_DTC" 2 "FAILED_DTC" 1 "PASSED_DTC" 0 "NOT_TESTED_DTC" ;
VAL_ 861 IBST_d066_ibSupVoltDivDrift 3 "UNABLE_TO_TEST_DTC" 2 "FAILED_DTC" 1 "PASSED_DTC" 0 "NOT_TESTED_DTC" ;
VAL_ 861 IBST_d067_sOutRodToPressVal 3 "UNABLE_TO_TEST_DTC" 2 "FAILED_DTC" 1 "PASSED_DTC" 0 "NOT_TESTED_DTC" ;
VAL_ 861 IBST_d068_tle5012LifeCnt 3 "UNABLE_TO_TEST_DTC" 2 "FAILED_DTC" 1 "PASSED_DTC" 0 "NOT_TESTED_DTC" ;
VAL_ 861 IBST_d069_cdmExtendedUndrvolt 3 "UNABLE_TO_TEST_DTC" 2 "FAILED_DTC" 1 "PASSED_DTC" 0 "NOT_TESTED_DTC" ;
VAL_ 861 IBST_d070_cdmExtendedOvrvolt 3 "UNABLE_TO_TEST_DTC" 2 "FAILED_DTC" 1 "PASSED_DTC" 0 "NOT_TESTED_DTC" ;
VAL_ 861 IBST_d071_tempB6Ch1LineHigh 3 "UNABLE_TO_TEST_DTC" 2 "FAILED_DTC" 1 "PASSED_DTC" 0 "NOT_TESTED_DTC" ;
VAL_ 861 IBST_d072_tempB6Ch1LineLow 3 "UNABLE_TO_TEST_DTC" 2 "FAILED_DTC" 1 "PASSED_DTC" 0 "NOT_TESTED_DTC" ;
VAL_ 861 IBST_d073_tempB6Ch2LineHigh 3 "UNABLE_TO_TEST_DTC" 2 "FAILED_DTC" 1 "PASSED_DTC" 0 "NOT_TESTED_DTC" ;
VAL_ 861 IBST_d074_tempB6Ch2LineLow 3 "UNABLE_TO_TEST_DTC" 2 "FAILED_DTC" 1 "PASSED_DTC" 0 "NOT_TESTED_DTC" ;
VAL_ 861 IBST_d075_hevSwitchOffDcom 3 "UNABLE_TO_TEST_DTC" 2 "FAILED_DTC" 1 "PASSED_DTC" 0 "NOT_TESTED_DTC" ;
VAL_ 861 IBST_d076_tle5012VoltFail 3 "UNABLE_TO_TEST_DTC" 2 "FAILED_DTC" 1 "PASSED_DTC" 0 "NOT_TESTED_DTC" ;
VAL_ 861 IBST_d077_bcsFltCurrentHigh 3 "UNABLE_TO_TEST_DTC" 2 "FAILED_DTC" 1 "PASSED_DTC" 0 "NOT_TESTED_DTC" ;
VAL_ 861 IBST_d078_bcsFltCurrentLow 3 "UNABLE_TO_TEST_DTC" 2 "FAILED_DTC" 1 "PASSED_DTC" 0 "NOT_TESTED_DTC" ;
VAL_ 861 IBST_d079_ecuSupVoltDivDrift 3 "UNABLE_TO_TEST_DTC" 2 "FAILED_DTC" 1 "PASSED_DTC" 0 "NOT_TESTED_DTC" ;
VAL_ 861 IBST_d080_inputstroke1Grad 3 "UNABLE_TO_TEST_DTC" 2 "FAILED_DTC" 1 "PASSED_DTC" 0 "NOT_TESTED_DTC" ;
VAL_ 861 IBST_d081_pts1Err 3 "UNABLE_TO_TEST_DTC" 2 "FAILED_DTC" 1 "PASSED_DTC" 0 "NOT_TESTED_DTC" ;
VAL_ 861 IBST_d082_pts1LineGnd 3 "UNABLE_TO_TEST_DTC" 2 "FAILED_DTC" 1 "PASSED_DTC" 0 "NOT_TESTED_DTC" ;
VAL_ 861 IBST_d083_pts1LineHigh 3 "UNABLE_TO_TEST_DTC" 2 "FAILED_DTC" 1 "PASSED_DTC" 0 "NOT_TESTED_DTC" ;
VAL_ 861 IBST_d084_inputStroke2Grad 3 "UNABLE_TO_TEST_DTC" 2 "FAILED_DTC" 1 "PASSED_DTC" 0 "NOT_TESTED_DTC" ;
VAL_ 861 IBST_d085_pts2Err 3 "UNABLE_TO_TEST_DTC" 2 "FAILED_DTC" 1 "PASSED_DTC" 0 "NOT_TESTED_DTC" ;
VAL_ 861 IBST_d086_pts2LineGnd 3 "UNABLE_TO_TEST_DTC" 2 "FAILED_DTC" 1 "PASSED_DTC" 0 "NOT_TESTED_DTC" ;
VAL_ 861 IBST_d087_pts2LineHigh 3 "UNABLE_TO_TEST_DTC" 2 "FAILED_DTC" 1 "PASSED_DTC" 0 "NOT_TESTED_DTC" ;
VAL_ 861 IBST_d088_faildevInputStroke 3 "UNABLE_TO_TEST_DTC" 2 "FAILED_DTC" 1 "PASSED_DTC" 0 "NOT_TESTED_DTC" ;
VAL_ 861 IBST_d089_ptsOffsTooHigh 3 "UNABLE_TO_TEST_DTC" 2 "FAILED_DTC" 1 "PASSED_DTC" 0 "NOT_TESTED_DTC" ;
VAL_ 861 IBST_d090_pbistErr 3 "UNABLE_TO_TEST_DTC" 2 "FAILED_DTC" 1 "PASSED_DTC" 0 "NOT_TESTED_DTC" ;
VAL_ 861 IBST_d091_ramInitErr 3 "UNABLE_TO_TEST_DTC" 2 "FAILED_DTC" 1 "PASSED_DTC" 0 "NOT_TESTED_DTC" ;
VAL_ 861 IBST_d092_ramsinlgeFlt 3 "UNABLE_TO_TEST_DTC" 2 "FAILED_DTC" 1 "PASSED_DTC" 0 "NOT_TESTED_DTC" ;
VAL_ 861 IBST_d093_bertFlt 3 "UNABLE_TO_TEST_DTC" 2 "FAILED_DTC" 1 "PASSED_DTC" 0 "NOT_TESTED_DTC" ;
VAL_ 861 IBST_d094_CalDataNotPlaus 3 "UNABLE_TO_TEST_DTC" 2 "FAILED_DTC" 1 "PASSED_DTC" 0 "NOT_TESTED_DTC" ;
VAL_ 861 IBST_d095_canEHwError 3 "UNABLE_TO_TEST_DTC" 2 "FAILED_DTC" 1 "PASSED_DTC" 0 "NOT_TESTED_DTC" ;
VAL_ 861 IBST_d096_canETout 3 "UNABLE_TO_TEST_DTC" 2 "FAILED_DTC" 1 "PASSED_DTC" 0 "NOT_TESTED_DTC" ;
VAL_ 861 IBST_d097_cpuException 3 "UNABLE_TO_TEST_DTC" 2 "FAILED_DTC" 1 "PASSED_DTC" 0 "NOT_TESTED_DTC" ;
VAL_ 861 IBST_d098_ecuBandGap 3 "UNABLE_TO_TEST_DTC" 2 "FAILED_DTC" 1 "PASSED_DTC" 0 "NOT_TESTED_DTC" ;
VAL_ 861 IBST_d099_ecuBmsOnWhileWdTout 3 "UNABLE_TO_TEST_DTC" 2 "FAILED_DTC" 1 "PASSED_DTC" 0 "NOT_TESTED_DTC" ;
VAL_ 861 IBST_d100_ecuErrpinCntTstFls 3 "UNABLE_TO_TEST_DTC" 2 "FAILED_DTC" 1 "PASSED_DTC" 0 "NOT_TESTED_DTC" ;
VAL_ 861 IBST_d101_ecuHetException 3 "UNABLE_TO_TEST_DTC" 2 "FAILED_DTC" 1 "PASSED_DTC" 0 "NOT_TESTED_DTC" ;
VAL_ 861 IBST_d102_ecuHetTuAddErr 3 "UNABLE_TO_TEST_DTC" 2 "FAILED_DTC" 1 "PASSED_DTC" 0 "NOT_TESTED_DTC" ;
VAL_ 861 IBST_d103_ecuHetTuBusErr 3 "UNABLE_TO_TEST_DTC" 2 "FAILED_DTC" 1 "PASSED_DTC" 0 "NOT_TESTED_DTC" ;
VAL_ 861 IBST_d104_ecuHetTuBusyErr 3 "UNABLE_TO_TEST_DTC" 2 "FAILED_DTC" 1 "PASSED_DTC" 0 "NOT_TESTED_DTC" ;
VAL_ 861 IBST_d105_ecuHetTuException 3 "UNABLE_TO_TEST_DTC" 2 "FAILED_DTC" 1 "PASSED_DTC" 0 "NOT_TESTED_DTC" ;
VAL_ 861 IBST_d106_ecuTaskMissing 3 "UNABLE_TO_TEST_DTC" 2 "FAILED_DTC" 1 "PASSED_DTC" 0 "NOT_TESTED_DTC" ;
VAL_ 861 IBST_d107_hetRefError 3 "UNABLE_TO_TEST_DTC" 2 "FAILED_DTC" 1 "PASSED_DTC" 0 "NOT_TESTED_DTC" ;
VAL_ 861 IBST_d108_micInitSpiTstFld 3 "UNABLE_TO_TEST_DTC" 2 "FAILED_DTC" 1 "PASSED_DTC" 0 "NOT_TESTED_DTC" ;
VAL_ 861 IBST_d109_micInitSpiTransfErr 3 "UNABLE_TO_TEST_DTC" 2 "FAILED_DTC" 1 "PASSED_DTC" 0 "NOT_TESTED_DTC" ;
VAL_ 861 IBST_d110_micIntMonGenBitMon 3 "UNABLE_TO_TEST_DTC" 2 "FAILED_DTC" 1 "PASSED_DTC" 0 "NOT_TESTED_DTC" ;
VAL_ 861 IBST_d111_micIntVoltMonFld 3 "UNABLE_TO_TEST_DTC" 2 "FAILED_DTC" 1 "PASSED_DTC" 0 "NOT_TESTED_DTC" ;
VAL_ 861 IBST_d112_motPosTrvlReadEmpty 3 "UNABLE_TO_TEST_DTC" 2 "FAILED_DTC" 1 "PASSED_DTC" 0 "NOT_TESTED_DTC" ;
VAL_ 861 IBST_d113_motAngBoundReadEmpt 3 "UNABLE_TO_TEST_DTC" 2 "FAILED_DTC" 1 "PASSED_DTC" 0 "NOT_TESTED_DTC" ;
VAL_ 861 IBST_d114_motShaftShiftDetect 3 "UNABLE_TO_TEST_DTC" 2 "FAILED_DTC" 1 "PASSED_DTC" 0 "NOT_TESTED_DTC" ;
VAL_ 861 IBST_d115_osErrHook 3 "UNABLE_TO_TEST_DTC" 2 "FAILED_DTC" 1 "PASSED_DTC" 0 "NOT_TESTED_DTC" ;
VAL_ 861 IBST_d116_pdurEInitFail 3 "UNABLE_TO_TEST_DTC" 2 "FAILED_DTC" 1 "PASSED_DTC" 0 "NOT_TESTED_DTC" ;
VAL_ 861 IBST_d117_pdurEPduInstLost 3 "UNABLE_TO_TEST_DTC" 2 "FAILED_DTC" 1 "PASSED_DTC" 0 "NOT_TESTED_DTC" ;
VAL_ 861 IBST_d118_pts1OffsEeReadEmpty 3 "UNABLE_TO_TEST_DTC" 2 "FAILED_DTC" 1 "PASSED_DTC" 0 "NOT_TESTED_DTC" ;
VAL_ 861 IBST_d119_pts2OffsEeReadEmpty 3 "UNABLE_TO_TEST_DTC" 2 "FAILED_DTC" 1 "PASSED_DTC" 0 "NOT_TESTED_DTC" ;
VAL_ 861 IBST_d120_rpsOffsXEeReadFail 3 "UNABLE_TO_TEST_DTC" 2 "FAILED_DTC" 1 "PASSED_DTC" 0 "NOT_TESTED_DTC" ;
VAL_ 861 IBST_d121_rpsOffsYEeReadFail 3 "UNABLE_TO_TEST_DTC" 2 "FAILED_DTC" 1 "PASSED_DTC" 0 "NOT_TESTED_DTC" ;
VAL_ 861 IBST_d122_rpsSynchEeReadFail 3 "UNABLE_TO_TEST_DTC" 2 "FAILED_DTC" 1 "PASSED_DTC" 0 "NOT_TESTED_DTC" ;
VAL_ 861 IBST_d123_rpsAnglRecalcErr 3 "UNABLE_TO_TEST_DTC" 2 "FAILED_DTC" 1 "PASSED_DTC" 0 "NOT_TESTED_DTC" ;
VAL_ 861 IBST_d124_motTrvlRelWriteFail 3 "UNABLE_TO_TEST_DTC" 2 "FAILED_DTC" 1 "PASSED_DTC" 0 "NOT_TESTED_DTC" ;
VAL_ 861 IBST_d125_motTrvlRelReadEmpty 3 "UNABLE_TO_TEST_DTC" 2 "FAILED_DTC" 1 "PASSED_DTC" 0 "NOT_TESTED_DTC" ;
VAL_ 861 IBST_d126_ptsEeReadEmpty 3 "UNABLE_TO_TEST_DTC" 2 "FAILED_DTC" 1 "PASSED_DTC" 0 "NOT_TESTED_DTC" ;
VAL_ 861 IBST_d127_ecuAdcConversionErr 3 "UNABLE_TO_TEST_DTC" 2 "FAILED_DTC" 1 "PASSED_DTC" 0 "NOT_TESTED_DTC" ;
VAL_ 861 IBST_d128_ecuAdcSelftestErr 3 "UNABLE_TO_TEST_DTC" 2 "FAILED_DTC" 1 "PASSED_DTC" 0 "NOT_TESTED_DTC" ;
VAL_ 861 IBST_d129_ccmFlt 3 "UNABLE_TO_TEST_DTC" 2 "FAILED_DTC" 1 "PASSED_DTC" 0 "NOT_TESTED_DTC" ;
VAL_ 861 IBST_d130_ecuRomCheck 3 "UNABLE_TO_TEST_DTC" 2 "FAILED_DTC" 1 "PASSED_DTC" 0 "NOT_TESTED_DTC" ;
VAL_ 861 IBST_d131_esmNmiFlt 3 "UNABLE_TO_TEST_DTC" 2 "FAILED_DTC" 1 "PASSED_DTC" 0 "NOT_TESTED_DTC" ;
VAL_ 861 IBST_d132_esmSafetyFlt 3 "UNABLE_TO_TEST_DTC" 2 "FAILED_DTC" 1 "PASSED_DTC" 0 "NOT_TESTED_DTC" ;
VAL_ 861 IBST_d133_motPosTrvlReadFail 3 "UNABLE_TO_TEST_DTC" 2 "FAILED_DTC" 1 "PASSED_DTC" 0 "NOT_TESTED_DTC" ;
VAL_ 861 IBST_d134_motPosTrvlWriteFail 3 "UNABLE_TO_TEST_DTC" 2 "FAILED_DTC" 1 "PASSED_DTC" 0 "NOT_TESTED_DTC" ;
VAL_ 861 IBST_d135_motAnglBndReadErr 3 "UNABLE_TO_TEST_DTC" 2 "FAILED_DTC" 1 "PASSED_DTC" 0 "NOT_TESTED_DTC" ;
VAL_ 861 IBST_d136_motAnglBndWriteErr 3 "UNABLE_TO_TEST_DTC" 2 "FAILED_DTC" 1 "PASSED_DTC" 0 "NOT_TESTED_DTC" ;
VAL_ 861 IBST_d137_motAnglGradTooLarge 3 "UNABLE_TO_TEST_DTC" 2 "FAILED_DTC" 1 "PASSED_DTC" 0 "NOT_TESTED_DTC" ;
VAL_ 861 IBST_d138_pdmCustomerIdMis 3 "UNABLE_TO_TEST_DTC" 2 "FAILED_DTC" 1 "PASSED_DTC" 0 "NOT_TESTED_DTC" ;
VAL_ 861 IBST_d139_pdmDtFormatMis 3 "UNABLE_TO_TEST_DTC" 2 "FAILED_DTC" 1 "PASSED_DTC" 0 "NOT_TESTED_DTC" ;
VAL_ 861 IBST_d140_pdmOutOfMemory 3 "UNABLE_TO_TEST_DTC" 2 "FAILED_DTC" 1 "PASSED_DTC" 0 "NOT_TESTED_DTC" ;
VAL_ 861 IBST_d141_pdmFieldSizeMis 3 "UNABLE_TO_TEST_DTC" 2 "FAILED_DTC" 1 "PASSED_DTC" 0 "NOT_TESTED_DTC" ;
VAL_ 861 IBST_d142_pdmHwAcsErr 3 "UNABLE_TO_TEST_DTC" 2 "FAILED_DTC" 1 "PASSED_DTC" 0 "NOT_TESTED_DTC" ;
VAL_ 861 IBST_d143_pdmInternalHWErr 3 "UNABLE_TO_TEST_DTC" 2 "FAILED_DTC" 1 "PASSED_DTC" 0 "NOT_TESTED_DTC" ;
VAL_ 861 IBST_d144_ptsCalHysWritFail 3 "UNABLE_TO_TEST_DTC" 2 "FAILED_DTC" 1 "PASSED_DTC" 0 "NOT_TESTED_DTC" ;
VAL_ 861 IBST_d145_ptsCalValuesChkFail 3 "UNABLE_TO_TEST_DTC" 2 "FAILED_DTC" 1 "PASSED_DTC" 0 "NOT_TESTED_DTC" ;
VAL_ 861 IBST_d146_pts1CalEeReadFail 3 "UNABLE_TO_TEST_DTC" 2 "FAILED_DTC" 1 "PASSED_DTC" 0 "NOT_TESTED_DTC" ;
VAL_ 861 IBST_d147_pts1CalEeWriteFail 3 "UNABLE_TO_TEST_DTC" 2 "FAILED_DTC" 1 "PASSED_DTC" 0 "NOT_TESTED_DTC" ;
VAL_ 861 IBST_d148_rpsFailCompErr 3 "UNABLE_TO_TEST_DTC" 2 "FAILED_DTC" 1 "PASSED_DTC" 0 "NOT_TESTED_DTC" ;
VAL_ 861 IBST_d149_pts1OffsEeWriteFail 3 "UNABLE_TO_TEST_DTC" 2 "FAILED_DTC" 1 "PASSED_DTC" 0 "NOT_TESTED_DTC" ;
VAL_ 861 IBST_d150_pts2CalEeReadFail 3 "UNABLE_TO_TEST_DTC" 2 "FAILED_DTC" 1 "PASSED_DTC" 0 "NOT_TESTED_DTC" ;
VAL_ 861 IBST_d151_pts2CalEeWriteFail 3 "UNABLE_TO_TEST_DTC" 2 "FAILED_DTC" 1 "PASSED_DTC" 0 "NOT_TESTED_DTC" ;
VAL_ 861 IBST_d152_pts2OffsEeReadFail 3 "UNABLE_TO_TEST_DTC" 2 "FAILED_DTC" 1 "PASSED_DTC" 0 "NOT_TESTED_DTC" ;
VAL_ 861 IBST_d153_pts2OffsEeWriteFail 3 "UNABLE_TO_TEST_DTC" 2 "FAILED_DTC" 1 "PASSED_DTC" 0 "NOT_TESTED_DTC" ;
VAL_ 861 IBST_d154_rpsOffsXEeReadEmpty 3 "UNABLE_TO_TEST_DTC" 2 "FAILED_DTC" 1 "PASSED_DTC" 0 "NOT_TESTED_DTC" ;
VAL_ 861 IBST_d155_rpsOffsXEeWriteFail 3 "UNABLE_TO_TEST_DTC" 2 "FAILED_DTC" 1 "PASSED_DTC" 0 "NOT_TESTED_DTC" ;
VAL_ 861 IBST_d156_rpsOffsYEeReadEmpty 3 "UNABLE_TO_TEST_DTC" 2 "FAILED_DTC" 1 "PASSED_DTC" 0 "NOT_TESTED_DTC" ;
VAL_ 861 IBST_d157_rpsOffsYEeWriteFail 3 "UNABLE_TO_TEST_DTC" 2 "FAILED_DTC" 1 "PASSED_DTC" 0 "NOT_TESTED_DTC" ;
VAL_ 861 IBST_d158_rpsSynchEeReadEmpty 3 "UNABLE_TO_TEST_DTC" 2 "FAILED_DTC" 1 "PASSED_DTC" 0 "NOT_TESTED_DTC" ;
VAL_ 861 IBST_d159_rpsSynchEeWriteFail 3 "UNABLE_TO_TEST_DTC" 2 "FAILED_DTC" 1 "PASSED_DTC" 0 "NOT_TESTED_DTC" ;
VAL_ 861 IBST_d160_assertionFail 3 "UNABLE_TO_TEST_DTC" 2 "FAILED_DTC" 1 "PASSED_DTC" 0 "NOT_TESTED_DTC" ;
VAL_ 861 IBST_d161_comsclBrkPrsPduLen 3 "UNABLE_TO_TEST_DTC" 2 "FAILED_DTC" 1 "PASSED_DTC" 0 "NOT_TESTED_DTC" ;
VAL_ 861 IBST_d162_comsclBrkPrsPduTout 3 "UNABLE_TO_TEST_DTC" 2 "FAILED_DTC" 1 "PASSED_DTC" 0 "NOT_TESTED_DTC" ;
VAL_ 861 IBST_d163_comsclEspIb1CntErr 3 "UNABLE_TO_TEST_DTC" 2 "FAILED_DTC" 1 "PASSED_DTC" 0 "NOT_TESTED_DTC" ;
VAL_ 861 IBST_d164_comsclEspIb1CsErr 3 "UNABLE_TO_TEST_DTC" 2 "FAILED_DTC" 1 "PASSED_DTC" 0 "NOT_TESTED_DTC" ;
VAL_ 861 IBST_d165_comsclEspIb1DlcErr 3 "UNABLE_TO_TEST_DTC" 2 "FAILED_DTC" 1 "PASSED_DTC" 0 "NOT_TESTED_DTC" ;
VAL_ 861 IBST_d166_comsclEspIb1Tout 3 "UNABLE_TO_TEST_DTC" 2 "FAILED_DTC" 1 "PASSED_DTC" 0 "NOT_TESTED_DTC" ;
VAL_ 861 IBST_d167_comsclEspIb2CntErr 3 "UNABLE_TO_TEST_DTC" 2 "FAILED_DTC" 1 "PASSED_DTC" 0 "NOT_TESTED_DTC" ;
VAL_ 861 IBST_d168_comsclEspIb2CsErr 3 "UNABLE_TO_TEST_DTC" 2 "FAILED_DTC" 1 "PASSED_DTC" 0 "NOT_TESTED_DTC" ;
VAL_ 861 IBST_d169_comsclEspIb2DlcErr 3 "UNABLE_TO_TEST_DTC" 2 "FAILED_DTC" 1 "PASSED_DTC" 0 "NOT_TESTED_DTC" ;
VAL_ 861 IBST_d170_comsclEspIb2Tout 3 "UNABLE_TO_TEST_DTC" 2 "FAILED_DTC" 1 "PASSED_DTC" 0 "NOT_TESTED_DTC" ;
VAL_ 861 IBST_d171_comsclEspIb3CntErr 3 "UNABLE_TO_TEST_DTC" 2 "FAILED_DTC" 1 "PASSED_DTC" 0 "NOT_TESTED_DTC" ;
VAL_ 861 IBST_d172_comsclEspIb3CsErr 3 "UNABLE_TO_TEST_DTC" 2 "FAILED_DTC" 1 "PASSED_DTC" 0 "NOT_TESTED_DTC" ;
VAL_ 861 IBST_d173_comsclEspIb3DlcErr 3 "UNABLE_TO_TEST_DTC" 2 "FAILED_DTC" 1 "PASSED_DTC" 0 "NOT_TESTED_DTC" ;
VAL_ 861 IBST_d174_comsclEspIb3Tout 3 "UNABLE_TO_TEST_DTC" 2 "FAILED_DTC" 1 "PASSED_DTC" 0 "NOT_TESTED_DTC" ;
VAL_ 861 IBST_d175_comsclGtwEsp1CntErr 3 "UNABLE_TO_TEST_DTC" 2 "FAILED_DTC" 1 "PASSED_DTC" 0 "NOT_TESTED_DTC" ;
VAL_ 861 IBST_d176_comsclGtwEsp1CsErr 3 "UNABLE_TO_TEST_DTC" 2 "FAILED_DTC" 1 "PASSED_DTC" 0 "NOT_TESTED_DTC" ;
VAL_ 861 IBST_d177_comsclGtwEsp1Corrpt 3 "UNABLE_TO_TEST_DTC" 2 "FAILED_DTC" 1 "PASSED_DTC" 0 "NOT_TESTED_DTC" ;
VAL_ 861 IBST_d178_comsclGtwEsp1Tout 3 "UNABLE_TO_TEST_DTC" 2 "FAILED_DTC" 1 "PASSED_DTC" 0 "NOT_TESTED_DTC" ;
VAL_ 861 IBST_d179_dcomSmrtActuNotInit 3 "UNABLE_TO_TEST_DTC" 2 "FAILED_DTC" 1 "PASSED_DTC" 0 "NOT_TESTED_DTC" ;
VAL_ 861 IBST_d180_rpsLengthAbsolHigh 3 "UNABLE_TO_TEST_DTC" 2 "FAILED_DTC" 1 "PASSED_DTC" 0 "NOT_TESTED_DTC" ;
VAL_ 861 IBST_d181_rpsLengthAbsolLow 3 "UNABLE_TO_TEST_DTC" 2 "FAILED_DTC" 1 "PASSED_DTC" 0 "NOT_TESTED_DTC" ;
VAL_ 861 IBST_d182_shutDownEeReadFail 3 "UNABLE_TO_TEST_DTC" 2 "FAILED_DTC" 1 "PASSED_DTC" 0 "NOT_TESTED_DTC" ;
VAL_ 861 IBST_d183_shutDownEeWriteFail 3 "UNABLE_TO_TEST_DTC" 2 "FAILED_DTC" 1 "PASSED_DTC" 0 "NOT_TESTED_DTC" ;
VAL_ 861 IBST_d184_maxTrvlAdjstReadErr 3 "UNABLE_TO_TEST_DTC" 2 "FAILED_DTC" 1 "PASSED_DTC" 0 "NOT_TESTED_DTC" ;
VAL_ 861 IBST_d185_psOffsMcEeReadFail 3 "UNABLE_TO_TEST_DTC" 2 "FAILED_DTC" 1 "PASSED_DTC" 0 "NOT_TESTED_DTC" ;
VAL_ 861 IBST_d186_psOffsMcEeWriteFail 3 "UNABLE_TO_TEST_DTC" 2 "FAILED_DTC" 1 "PASSED_DTC" 0 "NOT_TESTED_DTC" ;
VAL_ 861 IBST_d187_ltmSelfProtDeact 3 "UNABLE_TO_TEST_DTC" 2 "FAILED_DTC" 1 "PASSED_DTC" 0 "NOT_TESTED_DTC" ;
VAL_ 861 IBST_d188_pts1OffsEeReadFail 3 "UNABLE_TO_TEST_DTC" 2 "FAILED_DTC" 1 "PASSED_DTC" 0 "NOT_TESTED_DTC" ;
VAL_ 861 IBST_d189_diffStrokeRange 3 "UNABLE_TO_TEST_DTC" 2 "FAILED_DTC" 1 "PASSED_DTC" 0 "NOT_TESTED_DTC" ;
VAL_ 861 IBST_d190_notProgVin 3 "UNABLE_TO_TEST_DTC" 2 "FAILED_DTC" 1 "PASSED_DTC" 0 "NOT_TESTED_DTC" ;
VAL_ 861 IBST_d191_plausVin 3 "UNABLE_TO_TEST_DTC" 2 "FAILED_DTC" 1 "PASSED_DTC" 0 "NOT_TESTED_DTC" ;
VAL_ 861 IBST_d192_dlCorCSumVin 3 "UNABLE_TO_TEST_DTC" 2 "FAILED_DTC" 1 "PASSED_DTC" 0 "NOT_TESTED_DTC" ;
VAL_ 861 IBST_d193_ToutVin 3 "UNABLE_TO_TEST_DTC" 2 "FAILED_DTC" 1 "PASSED_DTC" 0 "NOT_TESTED_DTC" ;
VAL_ 861 IBST_d194_ecuEnableB6Fail 3 "UNABLE_TO_TEST_DTC" 2 "FAILED_DTC" 1 "PASSED_DTC" 0 "NOT_TESTED_DTC" ;
VAL_ 861 IBST_d195_ecuIbEnContErr 3 "UNABLE_TO_TEST_DTC" 2 "FAILED_DTC" 1 "PASSED_DTC" 0 "NOT_TESTED_DTC" ;
VAL_ 861 IBST_d196_sclEspIb1pEstMax 3 "UNABLE_TO_TEST_DTC" 2 "FAILED_DTC" 1 "PASSED_DTC" 0 "NOT_TESTED_DTC" ;
VAL_ 861 IBST_d197_sclEspIb1VehSpd 3 "UNABLE_TO_TEST_DTC" 2 "FAILED_DTC" 1 "PASSED_DTC" 0 "NOT_TESTED_DTC" ;
VAL_ 861 IBST_d198_sclEspIb2pLimExt 3 "UNABLE_TO_TEST_DTC" 2 "FAILED_DTC" 1 "PASSED_DTC" 0 "NOT_TESTED_DTC" ;
VAL_ 861 IBST_d199_sclEspIb2qTarExt 3 "UNABLE_TO_TEST_DTC" 2 "FAILED_DTC" 1 "PASSED_DTC" 0 "NOT_TESTED_DTC" ;
VAL_ 861 IBST_d200_sclEspIb3pFBlend 3 "UNABLE_TO_TEST_DTC" 2 "FAILED_DTC" 1 "PASSED_DTC" 0 "NOT_TESTED_DTC" ;
VAL_ 861 IBST_d201_sclEspIb3pMc1 3 "UNABLE_TO_TEST_DTC" 2 "FAILED_DTC" 1 "PASSED_DTC" 0 "NOT_TESTED_DTC" ;
VAL_ 861 IBST_d202_sclEspIb3pTarDriver 3 "UNABLE_TO_TEST_DTC" 2 "FAILED_DTC" 1 "PASSED_DTC" 0 "NOT_TESTED_DTC" ;
VAL_ 861 IBST_d203_netBusOffNet0 3 "UNABLE_TO_TEST_DTC" 2 "FAILED_DTC" 1 "PASSED_DTC" 0 "NOT_TESTED_DTC" ;
VAL_ 861 IBST_d204_netErrPassivNet0 3 "UNABLE_TO_TEST_DTC" 2 "FAILED_DTC" 1 "PASSED_DTC" 0 "NOT_TESTED_DTC" ;
VAL_ 861 IBST_d205_netBusOffNet1 3 "UNABLE_TO_TEST_DTC" 2 "FAILED_DTC" 1 "PASSED_DTC" 0 "NOT_TESTED_DTC" ;
VAL_ 861 IBST_d206_netErrPassivNet1 3 "UNABLE_TO_TEST_DTC" 2 "FAILED_DTC" 1 "PASSED_DTC" 0 "NOT_TESTED_DTC" ;
VAL_ 861 IBST_d207_maxStrokeReached 3 "UNABLE_TO_TEST_DTC" 2 "FAILED_DTC" 1 "PASSED_DTC" 0 "NOT_TESTED_DTC" ;
VAL_ 861 IBST_d208_sysSwClockMismatch 3 "UNABLE_TO_TEST_DTC" 2 "FAILED_DTC" 1 "PASSED_DTC" 0 "NOT_TESTED_DTC" ;
VAL_ 861 IBST_d209_comsclGtwOdoCorrpt 3 "UNABLE_TO_TEST_DTC" 2 "FAILED_DTC" 1 "PASSED_DTC" 0 "NOT_TESTED_DTC" ;
VAL_ 861 IBST_d210_comsclGtwStatCorrpt 3 "UNABLE_TO_TEST_DTC" 2 "FAILED_DTC" 1 "PASSED_DTC" 0 "NOT_TESTED_DTC" ;
VAL_ 861 IBST_d211_comsclEpbStatCorrpt 3 "UNABLE_TO_TEST_DTC" 2 "FAILED_DTC" 1 "PASSED_DTC" 0 "NOT_TESTED_DTC" ;
VAL_ 861 IBST_d212_comsclGtwOdoTout 3 "UNABLE_TO_TEST_DTC" 2 "FAILED_DTC" 1 "PASSED_DTC" 0 "NOT_TESTED_DTC" ;
VAL_ 861 IBST_d213_comsclGtwStatTout 3 "UNABLE_TO_TEST_DTC" 2 "FAILED_DTC" 1 "PASSED_DTC" 0 "NOT_TESTED_DTC" ;
VAL_ 861 IBST_d214_comsclEpbStatTout 3 "UNABLE_TO_TEST_DTC" 2 "FAILED_DTC" 1 "PASSED_DTC" 0 "NOT_TESTED_DTC" ;
VAL_ 861 IBST_d215_comSclEpbStatCsErr 3 "UNABLE_TO_TEST_DTC" 2 "FAILED_DTC" 1 "PASSED_DTC" 0 "NOT_TESTED_DTC" ;
VAL_ 861 IBST_d216_comSclEpbStatCntFlt 3 "UNABLE_TO_TEST_DTC" 2 "FAILED_DTC" 1 "PASSED_DTC" 0 "NOT_TESTED_DTC" ;
VAL_ 861 IBST_d217_comSclDiTrq1Tout 3 "UNABLE_TO_TEST_DTC" 2 "FAILED_DTC" 1 "PASSED_DTC" 0 "NOT_TESTED_DTC" ;
VAL_ 861 IBST_d218_comSclDiTrq1Corrpt 3 "UNABLE_TO_TEST_DTC" 2 "FAILED_DTC" 1 "PASSED_DTC" 0 "NOT_TESTED_DTC" ;
VAL_ 861 IBST_d219_comSclDiTrq1CsErr 3 "UNABLE_TO_TEST_DTC" 2 "FAILED_DTC" 1 "PASSED_DTC" 0 "NOT_TESTED_DTC" ;
VAL_ 861 IBST_d220_comSclDiTrq1CntFlt 3 "UNABLE_TO_TEST_DTC" 2 "FAILED_DTC" 1 "PASSED_DTC" 0 "NOT_TESTED_DTC" ;
VAL_ 541 IBST_ebrMode 5 "FULL_SYSTEM" 4 "FAILED_OPERATIONAL" 3 "FAILED_DEGRADED" 2 "EMERGENCY_MODE" 1 "UNABLE_TO_EXECUTE" 0 "FAULTED" ;
VAL_ 541 IBST_ebrSystemMode 5 "FULL_SYSTEM" 4 "FAILED_OPERATIONAL" 3 "FAILED_DEGRADED" 2 "EMERGENCY_MODE" 1 "UNABLE_TO_EXECUTE" 0 "FAULTED" ;
VAL_ 541 IBST_brakeTorqueTarget 8191 "SNA" ;
VAL_ 541 IBST_ebrSource 1 "DAS_EBR" 0 "DI_EBR" ;
VAL_ 541 IBST_ebrState 2 "EBR_RELEASING_FOR_SKID" 1 "ACTIVE" 0 "INACTIVE" ;
VAL_ 813 IBST_infoIndex 255 "INFO_END" 22 "INFO_VARIANT_CRC" 20 "INFO_UDS_PROTOCOL_BOOTCRC" 19 "INFO_VERSION_DEPRECATED" 18 "INFO_BOOTLOADER_GITHASH" 17 "INFO_APP_GITHASH" 16 "INFO_SUBCOMPONENT" 15 "INFO_BOOTLOADER_CRC" 14 "INFO_BOOTLOADER_SVN" 13 "INFO_APP_CRC" 11 "INFO_PCBAID_ASSYID_USAGEID" 10 "INFO_BUILD_HWID_COMPONENTID" 9 "INFO_DEPRECATED_9" 8 "INFO_DEPRECATED_8" 7 "INFO_DEPRECATED_7" 6 "INFO_DEPRECATED_6" 5 "INFO_DEPRECATED_5" 4 "INFO_DEPRECATED_4" 3 "INFO_DEPRECATED_3" 2 "INFO_DEPRECATED_2" 1 "INFO_DEPRECATED_1" 0 "INFO_DEPRECATED_0" ;
VAL_ 925 IBST_iBoosterStatus 7 "IBOOSTER_READY" 6 "IBOOSTER_POST_RUN_REDUCED" 5 "IBOOSTER_REDUCED" 4 "IBOOSTER_STANDALONE" 3 "IBOOSTER_MAX_STROKE" 2 "IBOOSTER_DIAGNOSIS" 1 "IBOOSTER_FAILURE" 0 "IBOOSTER_NOT_INITIALIZED_OR_SUP" ;
VAL_ 925 IBST_brakeInputStroke 1023 "INPUT_STROKE_SNA" 1022 "INPUT_STROKE_NOT_VALID" ;

VAL_ 907 ESP_pEstMaxQF 2 "PESTMAX_FAULT" 1 "PESTMAX_NORMAL" 0 "PESTMAX_NOT_INITIALIZED" ;
VAL_ 907 ESP_vehicleSpeedQF 6 "SPEED_INV_UNDER_V" 5 "SPEED_NOT_CALC" 4 "SPEED_REDUCED_MON" 3 "SPEED_DIFF_CALC" 2 "SPEED_FAULT" 1 "SPEED_NORMAL" 0 "SPEED_NOT_INITIALIZED" ;
VAL_ 907 ESP_ignitionOn 1 "ESP_IGNITION_ON" 0 "ESP_IGNITION_OFF" ;
VAL_ 908 ESP_qTargetExternalQF 2 "QTARGET_EBR_MAX_PERFORMANCE" 1 "QTARGET_EBR" 0 "QTARGET_OFF" ;
VAL_ 908 ESP_diagnosticESP 1 "ESP_DIAGNOSTIC_MODE" 0 "ESP_NOT_IN_DIAGNOSTIC_MODE" ;
VAL_ 909 ESP_pTargetDriverQF 3 "PTARGETDRIVER_FAULT" 2 "PTARGETDRIVER_REDUCED_MONITORING" 1 "PTARGETDRIVER_NORMAL" 0 "PTARGETDRIVER_NOT_INITIALIZED" ;
VAL_ 909 ESP_absActive 1 "ABS_ACTIVE" 0 "ABS_NOT_ACTIVE" ;
VAL_ 909 ESP_pForceBlendingMCQF 2 "BLENDING_FAULT" 1 "BLENDING_NORMAL" 0 "BLENDING_NOT_INITIALIZED" ;
VAL_ 909 ESP_forceBlendingActive 2 "PFC_ACTIVE" 1 "PFC_HOLD" 0 "PFC_INACTVE" ;
VAL_ 909 ESP_pMC1QF 4 "PRESSURE_TEMP_FROZEN" 3 "PRESSURE_NOT_MONITORED" 2 "PRESSURE_FAULT" 1 "PRESSURE_NORMAL" 0 "PRESSURE_NOT_INITIALIZED" ;
VAL_ 910 IBST_extReqStatus 4 "EBR_ACTIVE_RESTRICTED" 3 "EBR_ACTIVE" 2 "EBR_AVAILABLE" 1 "EBR_NOT_AVAILABLE" 0 "EBR_NOT_INITIALIZED" ;
VAL_ 910 IBST_sOutputRodTargetQF 2 "OUTPUT_ROD_FAULT" 1 "OUTPUT_ROD_NORMAL" 0 "OUTPUT_ROD_NOT_INITIALIZED" ;
VAL_ 911 IBST_pForceBlendingPotentialQF 2 "BLENDING_POTENTIAL_FAULT" 1 "BLENDING_POTENTIAL_NORMAL" 0 "BLENDING_POTENTIAL_NOT_INIT" ;
VAL_ 911 IBST_brakePedalApplied 1 "BRAKE_PEDAL_APPLIED" 0 "BRAKE_PEDAL_NOT_APPLIED" ;
VAL_ 911 IBST_brakePedalAppliedQF 2 "BRAKE_PEDAL_APPLIED_FAULT" 1 "BRAKE_PEDAL_APPLIED_NORMAL" 0 "BRAKE_PEDAL_APPLIED_OFF" ;
VAL_ 911 IBST_status 7 "IBOOSTER_READY" 6 "IBOOSTER_POST_RUN_REDUCED" 5 "IBOOSTER_REDUCED" 4 "IBOOSTER_STANDALONE" 3 "IBOOSTER_UNDEFINED_1" 2 "IBOOSTER_DIAGNOSTIC" 1 "IBOOSTER_FAULT" 0 "IBOOSTER_NOT_INITIALIZED" ;
VAL_ 911 IBST_pRunoutQF 2 "RUNNOUT_FAULT" 1 "RUNNOUT_NORMAL" 0 "RUNNOUT_NOT_INITIALIZED" ;
VAL_ 913 IBST_ebrMode 5 "FULL_SYSTEM" 4 "FAILED_OPERATIONAL" 3 "FAILED_DEGRADED" 2 "EMERGENCY_MODE" 1 "UNABLE_TO_EXECUTE" 0 "FAULTED" ;
VAL_ 913 IBST_ebrSystemMode 5 "FULL_SYSTEM" 4 "FAILED_OPERATIONAL" 3 "FAILED_DEGRADED" 2 "EMERGENCY_MODE" 1 "UNABLE_TO_EXECUTE" 0 "FAULTED" ;
VAL_ 913 IBST_brakeTorqueTarget 8191 "SNA" ;
VAL_ 913 IBST_ebrSource 1 "DAS_EBR" 0 "DI_EBR" ;
VAL_ 913 IBST_ebrState 2 "EBR_RELEASING_FOR_SKID" 1 "ACTIVE" 0 "INACTIVE" ;
